VERSION ""

NS_ :

BS_:

BU_: WSGW VCM TBIOM RCIOM FCIOM CCIOM BPMU

BO_ 517 RCIOM_Chassi_01P: 8 RCIOM
 SG_ FrontProhibitControlRequest : 4|2@1+ (1,0) [0|0] ""  CCIOM,VCM
 SG_ RampLevelStorageAck_ISig_4 : 24|2@1+ (1,0) [0|0] ""  VCM
 SG_ BrakePressureSensorDemand_UB_ISi : 1|1@1+ (1,0) [0|0] ""  VCM
 SG_ FrontLimpHomeCmd : 50|3@1+ (1,0) [0|0] ""  VCM,CCIOM
 SG_ LiftingControlModeRearAxle : 18|2@1+ (1,0) [0|0] ""  VCM
 SG_ LoadDistributionChangeACK_ISig_4 : 56|3@1+ (1,0) [0|0] ""  VCM
 SG_ ECSStandbyAllowed_ISig_4 : 32|2@1+ (1,0) [0|0] ""  VCM
 SG_ LiftAxle2LiftFuncSelected_ISig_4 : 59|3@1+ (1,0) [0|0] ""  VCM
 SG_ LiftAxle2UpRequestACK_ISig_4 : 34|3@1+ (1,0) [0|0] ""  VCM
 SG_ ProhibitControlStatus_ISig_4 : 62|2@1+ (1,0) [0|0] ""  VCM
 SG_ RampLevelStatus_ISig_4 : 46|4@1+ (1,0) [0|0] ""  VCM
 SG_ StopLevelChangeAck_ISig_4 : 16|2@1+ (1,0) [0|0] ""  VCM
 SG_ LiftAxle2LowerACK_ISig_4 : 37|3@1+ (1,0) [0|0] ""  VCM
 SG_ RideHeightStorageAck_ISig_4 : 6|2@1+ (1,0) [0|0] ""  VCM
 SG_ FrontParkBrakeOverrideCommand : 22|2@1+ (1,0) [0|0] ""  VCM
 SG_ RideHeightOutsideTargetRange_ISi : 43|3@1+ (1,0) [0|0] ""  VCM
 SG_ DisableMechFaultDctnFr_rqst : 26|2@1+ (1,0) [0|0] ""  VCM,CCIOM
 SG_ RearAxleInBumperRange_UB_ISig_4 : 0|1@1+ (1,0) [0|0] ""  VCM
 SG_ BrakePressureSensorDemand_ISig_4 : 8|8@1+ (1,0) [0|255] "Percent"  VCM
 SG_ FogLamp_Rear_Status : 20|2@1+ (1,0) [0|0] ""  VCM
 SG_ LiftingControlModeFrontAxle : 2|2@1+ (1,0) [0|0] ""  VCM
 SG_ LiftAxle1UpRequestACK_ISig_4 : 40|3@1+ (1,0) [0|0] ""  VCM
 SG_ LiftAxle1LiftFuncSelected_ISig_4 : 53|3@1+ (1,0) [0|0] ""  VCM
 SG_ RearAxleInBumperRange_ISig_4 : 30|2@1+ (1,0) [0|0] ""  VCM

BO_ 2671833715 PhysDiagRespMsg_F2_73_C04: 8 WSGW
 SG_ PhysDiagRespSig_F2_73_ISig_4 : 0|64@1+ (1,0) [0|0] ""  VCM

BO_ 2671833639 PhysDiagRespMsg_F2_27_C04: 8 TBIOM
 SG_ PhysDiagRespSig_F2_27_ISig_4 : 0|64@1+ (1,0) [0|0] ""  VCM

BO_ 2671833634 PhysDiagRespMsg_F2_22_C04: 8 RCIOM
 SG_ PhysDiagRespSig_F2_22_ISig_4 : 0|64@1+ (1,0) [0|0] ""  VCM

BO_ 2671833633 PhysDiagRespMsg_F2_21_C04: 8 FCIOM
 SG_ PhysDiagRespSig_F2_21_ISig_4 : 0|64@1+ (1,0) [0|0] ""  VCM

BO_ 2671833632 PhysDiagRespMsg_F2_20_C04: 8 CCIOM
 SG_ PhysDiagRespSig_F2_20_ISig_4 : 0|64@1+ (1,0) [0|0] ""  VCM

BO_ 2671833626 PhysDiagRespMsg_F2_1A_C04: 8 BPMU
 SG_ PhysDiagRespSig_F2_1A_ISig_4 : 0|64@1+ (1,0) [0|0] ""  VCM

BO_ 2671801330 PhysDiagReqMsg_73_F2_C04: 8 VCM
 SG_ PhysDiagReqSig_73_F2_ISig_4 : 0|64@1+ (1,0) [0|0] ""  WSGW

BO_ 2671781874 PhysDiagReqMsg_27_F2_C04: 8 VCM
 SG_ PhysDiagReqSig_27_F2_ISig_4 : 0|64@1+ (1,0) [0|0] ""  TBIOM

BO_ 2671780594 PhysDiagReqMsg_22_F2_C04: 8 VCM
 SG_ PhysDiagReqSig_22_F2_ISig_4 : 0|64@1+ (1,0) [0|0] ""  RCIOM

BO_ 2671780338 PhysDiagReqMsg_21_F2_C04: 8 VCM
 SG_ PhysDiagReqSig_21_F2_ISig_4 : 0|64@1+ (1,0) [0|0] ""  FCIOM

BO_ 2671780082 PhysDiagReqMsg_20_F2_C04: 8 VCM
 SG_ PhysDiagReqSig_20_F2_ISig_4 : 0|64@1+ (1,0) [0|0] ""  CCIOM

BO_ 2671778546 PhysDiagReqMsg_1A_F2_C04: 8 VCM
 SG_ PhysDiagReqSig_1A_F2_ISig_4 : 0|64@1+ (1,0) [0|0] ""  BPMU

BO_ 2633990259 NmAsr_WSGW_C04: 1 WSGW

BO_ 2633990180 NmAsr_VCM_C04: 1 VCM

BO_ 2633990183 NmAsr_TBIOM_C04: 1 TBIOM

BO_ 2633990178 NmAsr_RCIOM_C04: 1 RCIOM

BO_ 2633990177 NmAsr_FCIOM_C04: 1 FCIOM

BO_ 2633990176 NmAsr_CCIOM_C04: 1 CCIOM

BO_ 2633990170 NmAsr_BPMU_C04: 1 BPMU

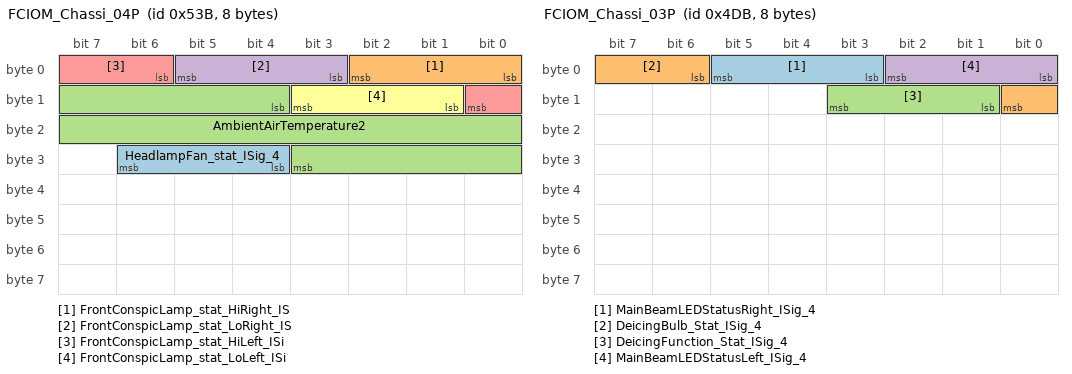
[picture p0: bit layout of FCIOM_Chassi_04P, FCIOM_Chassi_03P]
BO_ 1339 FCIOM_Chassi_04P: 8 FCIOM
 SG_ HeadlampFan_stat_ISig_4 : 28|3@1+ (1,0) [0|0] ""  VCM
 SG_ FrontConspicLamp_stat_HiRight_IS : 0|3@1+ (1,0) [0|0] ""  VCM
 SG_ AmbientAirTemperature2 : 12|16@1+ (0.03125,-273) [-273|1774.96875] "DegreeC"  VCM
 SG_ FrontConspicLamp_stat_LoRight_IS : 3|3@1+ (1,0) [0|0] ""  VCM
 SG_ FrontConspicLamp_stat_HiLeft_ISi : 6|3@1+ (1,0) [0|0] ""  VCM
 SG_ FrontConspicLamp_stat_LoLeft_ISi : 9|3@1+ (1,0) [0|0] ""  VCM

BO_ 1243 FCIOM_Chassi_03P: 8 FCIOM
 SG_ MainBeamLEDStatusRight_ISig_4 : 3|3@1+ (1,0) [0|0] ""  VCM
 SG_ DeicingBulb_Stat_ISig_4 : 6|3@1+ (1,0) [0|0] ""  VCM
 SG_ DeicingFunction_Stat_ISig_4 : 9|3@1+ (1,0) [0|0] ""  VCM
 SG_ MainBeamLEDStatusLeft_ISig_4 : 0|3@1+ (1,0) [0|0] ""  VCM

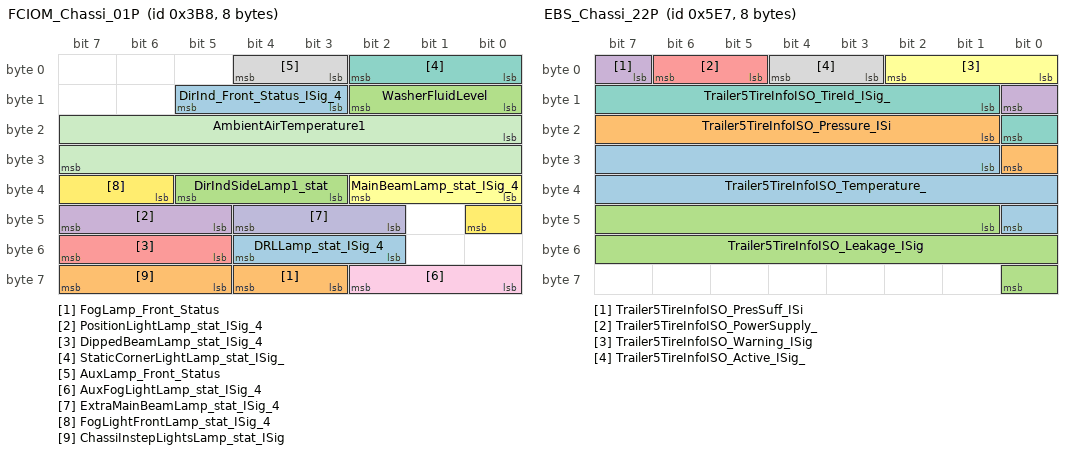
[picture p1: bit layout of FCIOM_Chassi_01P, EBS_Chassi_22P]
BO_ 952 FCIOM_Chassi_01P: 8 FCIOM
 SG_ DRLLamp_stat_ISig_4 : 50|3@1+ (1,0) [0|0] ""  VCM
 SG_ FogLamp_Front_Status : 59|2@1+ (1,0) [0|0] ""  VCM
 SG_ DirIndSideLamp1_stat : 35|3@1+ (1,0) [0|0] ""  VCM
 SG_ PositionLightLamp_stat_ISig_4 : 45|3@1+ (1,0) [0|0] ""  VCM
 SG_ DippedBeamLamp_stat_ISig_4 : 53|3@1+ (1,0) [0|0] ""  VCM
 SG_ MainBeamLamp_stat_ISig_4 : 32|3@1+ (1,0) [0|0] ""  VCM
 SG_ StaticCornerLightLamp_stat_ISig_ : 0|3@1+ (1,0) [0|0] ""  VCM
 SG_ AuxLamp_Front_Status : 3|2@1+ (1,0) [0|0] ""  VCM
 SG_ AuxFogLightLamp_stat_ISig_4 : 56|3@1+ (1,0) [0|0] ""  VCM
 SG_ ExtraMainBeamLamp_stat_ISig_4 : 42|3@1+ (1,0) [0|0] ""  VCM
 SG_ AmbientAirTemperature1 : 16|16@1+ (0.03125,-273) [-273|1774.96875] "DegreeC"  VCM
 SG_ FogLightFrontLamp_stat_ISig_4 : 38|3@1+ (1,0) [0|0] ""  VCM
 SG_ DirInd_Front_Status_ISig_4 : 11|3@1+ (1,0) [0|0] ""  VCM
 SG_ ChassiInstepLightsLamp_stat_ISig : 61|3@1+ (1,0) [0|0] ""  VCM
 SG_ WasherFluidLevel : 8|3@1+ (1,0) [0|0] ""  VCM

BO_ 1511 EBS_Chassi_22P: 8 VCM
 SG_ Trailer5TireInfoISO_Temperature_ : 25|16@1+ (0.03125,-273) [-273|1774.96875] "DegreeC"  WSGW
 SG_ Trailer5TireInfoISO_Pressure_ISi : 17|8@1+ (10,0) [0|2550] "kPa"  WSGW
 SG_ Trailer5TireInfoISO_Leakage_ISig : 41|16@1+ (0.1,0) [0|6553.5] "Pa_per_s"  WSGW
 SG_ Trailer5TireInfoISO_PresSuff_ISi : 7|2@1+ (1,0) [0|0] ""  WSGW
 SG_ Trailer5TireInfoISO_PowerSupply_ : 5|2@1+ (1,0) [0|0] ""  WSGW
 SG_ Trailer5TireInfoISO_Warning_ISig : 0|3@1+ (1,0) [0|0] ""  WSGW
 SG_ Trailer5TireInfoISO_TireId_ISig_ : 9|8@1+ (1,0) [0|255] "NotApplicable"  WSGW
 SG_ Trailer5TireInfoISO_Active_ISig_ : 3|2@1+ (1,0) [0|0] ""  WSGW

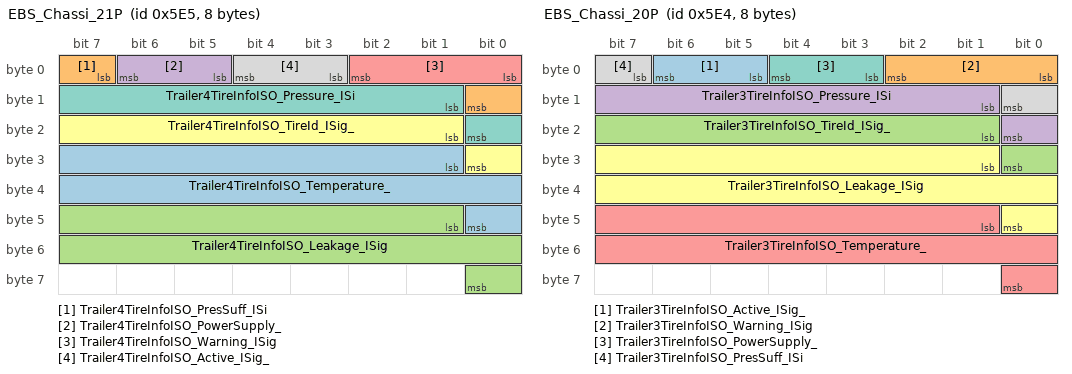
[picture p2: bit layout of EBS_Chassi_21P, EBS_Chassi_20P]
BO_ 1509 EBS_Chassi_21P: 8 VCM
 SG_ Trailer4TireInfoISO_Temperature_ : 25|16@1+ (0.03125,-273) [-273|1774.96875] "DegreeC"  WSGW
 SG_ Trailer4TireInfoISO_PresSuff_ISi : 7|2@1+ (1,0) [0|0] ""  WSGW
 SG_ Trailer4TireInfoISO_Leakage_ISig : 41|16@1+ (0.1,0) [0|6553.5] "Pa_per_s"  WSGW
 SG_ Trailer4TireInfoISO_PowerSupply_ : 5|2@1+ (1,0) [0|0] ""  WSGW
 SG_ Trailer4TireInfoISO_Warning_ISig : 0|3@1+ (1,0) [0|0] ""  WSGW
 SG_ Trailer4TireInfoISO_TireId_ISig_ : 17|8@1+ (1,0) [0|255] "NotApplicable"  WSGW
 SG_ Trailer4TireInfoISO_Pressure_ISi : 9|8@1+ (10,0) [0|2550] "kPa"  WSGW
 SG_ Trailer4TireInfoISO_Active_ISig_ : 3|2@1+ (1,0) [0|0] ""  WSGW

BO_ 1508 EBS_Chassi_20P: 8 VCM
 SG_ Trailer3TireInfoISO_Active_ISig_ : 5|2@1+ (1,0) [0|0] ""  WSGW
 SG_ Trailer3TireInfoISO_Warning_ISig : 0|3@1+ (1,0) [0|0] ""  WSGW
 SG_ Trailer3TireInfoISO_TireId_ISig_ : 17|8@1+ (1,0) [0|255] "NotApplicable"  WSGW
 SG_ Trailer3TireInfoISO_Pressure_ISi : 9|8@1+ (10,0) [0|2550] "kPa"  WSGW
 SG_ Trailer3TireInfoISO_Temperature_ : 41|16@1+ (0.03125,-273) [-273|1774.96875] "DegreeC"  WSGW
 SG_ Trailer3TireInfoISO_Leakage_ISig : 25|16@1+ (0.1,0) [0|6553.5] "Pa_per_s"  WSGW
 SG_ Trailer3TireInfoISO_PowerSupply_ : 3|2@1+ (1,0) [0|0] ""  WSGW
 SG_ Trailer3TireInfoISO_PresSuff_ISi : 7|2@1+ (1,0) [0|0] ""  WSGW

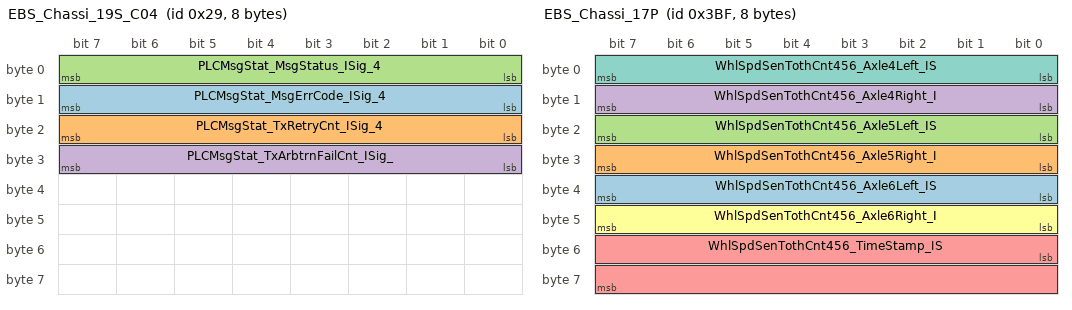
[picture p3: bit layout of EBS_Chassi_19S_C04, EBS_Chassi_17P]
BO_ 41 EBS_Chassi_19S_C04: 8 VCM
 SG_ PLCMsgStat_MsgErrCode_ISig_4 : 8|8@1+ (1,0) [0|255] "NotApplicable"  WSGW
 SG_ PLCMsgStat_TxRetryCnt_ISig_4 : 16|8@1+ (1,0) [0|255] "NotApplicable"  WSGW
 SG_ PLCMsgStat_MsgStatus_ISig_4 : 0|8@1+ (1,0) [0|255] "NotApplicable"  WSGW
 SG_ PLCMsgStat_TxArbtrnFailCnt_ISig_ : 24|8@1+ (1,0) [0|255] "NotApplicable"  WSGW

BO_ 1506 EBS_Chassi_18S_C04_FCM: 8 WSGW
 SG_ EBS_Chassi_18S_FCS : 0|64@1+ (1,0) [0|0] ""  VCM

BO_ 1505 EBS_Chassi_18S_C04: 21 VCM
 SG_ PhyDiagBrk2TPMReqSig_ISig_4 : 0|168@1+ (1,0) [0|0] ""  WSGW

BO_ 959 EBS_Chassi_17P: 8 VCM
 SG_ WhlSpdSenTothCnt456_Axle6Left_IS : 32|8@1+ (1,0) [0|255] "Count"  WSGW
 SG_ WhlSpdSenTothCnt456_Axle5Right_I : 24|8@1+ (1,0) [0|255] "Count"  WSGW
 SG_ WhlSpdSenTothCnt456_Axle5Left_IS : 16|8@1+ (1,0) [0|255] "Count"  WSGW
 SG_ WhlSpdSenTothCnt456_Axle4Right_I : 8|8@1+ (1,0) [0|255] "Count"  WSGW
 SG_ WhlSpdSenTothCnt456_TimeStamp_IS : 48|16@1+ (1,0) [0|65535] ""  WSGW
 SG_ WhlSpdSenTothCnt456_Axle6Right_I : 40|8@1+ (1,0) [0|255] "Count"  WSGW
 SG_ WhlSpdSenTothCnt456_Axle4Left_IS : 0|8@1+ (1,0) [0|255] "Count"  WSGW

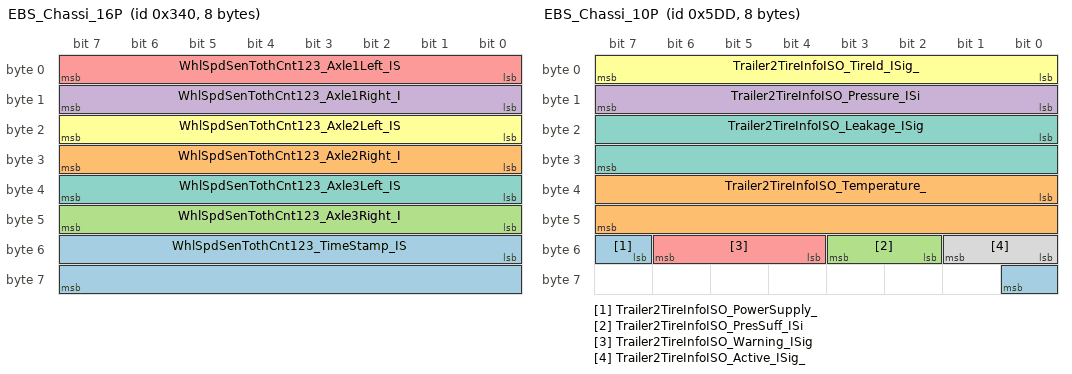
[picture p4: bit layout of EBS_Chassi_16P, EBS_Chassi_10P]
BO_ 832 EBS_Chassi_16P: 8 VCM
 SG_ WhlSpdSenTothCnt123_TimeStamp_IS : 48|16@1+ (1,0) [0|65535] ""  WSGW
 SG_ WhlSpdSenTothCnt123_Axle2Right_I : 24|8@1+ (1,0) [0|255] "Count"  WSGW
 SG_ WhlSpdSenTothCnt123_Axle3Right_I : 40|8@1+ (1,0) [0|255] "Count"  WSGW
 SG_ WhlSpdSenTothCnt123_Axle1Right_I : 8|8@1+ (1,0) [0|255] "Count"  WSGW
 SG_ WhlSpdSenTothCnt123_Axle1Left_IS : 0|8@1+ (1,0) [0|255] "Count"  WSGW
 SG_ WhlSpdSenTothCnt123_Axle2Left_IS : 16|8@1+ (1,0) [0|255] "Count"  WSGW
 SG_ WhlSpdSenTothCnt123_Axle3Left_IS : 32|8@1+ (1,0) [0|255] "Count"  WSGW

BO_ 1232 EBS_Chassi_13P: 8 VCM
 SG_ TrailerCommunicationType_ISig_4 : 26|3@1+ (1,0) [0|0] ""  RCIOM

BO_ 1507 EBS_Chassi_12P: 8 VCM
 SG_ PLCBusStatus_ISig_4 : 16|8@1+ (1,0) [0|255] "NotApplicable"  WSGW

BO_ 1501 EBS_Chassi_10P: 8 VCM
 SG_ Trailer2TireInfoISO_PowerSupply_ : 55|2@1+ (1,0) [0|0] ""  WSGW
 SG_ Trailer2TireInfoISO_Temperature_ : 32|16@1+ (0.03125,-273) [-273|1774.96875] "DegreeC"  WSGW
 SG_ Trailer2TireInfoISO_PresSuff_ISi : 50|2@1+ (1,0) [0|0] ""  WSGW
 SG_ Trailer2TireInfoISO_Pressure_ISi : 8|8@1+ (10,0) [0|2550] "kPa"  WSGW
 SG_ Trailer2TireInfoISO_Warning_ISig : 52|3@1+ (1,0) [0|0] ""  WSGW
 SG_ Trailer2TireInfoISO_TireId_ISig_ : 0|8@1+ (1,0) [0|255] "NotApplicable"  WSGW
 SG_ Trailer2TireInfoISO_Leakage_ISig : 16|16@1+ (0.1,0) [0|6553.5] "Pa_per_s"  WSGW
 SG_ Trailer2TireInfoISO_Active_ISig_ : 48|2@1+ (1,0) [0|0] ""  WSGW

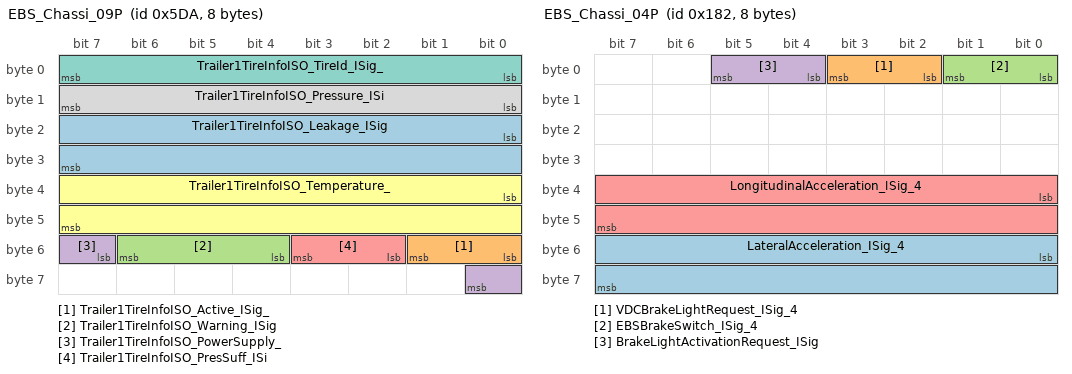
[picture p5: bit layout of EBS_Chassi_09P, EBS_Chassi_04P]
BO_ 1498 EBS_Chassi_09P: 8 VCM
 SG_ Trailer1TireInfoISO_Leakage_ISig : 16|16@1+ (0.1,0) [0|6553.5] "Pa_per_s"  WSGW
 SG_ Trailer1TireInfoISO_Active_ISig_ : 48|2@1+ (1,0) [0|0] ""  WSGW
 SG_ Trailer1TireInfoISO_Warning_ISig : 52|3@1+ (1,0) [0|0] ""  WSGW
 SG_ Trailer1TireInfoISO_PowerSupply_ : 55|2@1+ (1,0) [0|0] ""  WSGW
 SG_ Trailer1TireInfoISO_PresSuff_ISi : 50|2@1+ (1,0) [0|0] ""  WSGW
 SG_ Trailer1TireInfoISO_Temperature_ : 32|16@1+ (0.03125,-273) [-273|1774.96875] "DegreeC"  WSGW
 SG_ Trailer1TireInfoISO_TireId_ISig_ : 0|8@1+ (1,0) [0|255] "NotApplicable"  WSGW
 SG_ Trailer1TireInfoISO_Pressure_ISi : 8|8@1+ (10,0) [0|2550] "kPa"  WSGW

BO_ 396 EBS_Chassi_08P: 8 VCM
 SG_ ThrdRrDriveAxLeftWheelSpeed_ISig : 32|16@1+ (0.00390625,0) [0|255.99609375] "Km_per_h"  RCIOM
 SG_ ThrdRrDriveAxRightWheelSpeed_ISi : 48|16@1+ (0.00390625,0) [0|255.99609375] "Km_per_h"  RCIOM

BO_ 395 EBS_Chassi_07P: 8 VCM
 SG_ SteeringWheelAngle_ISig_4 : 0|16@1+ (0.0009765625,-31.374) [-31.374|32.6250234375] "rad"  RCIOM
 SG_ SteeringWheelAngle_UB_ISig_4 : 48|1@1+ (1,0) [0|0] ""  RCIOM

BO_ 394 EBS_Chassi_06P: 8 VCM
 SG_ ScndRrDriveAxleLeftWheelSpeed_IS : 48|16@1+ (0.00390625,0) [0|255.99609375] "Km_per_h"  CCIOM,RCIOM
 SG_ ScndRrDriveAxleRightWheelSpeed_I : 0|16@1+ (0.00390625,0) [0|255.99609375] "Km_per_h"  RCIOM,CCIOM

BO_ 386 EBS_Chassi_04P: 8 VCM
 SG_ LateralAcceleration_ISig_4 : 48|16@1+ (0.00048828125,-15.687) [-15.687|16.31251171875] "m_per_s_squared"  RCIOM
 SG_ VDCBrakeLightRequest_ISig_4 : 2|2@1+ (1,0) [0|0] ""  RCIOM
 SG_ EBSBrakeSwitch_ISig_4 : 0|2@1+ (1,0) [0|0] ""  RCIOM
 SG_ BrakeLightActivationRequest_ISig : 4|2@1+ (1,0) [0|0] ""  RCIOM
 SG_ LongitudinalAcceleration_ISig_4 : 32|16@1+ (0.00048828125,-15.687) [-15.687|16.31251171875] "m_per_s_squared"  RCIOM

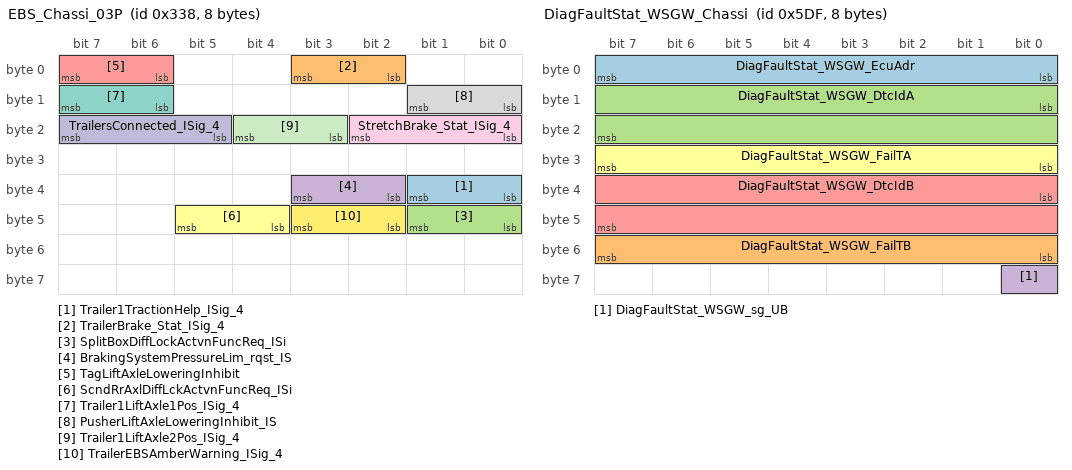
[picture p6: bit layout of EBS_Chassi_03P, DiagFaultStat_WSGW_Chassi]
BO_ 824 EBS_Chassi_03P: 8 VCM
 SG_ Trailer1TractionHelp_ISig_4 : 32|2@1+ (1,0) [0|0] ""  RCIOM
 SG_ TrailerBrake_Stat_ISig_4 : 2|2@1+ (1,0) [0|0] ""  RCIOM
 SG_ SplitBoxDiffLockActvnFuncReq_ISi : 40|2@1+ (1,0) [0|0] ""  CCIOM
 SG_ BrakingSystemPressureLim_rqst_IS : 34|2@1+ (1,0) [0|0] ""  CCIOM
 SG_ TagLiftAxleLoweringInhibit : 6|2@1+ (1,0) [0|0] ""  RCIOM
 SG_ ScndRrAxlDiffLckActvnFuncReq_ISi : 44|2@1+ (1,0) [0|0] ""  RCIOM
 SG_ Trailer1LiftAxle1Pos_ISig_4 : 14|2@1+ (1,0) [0|0] ""  RCIOM
 SG_ PusherLiftAxleLoweringInhibit_IS : 8|2@1+ (1,0) [0|0] ""  RCIOM
 SG_ StretchBrake_Stat_ISig_4 : 16|3@1+ (1,0) [0|0] ""  RCIOM
 SG_ TrailersConnected_ISig_4 : 21|3@1+ (1,0) [0|7] "Count"  RCIOM
 SG_ Trailer1LiftAxle2Pos_ISig_4 : 19|2@1+ (1,0) [0|0] ""  RCIOM
 SG_ TrailerEBSAmberWarning_ISig_4 : 42|2@1+ (1,0) [0|0] ""  RCIOM

BO_ 516 EAS_Chassi_01P: 8 VCM
 SG_ EASPusherLiftAxleLoweringInhib : 32|2@1+ (1,0) [0|0] ""  RCIOM

BO_ 2671964787 DiagUUDTRespMsg1_F2_73_C04: 8 WSGW
 SG_ DiagUUDTRespSig_F2_73_ISig_4 : 0|64@1+ (1,0) [0|0] ""  VCM

BO_ 2671964711 DiagUUDTRespMsg1_F2_27_C04: 8 TBIOM
 SG_ DiagUUDTRespSig_F2_27_ISig_4 : 0|64@1+ (1,0) [0|0] ""  VCM

BO_ 2671964706 DiagUUDTRespMsg1_F2_22_C04: 8 RCIOM
 SG_ DiagUUDTRespSig_F2_22_ISig_4 : 0|64@1+ (1,0) [0|0] ""  VCM

BO_ 2671964705 DiagUUDTRespMsg1_F2_21_C04: 8 FCIOM
 SG_ DiagUUDTRespSig_F2_21_ISig_4 : 0|64@1+ (1,0) [0|0] ""  VCM

BO_ 2671964704 DiagUUDTRespMsg1_F2_20_C04: 8 CCIOM
 SG_ DiagUUDTRespSig_F2_20_ISig_4 : 0|64@1+ (1,0) [0|0] ""  VCM

BO_ 2671964698 DiagUUDTRespMsg1_F2_1A_C04: 8 BPMU
 SG_ DiagUUDTRespSig_F2_1A_ISig_4 : 0|64@1+ (1,0) [0|0] ""  VCM

BO_ 2671834227 DiagRespMsgForIntTest_F4_73_C04: 8 WSGW
 SG_ InternalTesterDiagSig_F4_73 : 0|64@1+ (1,0) [0|0] ""  VCM

BO_ 2671834151 DiagRespMsgForIntTest_F4_27_C04: 8 TBIOM
 SG_ InternalTesterDiagSig_F4_27 : 0|64@1+ (1,0) [0|0] ""  VCM

BO_ 2671834146 DiagRespMsgForIntTest_F4_22_C04: 8 RCIOM
 SG_ InternalTesterDiagSig_F4_22 : 0|64@1+ (1,0) [0|0] ""  VCM

BO_ 2671834145 DiagRespMsgForIntTest_F4_21_C04: 8 FCIOM
 SG_ InternalTesterDiagSig_F4_21 : 0|64@1+ (1,0) [0|0] ""  VCM

BO_ 2671834144 DiagRespMsgForIntTest_F4_20_C04: 8 CCIOM
 SG_ InternalTesterDiagSig_F4_20 : 0|64@1+ (1,0) [0|0] ""  VCM

BO_ 2671834138 DiagRespMsgForIntTest_F4_1A_C04: 8 BPMU
 SG_ InternalTesterDiagSig_F4_1A : 0|64@1+ (1,0) [0|0] ""  VCM

BO_ 2671801332 DiagReqMsgOfIntTest_73_F4_C04: 8 VCM
 SG_ InternalTesterDiagSig_73_F4 : 0|64@1+ (1,0) [0|0] ""  WSGW

BO_ 2671781876 DiagReqMsgOfIntTest_27_F4_C04: 8 VCM
 SG_ InternalTesterDiagSig_27_F4 : 0|64@1+ (1,0) [0|0] ""  TBIOM

BO_ 2671780596 DiagReqMsgOfIntTest_22_F4_C04: 8 VCM
 SG_ InternalTesterDiagSig_22_F4 : 0|64@1+ (1,0) [0|0] ""  RCIOM

BO_ 2671780340 DiagReqMsgOfIntTest_21_F4_C04: 8 VCM
 SG_ InternalTesterDiagSig_21_F4 : 0|64@1+ (1,0) [0|0] ""  FCIOM

BO_ 2671780084 DiagReqMsgOfIntTest_20_F4_C04: 8 VCM
 SG_ InternalTesterDiagSig_20_F4 : 0|64@1+ (1,0) [0|0] ""  CCIOM

BO_ 2671778548 DiagReqMsgOfIntTest_1A_F4_C04: 8 VCM
 SG_ InternalTesterDiagSig_1A_F4 : 0|64@1+ (1,0) [0|0] ""  BPMU

BO_ 1503 DiagFaultStat_WSGW_Chassi: 8 WSGW
 SG_ DiagFaultStat_WSGW_EcuAdr : 0|8@1+ (1,0) [0|255] ""  VCM
 SG_ DiagFaultStat_WSGW_FailTB : 48|8@1+ (1,0) [0|255] ""  VCM
 SG_ DiagFaultStat_WSGW_DtcIdA : 8|16@1+ (1,0) [0|65535] ""  VCM
 SG_ DiagFaultStat_WSGW_sg_UB : 56|1@1+ (1,0) [0|0] ""  VCM
 SG_ DiagFaultStat_WSGW_DtcIdB : 32|16@1+ (1,0) [0|65535] ""  VCM
 SG_ DiagFaultStat_WSGW_FailTA : 24|8@1+ (1,0) [0|255] ""  VCM

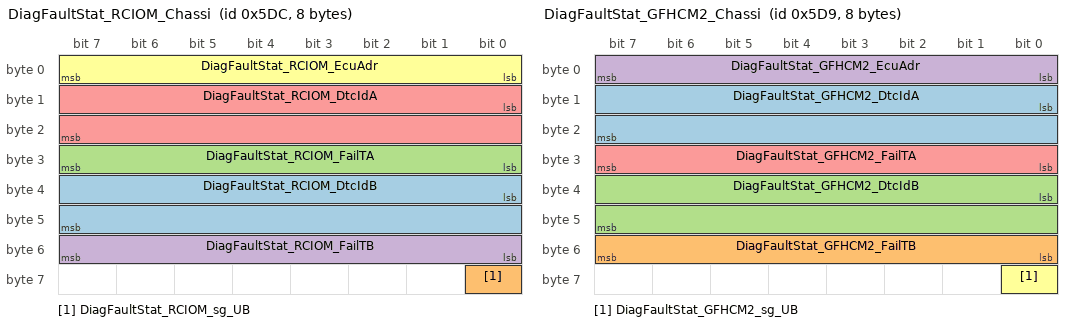
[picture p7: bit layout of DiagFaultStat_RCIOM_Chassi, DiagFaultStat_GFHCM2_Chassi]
BO_ 1500 DiagFaultStat_RCIOM_Chassi: 8 RCIOM
 SG_ DiagFaultStat_RCIOM_DtcIdB : 32|16@1+ (1,0) [0|65535] ""  VCM
 SG_ DiagFaultStat_RCIOM_sg_UB : 56|1@1+ (1,0) [0|0] ""  VCM
 SG_ DiagFaultStat_RCIOM_FailTA : 24|8@1+ (1,0) [0|255] ""  VCM
 SG_ DiagFaultStat_RCIOM_FailTB : 48|8@1+ (1,0) [0|255] ""  VCM
 SG_ DiagFaultStat_RCIOM_DtcIdA : 8|16@1+ (1,0) [0|65535] ""  VCM
 SG_ DiagFaultStat_RCIOM_EcuAdr : 0|8@1+ (1,0) [0|255] ""  VCM

BO_ 1497 DiagFaultStat_GFHCM2_Chassi: 8 FCIOM
 SG_ DiagFaultStat_GFHCM2_DtcIdA : 8|16@1+ (1,0) [0|65535] ""  VCM
 SG_ DiagFaultStat_GFHCM2_FailTB : 48|8@1+ (1,0) [0|255] ""  VCM
 SG_ DiagFaultStat_GFHCM2_DtcIdB : 32|16@1+ (1,0) [0|65535] ""  VCM
 SG_ DiagFaultStat_GFHCM2_EcuAdr : 0|8@1+ (1,0) [0|255] ""  VCM
 SG_ DiagFaultStat_GFHCM2_FailTA : 24|8@1+ (1,0) [0|255] ""  VCM
 SG_ DiagFaultStat_GFHCM2_sg_UB : 56|1@1+ (1,0) [0|0] ""  VCM

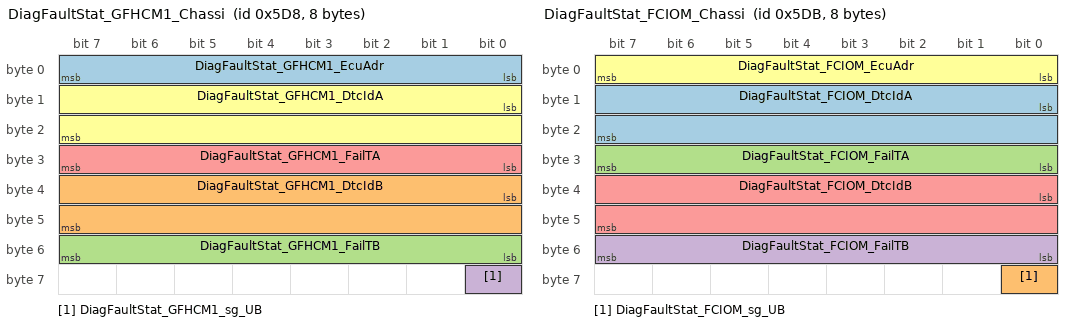
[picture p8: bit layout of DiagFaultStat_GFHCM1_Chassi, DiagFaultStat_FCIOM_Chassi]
BO_ 1496 DiagFaultStat_GFHCM1_Chassi: 8 FCIOM
 SG_ DiagFaultStat_GFHCM1_EcuAdr : 0|8@1+ (1,0) [0|255] ""  VCM
 SG_ DiagFaultStat_GFHCM1_DtcIdB : 32|16@1+ (1,0) [0|65535] ""  VCM
 SG_ DiagFaultStat_GFHCM1_FailTB : 48|8@1+ (1,0) [0|255] ""  VCM
 SG_ DiagFaultStat_GFHCM1_sg_UB : 56|1@1+ (1,0) [0|0] ""  VCM
 SG_ DiagFaultStat_GFHCM1_FailTA : 24|8@1+ (1,0) [0|255] ""  VCM
 SG_ DiagFaultStat_GFHCM1_DtcIdA : 8|16@1+ (1,0) [0|65535] ""  VCM

BO_ 1499 DiagFaultStat_FCIOM_Chassi: 8 FCIOM
 SG_ DiagFaultStat_FCIOM_DtcIdA : 8|16@1+ (1,0) [0|65535] ""  VCM
 SG_ DiagFaultStat_FCIOM_sg_UB : 56|1@1+ (1,0) [0|0] ""  VCM
 SG_ DiagFaultStat_FCIOM_FailTA : 24|8@1+ (1,0) [0|255] ""  VCM
 SG_ DiagFaultStat_FCIOM_FailTB : 48|8@1+ (1,0) [0|255] ""  VCM
 SG_ DiagFaultStat_FCIOM_DtcIdB : 32|16@1+ (1,0) [0|65535] ""  VCM
 SG_ DiagFaultStat_FCIOM_EcuAdr : 0|8@1+ (1,0) [0|255] ""  VCM

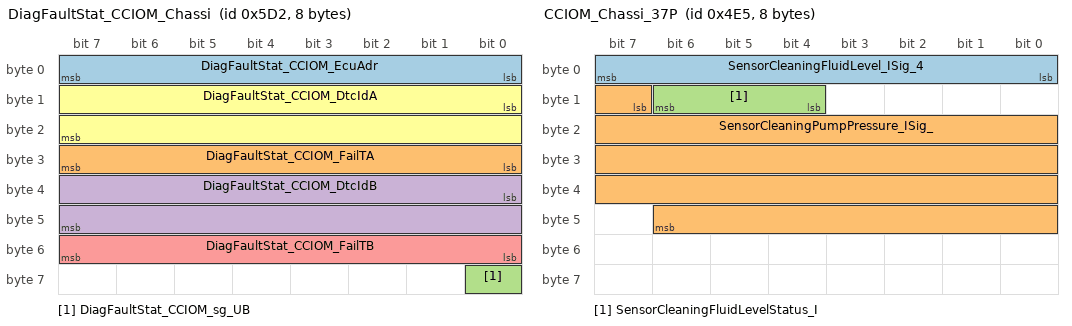
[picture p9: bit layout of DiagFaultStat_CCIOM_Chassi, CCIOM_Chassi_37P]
BO_ 1490 DiagFaultStat_CCIOM_Chassi: 8 CCIOM
 SG_ DiagFaultStat_CCIOM_EcuAdr : 0|8@1+ (1,0) [0|255] ""  VCM
 SG_ DiagFaultStat_CCIOM_FailTA : 24|8@1+ (1,0) [0|255] ""  VCM
 SG_ DiagFaultStat_CCIOM_sg_UB : 56|1@1+ (1,0) [0|0] ""  VCM
 SG_ DiagFaultStat_CCIOM_DtcIdB : 32|16@1+ (1,0) [0|65535] ""  VCM
 SG_ DiagFaultStat_CCIOM_FailTB : 48|8@1+ (1,0) [0|255] ""  VCM
 SG_ DiagFaultStat_CCIOM_DtcIdA : 8|16@1+ (1,0) [0|65535] ""  VCM

BO_ 1952 Debug9_RCIOM_Chassi: 8 RCIOM
 SG_ Debug_9_RCIOM : 0|64@1+ (1,0) [0|0] "" Vector__XXX

BO_ 1951 Debug9_CCIOM_Chassi: 8 CCIOM
 SG_ Debug_9_CCIOM : 0|64@1+ (1,0) [0|0] "" Vector__XXX

BO_ 1947 Debug8_RCIOM_Chassi: 8 RCIOM
 SG_ Debug_8_RCIOM : 0|64@1+ (1,0) [0|0] "" Vector__XXX

BO_ 1946 Debug8_CCIOM_Chassi: 8 CCIOM
 SG_ Debug_8_CCIOM : 0|64@1+ (1,0) [0|0] "" Vector__XXX

BO_ 1942 Debug7_RCIOM_Chassi: 8 RCIOM
 SG_ Debug_7_RCIOM : 0|64@1+ (1,0) [0|0] "" Vector__XXX

BO_ 1941 Debug7_CCIOM_Chassi: 8 CCIOM
 SG_ Debug_7_CCIOM : 0|64@1+ (1,0) [0|0] "" Vector__XXX

BO_ 1935 Debug6_RCIOM_Chassi: 8 RCIOM
 SG_ Debug_6_RCIOM : 0|64@1+ (1,0) [0|0] "" Vector__XXX

BO_ 1933 Debug6_CCIOM_Chassi: 8 CCIOM
 SG_ Debug_6_CCIOM : 0|64@1+ (1,0) [0|0] "" Vector__XXX

BO_ 1927 Debug5_RCIOM_Chassi: 8 RCIOM
 SG_ Debug_5_RCIOM : 0|64@1+ (1,0) [0|0] "" Vector__XXX

BO_ 1925 Debug5_CCIOM_Chassi: 8 CCIOM
 SG_ Debug_5_CCIOM : 0|64@1+ (1,0) [0|0] "" Vector__XXX

BO_ 1919 Debug4_RCIOM_Chassi: 8 RCIOM
 SG_ Debug_4_RCIOM : 0|64@1+ (1,0) [0|0] "" Vector__XXX

BO_ 1917 Debug4_CCIOM_Chassi: 8 CCIOM
 SG_ Debug_4_CCIOM : 0|64@1+ (1,0) [0|0] "" Vector__XXX

BO_ 1911 Debug3_RCIOM_Chassi: 8 RCIOM
 SG_ Debug_3_RCIOM : 0|64@1+ (1,0) [0|0] "" Vector__XXX

BO_ 1909 Debug3_CCIOM_Chassi: 8 CCIOM
 SG_ Debug_3_CCIOM : 0|64@1+ (1,0) [0|0] "" Vector__XXX

BO_ 1903 Debug2_RCIOM_Chassi: 8 RCIOM
 SG_ Debug_2_RCIOM : 0|64@1+ (1,0) [0|0] "" Vector__XXX

BO_ 1901 Debug2_CCIOM_Chassi: 8 CCIOM
 SG_ Debug_2_CCIOM : 0|64@1+ (1,0) [0|0] "" Vector__XXX

BO_ 1981 Debug20_RCIOM_Platform_Chassi: 8 RCIOM
 SG_ Debug_20_RCIOM_Platform : 0|64@1+ (1,0) [0|0] "" Vector__XXX

BO_ 1895 Debug1_RCIOM_Chassi: 8 Vector__XXX
 SG_ Debug_1_RCIOM : 0|64@1+ (1,0) [0|0] ""  RCIOM

BO_ 1893 Debug1_CCIOM_Chassi: 8 Vector__XXX
 SG_ Debug_1_CCIOM : 0|64@1+ (1,0) [0|0] ""  CCIOM

BO_ 1980 Debug19_RCIOMLights_Chassi: 8 RCIOM
 SG_ Debug_19_RCIOMLights : 0|64@1+ (1,0) [0|0] "" Vector__XXX

BO_ 1979 Debug18_RCIOMLights_Chassi: 8 RCIOM
 SG_ Debug_18_RCIOMLights : 0|64@1+ (1,0) [0|0] "" Vector__XXX

BO_ 1978 Debug17_RCIOMLights_Chassi: 8 RCIOM
 SG_ Debug_17_RCIOMLights : 0|64@1+ (1,0) [0|0] "" Vector__XXX

BO_ 1977 Debug16_RCIOMLights_Chassi: 8 RCIOM
 SG_ Debug_16_RCIOMLights : 0|64@1+ (1,0) [0|0] "" Vector__XXX

BO_ 1976 Debug15_RCIOMLights_Chassi: 8 RCIOM
 SG_ Debug_15_RCIOMLights : 0|64@1+ (1,0) [0|0] "" Vector__XXX

BO_ 1969 Debug15_FCIOM_Platform_Chassi: 8 FCIOM
 SG_ Debug_1_FCIOM_Platform : 0|64@1+ (1,0) [0|0] "" Vector__XXX

BO_ 1968 Debug15_CCIOM_Platform_Chassi: 8 CCIOM
 SG_ Debug_15_CCIOM_Platform : 0|64@1+ (1,0) [0|0] "" Vector__XXX

BO_ 1975 Debug14_RCIOMLights_Chassi: 8 RCIOM
 SG_ Debug_14_RCIOMLights : 0|64@1+ (1,0) [0|0] "" Vector__XXX

BO_ 1967 Debug14_CCIOMLights_Chassi: 8 CCIOM
 SG_ Debug14_CCIOMLights : 0|64@1+ (1,0) [0|0] "" Vector__XXX

BO_ 1974 Debug13_RCIOMLights_Chassi: 8 RCIOM
 SG_ Debug_13_RCIOMLights : 0|64@1+ (1,0) [0|0] "" Vector__XXX

BO_ 1965 Debug13_CCIOMLights_Chassi: 8 CCIOM
 SG_ Debug13_CCIOMLights : 0|64@1+ (1,0) [0|0] "" Vector__XXX

BO_ 1973 Debug12_RCIOMLights_Chassi: 8 RCIOM
 SG_ Debug_12_RCIOMLights : 0|64@1+ (1,0) [0|0] "" Vector__XXX

BO_ 1963 Debug12_CCIOM_Chassi: 8 CCIOM
 SG_ Debug_12_CCIOM : 0|64@1+ (1,0) [0|0] "" Vector__XXX

BO_ 1961 Debug11_RCIOM_Chassi: 8 RCIOM
 SG_ Debug_11_RCIOM : 0|64@1+ (1,0) [0|0] "" Vector__XXX

BO_ 1960 Debug11_CCIOM_Chassi: 8 CCIOM
 SG_ Debug_11_CCIOM : 0|64@1+ (1,0) [0|0] "" Vector__XXX

BO_ 1957 Debug10_RCIOM_Chassi: 8 RCIOM
 SG_ Debug_10_RCIOM : 0|64@1+ (1,0) [0|0] "" Vector__XXX

BO_ 1956 Debug10_CCIOM_Chassi: 8 CCIOM
 SG_ Debug_10_CCIOM : 0|64@1+ (1,0) [0|0] "" Vector__XXX

BO_ 1253 CCIOM_Chassi_37P: 8 CCIOM
 SG_ SensorCleaningFluidLevel_ISig_4 : 0|8@1+ (0.4,0) [0|102] "Percent"  VCM
 SG_ SensorCleaningPumpPressure_ISig_ : 15|32@1+ (0.001,0) [0|4294967.295] "Bar"  VCM
 SG_ SensorCleaningFluidLevelStatus_I : 12|3@1+ (1,0) [0|0] ""  VCM

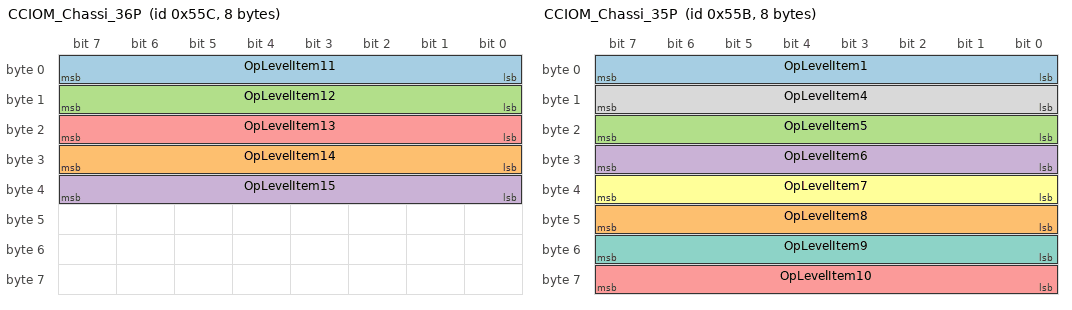
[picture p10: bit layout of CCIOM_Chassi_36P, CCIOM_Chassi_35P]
BO_ 1372 CCIOM_Chassi_36P: 8 CCIOM
 SG_ OpLevelItem11 : 0|8@1+ (0.5,0) [0|127.5] "Percent"  VCM
 SG_ OpLevelItem14 : 24|8@1+ (0.5,0) [0|127.5] "Percent"  VCM
 SG_ OpLevelItem12 : 8|8@1+ (0.5,0) [0|127.5] "Percent"  VCM
 SG_ OpLevelItem15 : 32|8@1+ (0.5,0) [0|127.5] "Percent"  VCM
 SG_ OpLevelItem13 : 16|8@1+ (0.5,0) [0|127.5] "Percent"  VCM

BO_ 1371 CCIOM_Chassi_35P: 8 CCIOM
 SG_ OpLevelItem1 : 0|8@1+ (0.5,0) [0|127.5] "Percent"  VCM
 SG_ OpLevelItem8 : 40|8@1+ (0.5,0) [0|127.5] "Percent"  VCM
 SG_ OpLevelItem5 : 16|8@1+ (0.5,0) [0|127.5] "Percent"  VCM
 SG_ OpLevelItem6 : 24|8@1+ (0.5,0) [0|127.5] "Percent"  VCM
 SG_ OpLevelItem10 : 56|8@1+ (0.5,0) [0|127.5] "Percent"  VCM
 SG_ OpLevelItem7 : 32|8@1+ (0.5,0) [0|127.5] "Percent"  VCM
 SG_ OpLevelItem9 : 48|8@1+ (0.5,0) [0|127.5] "Percent"  VCM
 SG_ OpLevelItem4 : 8|8@1+ (0.5,0) [0|127.5] "Percent"  VCM

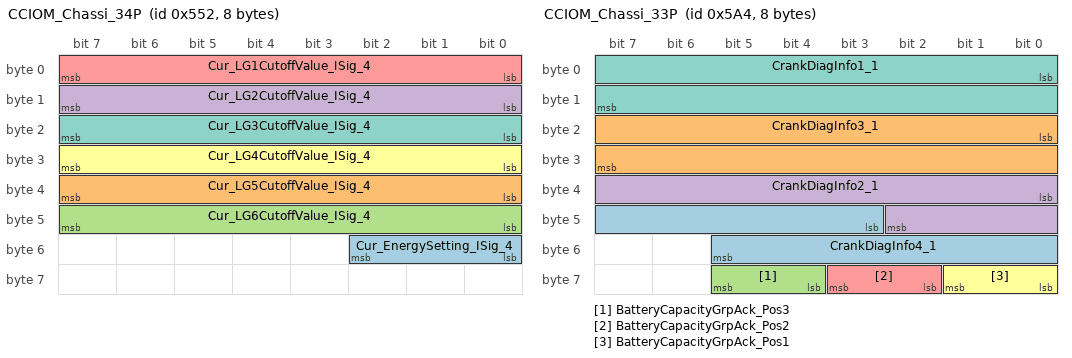
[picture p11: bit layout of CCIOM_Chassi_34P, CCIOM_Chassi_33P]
BO_ 1362 CCIOM_Chassi_34P: 8 CCIOM
 SG_ Cur_EnergySetting_ISig_4 : 48|3@1+ (1,0) [0|0] ""  VCM
 SG_ Cur_LG5CutoffValue_ISig_4 : 32|8@1+ (1,0) [0|255] "Percent"  VCM
 SG_ Cur_LG6CutoffValue_ISig_4 : 40|8@1+ (1,0) [0|255] "Percent"  VCM
 SG_ Cur_LG2CutoffValue_ISig_4 : 8|8@1+ (1,0) [0|255] "Percent"  VCM
 SG_ Cur_LG1CutoffValue_ISig_4 : 0|8@1+ (1,0) [0|255] "Percent"  VCM
 SG_ Cur_LG4CutoffValue_ISig_4 : 24|8@1+ (1,0) [0|255] "Percent"  VCM
 SG_ Cur_LG3CutoffValue_ISig_4 : 16|8@1+ (1,0) [0|255] "Percent"  VCM

BO_ 1444 CCIOM_Chassi_33P: 8 CCIOM
 SG_ CrankDiagInfo4_1 : 43|11@1+ (0.025,0) [0|51.175] "V"  VCM
 SG_ CrankDiagInfo3_1 : 16|16@1+ (0.05,-2000) [-2000|1276.75] "A"  VCM
 SG_ BatteryCapacityGrpAck_Pos3 : 60|2@1+ (1,0) [0|0] ""  VCM
 SG_ CrankDiagInfo2_1 : 32|11@1+ (0.025,0) [0|51.175] "V"  VCM
 SG_ BatteryCapacityGrpAck_Pos2 : 58|2@1+ (1,0) [0|0] ""  VCM
 SG_ BatteryCapacityGrpAck_Pos1 : 56|2@1+ (1,0) [0|0] ""  VCM
 SG_ CrankDiagInfo1_1 : 0|16@1+ (0.05,-2000) [-2000|1276.75] "A"  VCM

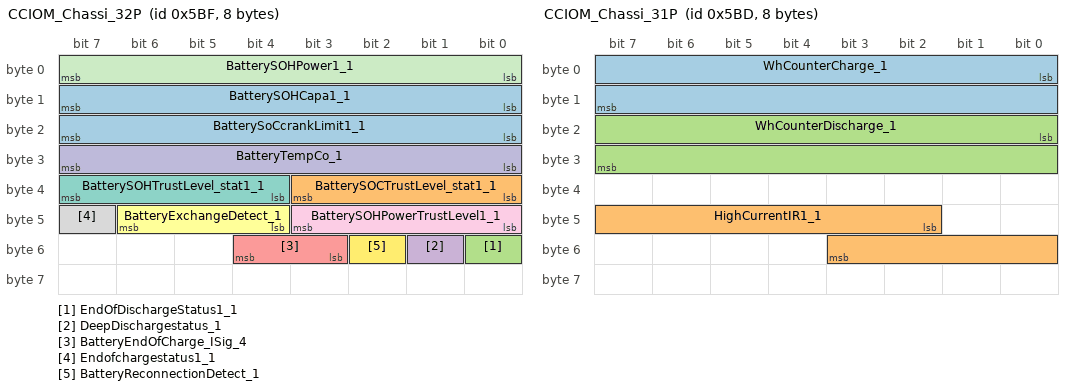
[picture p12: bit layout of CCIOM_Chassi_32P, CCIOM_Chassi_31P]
BO_ 1471 CCIOM_Chassi_32P: 8 CCIOM
 SG_ BatterySOHCapa1_1 : 8|8@1+ (0.5,0) [0|127.5] "Percent"  VCM
 SG_ BatterySOCTrustLevel_stat1_1 : 32|4@1+ (1,0) [0|0] ""  VCM
 SG_ EndOfDischargeStatus1_1 : 48|1@1+ (1,0) [0|0] ""  VCM
 SG_ DeepDischargestatus_1 : 49|1@1+ (1,0) [0|0] ""  VCM
 SG_ BatteryEndOfCharge_ISig_4 : 51|2@1+ (1,0) [0|0] ""  VCM
 SG_ BatteryExchangeDetect_1 : 44|3@1+ (1,0) [0|0] ""  VCM
 SG_ BatterySOHTrustLevel_stat1_1 : 36|4@1+ (1,0) [0|0] ""  VCM
 SG_ Endofchargestatus1_1 : 47|1@1+ (1,0) [0|0] ""  VCM
 SG_ BatterySOHPowerTrustLevel1_1 : 40|4@1+ (1,0) [0|0] ""  VCM
 SG_ BatteryTempCo_1 : 24|8@1+ (1,0) [0|255] "Percent"  VCM
 SG_ BatterySOHPower1_1 : 0|8@1+ (0.1,0) [0|25.5] "V"  VCM
 SG_ BatteryReconnectionDetect_1 : 50|1@1+ (1,0) [0|0] ""  VCM
 SG_ BatterySoCcrankLimit1_1 : 16|8@1+ (1,0) [0|255] "Percent"  VCM

BO_ 1469 CCIOM_Chassi_31P: 8 CCIOM
 SG_ WhCounterCharge_1 : 0|16@1+ (50,0) [0|3276750] "Wh"  VCM
 SG_ HighCurrentIR1_1 : 42|10@1+ (1E-005,0) [0|0.01023] "Ohm"  VCM
 SG_ WhCounterDischarge_1 : 16|16@1+ (50,0) [0|3276750] "Wh"  VCM

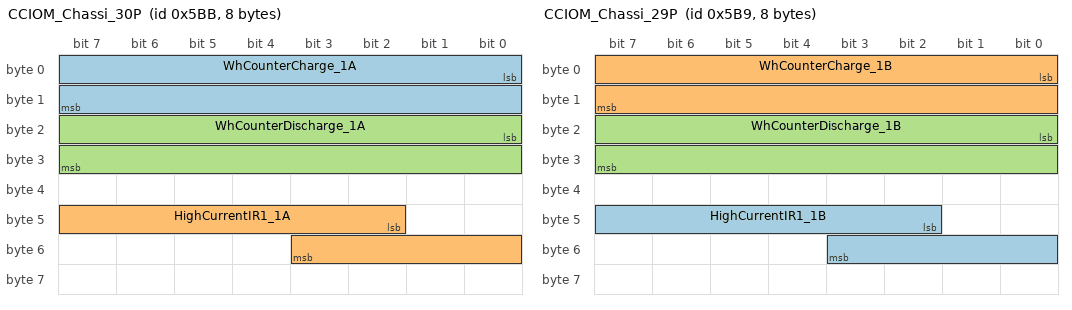
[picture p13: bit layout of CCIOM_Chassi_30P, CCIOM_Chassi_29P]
BO_ 1467 CCIOM_Chassi_30P: 8 CCIOM
 SG_ WhCounterCharge_1A : 0|16@1+ (50,0) [0|3276750] "Wh"  VCM
 SG_ HighCurrentIR1_1A : 42|10@1+ (1E-005,0) [0|0.01023] "Ohm"  VCM
 SG_ WhCounterDischarge_1A : 16|16@1+ (50,0) [0|3276750] "Wh"  VCM

BO_ 1465 CCIOM_Chassi_29P: 8 CCIOM
 SG_ HighCurrentIR1_1B : 42|10@1+ (1E-005,0) [0|0.01023] "Ohm"  VCM
 SG_ WhCounterCharge_1B : 0|16@1+ (50,0) [0|3276750] "Wh"  VCM
 SG_ WhCounterDischarge_1B : 16|16@1+ (50,0) [0|3276750] "Wh"  VCM

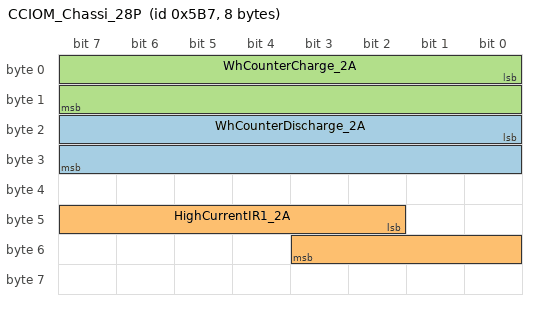
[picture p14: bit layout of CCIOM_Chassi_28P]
BO_ 1463 CCIOM_Chassi_28P: 8 CCIOM
 SG_ WhCounterDischarge_2A : 16|16@1+ (50,0) [0|3276750] "Wh"  VCM
 SG_ HighCurrentIR1_2A : 42|10@1+ (1E-005,0) [0|0.01023] "Ohm"  VCM
 SG_ WhCounterCharge_2A : 0|16@1+ (50,0) [0|3276750] "Wh"  VCM

CM_ SG_ 1511 Trailer5TireInfoISO_Temperature_ "64256-65023 Spare; 65024-65279 Error; 65280-65535 NotAvailable;";
CM_ SG_ 1511 Trailer5TireInfoISO_Pressure_ISi "251-253 Spare; 254 Error; 255 NotAvailable;";
CM_ SG_ 1511 Trailer5TireInfoISO_Leakage_ISig "64256-65023 Spare; 65024-65279 Error; 65280-65535 NotAvailable;";
CM_ SG_ 1509 Trailer4TireInfoISO_Temperature_ "64256-65023 Spare; 65024-65279 Error; 65280-65535 NotAvailable;";
CM_ SG_ 1509 Trailer4TireInfoISO_Leakage_ISig "64256-65023 Spare; 65024-65279 Error; 65280-65535 NotAvailable;";
CM_ SG_ 1509 Trailer4TireInfoISO_Pressure_ISi "251-253 Spare; 254 Error; 255 NotAvailable;";
CM_ SG_ 1508 Trailer3TireInfoISO_Pressure_ISi "251-253 Spare; 254 Error; 255 NotAvailable;";
CM_ SG_ 1508 Trailer3TireInfoISO_Temperature_ "64256-65023 Spare; 65024-65279 Error; 65280-65535 NotAvailable;";
CM_ SG_ 1508 Trailer3TireInfoISO_Leakage_ISig "64256-65023 Spare; 65024-65279 Error; 65280-65535 NotAvailable;";
CM_ SG_ 1501 Trailer2TireInfoISO_Temperature_ "64256-65023 Spare; 65024-65279 Error; 65280-65535 NotAvailable;";
CM_ SG_ 1501 Trailer2TireInfoISO_Pressure_ISi "251-253 Spare; 254 Error; 255 NotAvailable;";
CM_ SG_ 1501 Trailer2TireInfoISO_Leakage_ISig "64256-65023 Spare; 65024-65279 Error; 65280-65535 NotAvailable;";
CM_ SG_ 1498 Trailer1TireInfoISO_Leakage_ISig "64256-65023 Spare; 65024-65279 Error; 65280-65535 NotAvailable;";
CM_ SG_ 1498 Trailer1TireInfoISO_Temperature_ "64256-65023 Spare; 65024-65279 Error; 65280-65535 NotAvailable;";
CM_ SG_ 1498 Trailer1TireInfoISO_Pressure_ISi "251-253 Spare; 254 Error; 255 NotAvailable;";
BA_DEF_ BO_  "GenMsgStartDelayTime" INT 0 0;
BA_DEF_ BO_  "GenMsgDelayTime" INT 0 0;
BA_DEF_ BO_  "GenMsgCycleTime" INT 0 0;
BA_DEF_ BO_  "GenMsgSendType" ENUM  "Cyclic","NotUsed","NotUsed","NotUsed","NotUsed","NotUsed","NotUsed","IfActive","NoMsgSendType","NotUsed";
BA_DEF_ SG_  "GenSigStartValue" INT 0 0;
BA_DEF_ SG_  "GenSigInactiveValue" INT 0 0;
BA_DEF_ SG_  "GenSigCycleTimeActive" INT 0 0;
BA_DEF_ SG_  "GenSigCycleTime" INT 0 0;
BA_DEF_ SG_  "GenSigSendType" ENUM  "Cyclic","OnWrite","OnWriteWithRepetition","OnChange","OnChangeWithRepetition","IfActive","IfActiveWithRepetition","NoSigSendType","NotUsed","NotUsed","NotUsed","NotUsed","NotUsed";
BA_DEF_ BO_  "VFrameFormat" ENUM  "StandardCAN","ExtendedCAN","reserved","J1939PG","reserved","reserved","reserved","reserved","reserved","reserved","reserved","reserved","reserved","reserved","StandardCAN_FD","ExtendedCAN_FD";
BA_DEF_ SG_  "SigType" ENUM  "Default","Range","RangeSigned","ASCII","Discrete","Control","ReferencePGN","DTC","StringDelimiter","StringLength","StringLengthControl";
BA_DEF_ SG_  "Platform_Vivis2_Sig" ENUM  "No","Yes";
BA_DEF_ SG_  "Platform_VMCU1_Sig" ENUM  "No","Yes";
BA_DEF_ BO_  "NmAsrMessage" ENUM  "No","Yes";
BA_DEF_ SG_  "NeedsUpdateBit" ENUM  "No","Yes";
BA_DEF_ SG_  "MmAnSignal" ENUM  "No","Yes";
BA_DEF_ SG_  "GenSigMaxLatency" INT 0 65535;
BA_DEF_ SG_  "GenSigILSupport" ENUM  "Yes","No";
BA_DEF_ BO_  "GenMsgILSupport" ENUM  "No","Yes";
BA_DEF_ SG_  "E2EProfile" STRING ;
BA_DEF_ SG_  "E2EDataLength" INT 0 65535;
BA_DEF_ SG_  "E2EDataId" INT 0 65535;
BA_DEF_ BO_  "DiagUUDTResponse" ENUM  "No","Yes";
BA_DEF_ BO_  "DiagState" ENUM  "No","Yes";
BA_DEF_ BO_  "DiagResponse" ENUM  "No","Yes";
BA_DEF_ BO_  "DiagRequest" ENUM  "No","Yes";
BA_DEF_ BO_  "DiagConnection" HEX 0 65535;
BA_DEF_ BO_  "CanTpFcFrameId" HEX 0 2147483647;
BA_DEF_ BO_  "CanTpBs" INT 0 255;
BA_DEF_ SG_  "SystemSignalLongSymbol" STRING ;
BA_DEF_REL_ BU_SG_REL_  "GenSigTimeoutTime" INT 0 65535;
BA_DEF_REL_ BU_SG_REL_  "GenSigFirstTimeoutTime" INT 0 65535;
BA_DEF_DEF_  "GenMsgStartDelayTime" 0;
BA_DEF_DEF_  "GenMsgDelayTime" 0;
BA_DEF_DEF_  "GenMsgCycleTime" 0;
BA_DEF_DEF_  "GenMsgSendType" "Cyclic";
BA_DEF_DEF_  "GenSigStartValue" 0;
BA_DEF_DEF_  "GenSigInactiveValue" 0;
BA_DEF_DEF_  "GenSigCycleTimeActive" 0;
BA_DEF_DEF_  "GenSigCycleTime" 0;
BA_DEF_DEF_  "GenSigSendType" "Cyclic";
BA_DEF_DEF_  "VFrameFormat" "ExtendedCAN";
BA_DEF_DEF_  "SigType" "Default";
BA_DEF_DEF_  "Platform_Vivis2_Sig" "No";
BA_DEF_DEF_  "Platform_VMCU1_Sig" "No";
BA_DEF_DEF_  "NmAsrMessage" "No";
BA_DEF_DEF_  "NeedsUpdateBit" "No";
BA_DEF_DEF_  "MmAnSignal" "No";
BA_DEF_DEF_  "GenSigMaxLatency" 0;
BA_DEF_DEF_  "GenSigILSupport" "Yes";
BA_DEF_DEF_  "GenMsgILSupport" "Yes";
BA_DEF_DEF_  "E2EProfile" "none";
BA_DEF_DEF_  "E2EDataLength" 0;
BA_DEF_DEF_  "E2EDataId" 0;
BA_DEF_DEF_  "DiagUUDTResponse" "No";
BA_DEF_DEF_  "DiagState" "No";
BA_DEF_DEF_  "DiagResponse" "No";
BA_DEF_DEF_  "DiagRequest" "No";
BA_DEF_DEF_  "DiagConnection" 0;
BA_DEF_DEF_  "CanTpFcFrameId" 2147483647;
BA_DEF_DEF_  "CanTpBs" 255;
BA_DEF_DEF_REL_ "GenSigTimeoutTime" 0;
BA_DEF_DEF_REL_ "GenSigFirstTimeoutTime" 0;
BA_DEF_DEF_  "SystemSignalLongSymbol" "";
BA_ "VFrameFormat" BO_ 517 0;
BA_ "GenMsgCycleTime" BO_ 517 20;
BA_ "DiagConnection" BO_ 2671833715 62067;
BA_ "DiagResponse" BO_ 2671833715 1;
BA_ "GenMsgILSupport" BO_ 2671833715 0;
BA_ "GenMsgSendType" BO_ 2671833715 8;
BA_ "DiagConnection" BO_ 2671833639 61991;
BA_ "DiagResponse" BO_ 2671833639 1;
BA_ "GenMsgILSupport" BO_ 2671833639 0;
BA_ "GenMsgSendType" BO_ 2671833639 8;
BA_ "DiagConnection" BO_ 2671833634 61986;
BA_ "DiagResponse" BO_ 2671833634 1;
BA_ "GenMsgILSupport" BO_ 2671833634 0;
BA_ "GenMsgSendType" BO_ 2671833634 8;
BA_ "DiagConnection" BO_ 2671833633 61985;
BA_ "DiagResponse" BO_ 2671833633 1;
BA_ "GenMsgILSupport" BO_ 2671833633 0;
BA_ "GenMsgSendType" BO_ 2671833633 8;
BA_ "DiagConnection" BO_ 2671833632 61984;
BA_ "DiagResponse" BO_ 2671833632 1;
BA_ "GenMsgILSupport" BO_ 2671833632 0;
BA_ "GenMsgSendType" BO_ 2671833632 8;
BA_ "DiagConnection" BO_ 2671833626 61978;
BA_ "DiagResponse" BO_ 2671833626 1;
BA_ "GenMsgILSupport" BO_ 2671833626 0;
BA_ "GenMsgSendType" BO_ 2671833626 8;
BA_ "DiagConnection" BO_ 2671801330 62067;
BA_ "DiagRequest" BO_ 2671801330 1;
BA_ "GenMsgILSupport" BO_ 2671801330 0;
BA_ "GenMsgSendType" BO_ 2671801330 8;
BA_ "DiagConnection" BO_ 2671781874 61991;
BA_ "DiagRequest" BO_ 2671781874 1;
BA_ "GenMsgILSupport" BO_ 2671781874 0;
BA_ "GenMsgSendType" BO_ 2671781874 8;
BA_ "DiagConnection" BO_ 2671780594 61986;
BA_ "DiagRequest" BO_ 2671780594 1;
BA_ "GenMsgILSupport" BO_ 2671780594 0;
BA_ "GenMsgSendType" BO_ 2671780594 8;
BA_ "DiagConnection" BO_ 2671780338 61985;
BA_ "DiagRequest" BO_ 2671780338 1;
BA_ "GenMsgILSupport" BO_ 2671780338 0;
BA_ "GenMsgSendType" BO_ 2671780338 8;
BA_ "DiagConnection" BO_ 2671780082 61984;
BA_ "DiagRequest" BO_ 2671780082 1;
BA_ "GenMsgILSupport" BO_ 2671780082 0;
BA_ "GenMsgSendType" BO_ 2671780082 8;
BA_ "DiagConnection" BO_ 2671778546 61978;
BA_ "DiagRequest" BO_ 2671778546 1;
BA_ "GenMsgILSupport" BO_ 2671778546 0;
BA_ "GenMsgSendType" BO_ 2671778546 8;
BA_ "GenMsgILSupport" BO_ 2633990259 0;
BA_ "NmAsrMessage" BO_ 2633990259 1;
BA_ "GenMsgSendType" BO_ 2633990259 8;
BA_ "GenMsgILSupport" BO_ 2633990180 0;
BA_ "NmAsrMessage" BO_ 2633990180 1;
BA_ "GenMsgSendType" BO_ 2633990180 8;
BA_ "GenMsgILSupport" BO_ 2633990183 0;
BA_ "NmAsrMessage" BO_ 2633990183 1;
BA_ "GenMsgSendType" BO_ 2633990183 8;
BA_ "GenMsgILSupport" BO_ 2633990178 0;
BA_ "NmAsrMessage" BO_ 2633990178 1;
BA_ "GenMsgSendType" BO_ 2633990178 8;
BA_ "GenMsgILSupport" BO_ 2633990177 0;
BA_ "NmAsrMessage" BO_ 2633990177 1;
BA_ "GenMsgSendType" BO_ 2633990177 8;
BA_ "GenMsgILSupport" BO_ 2633990176 0;
BA_ "NmAsrMessage" BO_ 2633990176 1;
BA_ "GenMsgCycleTime" BO_ 2633990176 100;
BA_ "GenMsgILSupport" BO_ 2633990170 0;
BA_ "NmAsrMessage" BO_ 2633990170 1;
BA_ "GenMsgSendType" BO_ 2633990170 8;
BA_ "VFrameFormat" BO_ 1339 0;
BA_ "GenMsgCycleTime" BO_ 1339 250;
BA_ "GenMsgStartDelayTime" BO_ 1339 50;
BA_ "VFrameFormat" BO_ 1243 0;
BA_ "GenMsgCycleTime" BO_ 1243 100;
BA_ "GenMsgStartDelayTime" BO_ 1243 25;
BA_ "VFrameFormat" BO_ 952 0;
BA_ "GenMsgCycleTime" BO_ 952 50;
BA_ "GenMsgStartDelayTime" BO_ 952 10;
BA_ "VFrameFormat" BO_ 1511 0;
BA_ "GenMsgCycleTime" BO_ 1511 1000;
BA_ "GenMsgStartDelayTime" BO_ 1511 50;
BA_ "VFrameFormat" BO_ 1509 0;
BA_ "GenMsgCycleTime" BO_ 1509 1000;
BA_ "GenMsgStartDelayTime" BO_ 1509 50;
BA_ "VFrameFormat" BO_ 1508 0;
BA_ "GenMsgCycleTime" BO_ 1508 1000;
BA_ "GenMsgStartDelayTime" BO_ 1508 50;
BA_ "VFrameFormat" BO_ 41 0;
BA_ "GenMsgSendType" BO_ 41 8;
BA_ "GenMsgStartDelayTime" BO_ 41 50;
BA_ "GenMsgILSupport" BO_ 1506 0;
BA_ "VFrameFormat" BO_ 1506 0;
BA_ "GenMsgSendType" BO_ 1506 8;
BA_ "CanTpFcFrameId" BO_ 1505 1506;
BA_ "VFrameFormat" BO_ 1505 0;
BA_ "GenMsgSendType" BO_ 1505 8;
BA_ "VFrameFormat" BO_ 959 0;
BA_ "GenMsgCycleTime" BO_ 959 50;
BA_ "GenMsgStartDelayTime" BO_ 959 50;
BA_ "VFrameFormat" BO_ 832 0;
BA_ "GenMsgCycleTime" BO_ 832 50;
BA_ "GenMsgStartDelayTime" BO_ 832 50;
BA_ "VFrameFormat" BO_ 1232 0;
BA_ "GenMsgCycleTime" BO_ 1232 100;
BA_ "GenMsgStartDelayTime" BO_ 1232 65;
BA_ "VFrameFormat" BO_ 1507 0;
BA_ "GenMsgCycleTime" BO_ 1507 1000;
BA_ "GenMsgStartDelayTime" BO_ 1507 100;
BA_ "VFrameFormat" BO_ 1501 0;
BA_ "GenMsgCycleTime" BO_ 1501 1000;
BA_ "GenMsgStartDelayTime" BO_ 1501 65;
BA_ "VFrameFormat" BO_ 1498 0;
BA_ "GenMsgCycleTime" BO_ 1498 1000;
BA_ "GenMsgStartDelayTime" BO_ 1498 45;
BA_ "VFrameFormat" BO_ 396 0;
BA_ "GenMsgCycleTime" BO_ 396 10;
BA_ "GenMsgStartDelayTime" BO_ 396 5;
BA_ "VFrameFormat" BO_ 395 0;
BA_ "GenMsgCycleTime" BO_ 395 10;
BA_ "GenMsgStartDelayTime" BO_ 395 5;
BA_ "VFrameFormat" BO_ 394 0;
BA_ "GenMsgCycleTime" BO_ 394 10;
BA_ "VFrameFormat" BO_ 386 0;
BA_ "GenMsgCycleTime" BO_ 386 10;
BA_ "VFrameFormat" BO_ 824 0;
BA_ "GenMsgCycleTime" BO_ 824 20;
BA_ "GenMsgStartDelayTime" BO_ 824 15;
BA_ "VFrameFormat" BO_ 516 0;
BA_ "GenMsgCycleTime" BO_ 516 20;
BA_ "DiagConnection" BO_ 2671964787 62067;
BA_ "DiagUUDTResponse" BO_ 2671964787 1;
BA_ "GenMsgILSupport" BO_ 2671964787 0;
BA_ "GenMsgSendType" BO_ 2671964787 8;
BA_ "DiagConnection" BO_ 2671964711 61991;
BA_ "DiagUUDTResponse" BO_ 2671964711 1;
BA_ "GenMsgILSupport" BO_ 2671964711 0;
BA_ "GenMsgSendType" BO_ 2671964711 8;
BA_ "DiagConnection" BO_ 2671964706 61986;
BA_ "DiagUUDTResponse" BO_ 2671964706 1;
BA_ "GenMsgILSupport" BO_ 2671964706 0;
BA_ "GenMsgSendType" BO_ 2671964706 8;
BA_ "DiagConnection" BO_ 2671964705 61985;
BA_ "DiagUUDTResponse" BO_ 2671964705 1;
BA_ "GenMsgILSupport" BO_ 2671964705 0;
BA_ "GenMsgSendType" BO_ 2671964705 8;
BA_ "DiagConnection" BO_ 2671964704 61984;
BA_ "DiagUUDTResponse" BO_ 2671964704 1;
BA_ "GenMsgILSupport" BO_ 2671964704 0;
BA_ "GenMsgSendType" BO_ 2671964704 8;
BA_ "DiagConnection" BO_ 2671964698 61978;
BA_ "DiagUUDTResponse" BO_ 2671964698 1;
BA_ "GenMsgILSupport" BO_ 2671964698 0;
BA_ "GenMsgSendType" BO_ 2671964698 8;
BA_ "DiagConnection" BO_ 2671834227 62579;
BA_ "DiagResponse" BO_ 2671834227 1;
BA_ "GenMsgILSupport" BO_ 2671834227 0;
BA_ "GenMsgSendType" BO_ 2671834227 8;
BA_ "DiagConnection" BO_ 2671834151 62503;
BA_ "DiagResponse" BO_ 2671834151 1;
BA_ "GenMsgILSupport" BO_ 2671834151 0;
BA_ "GenMsgSendType" BO_ 2671834151 8;
BA_ "DiagConnection" BO_ 2671834146 62498;
BA_ "DiagResponse" BO_ 2671834146 1;
BA_ "GenMsgILSupport" BO_ 2671834146 0;
BA_ "GenMsgSendType" BO_ 2671834146 8;
BA_ "DiagConnection" BO_ 2671834145 62497;
BA_ "DiagResponse" BO_ 2671834145 1;
BA_ "GenMsgILSupport" BO_ 2671834145 0;
BA_ "GenMsgSendType" BO_ 2671834145 8;
BA_ "DiagConnection" BO_ 2671834144 62496;
BA_ "DiagResponse" BO_ 2671834144 1;
BA_ "GenMsgILSupport" BO_ 2671834144 0;
BA_ "GenMsgSendType" BO_ 2671834144 8;
BA_ "DiagConnection" BO_ 2671834138 62490;
BA_ "DiagResponse" BO_ 2671834138 1;
BA_ "GenMsgILSupport" BO_ 2671834138 0;
BA_ "GenMsgSendType" BO_ 2671834138 8;
BA_ "DiagConnection" BO_ 2671801332 62579;
BA_ "DiagRequest" BO_ 2671801332 1;
BA_ "GenMsgILSupport" BO_ 2671801332 0;
BA_ "GenMsgSendType" BO_ 2671801332 8;
BA_ "DiagConnection" BO_ 2671781876 62503;
BA_ "DiagRequest" BO_ 2671781876 1;
BA_ "GenMsgILSupport" BO_ 2671781876 0;
BA_ "GenMsgSendType" BO_ 2671781876 8;
BA_ "DiagConnection" BO_ 2671780596 62498;
BA_ "DiagRequest" BO_ 2671780596 1;
BA_ "GenMsgILSupport" BO_ 2671780596 0;
BA_ "GenMsgSendType" BO_ 2671780596 8;
BA_ "DiagConnection" BO_ 2671780340 62497;
BA_ "DiagRequest" BO_ 2671780340 1;
BA_ "GenMsgILSupport" BO_ 2671780340 0;
BA_ "GenMsgSendType" BO_ 2671780340 8;
BA_ "DiagConnection" BO_ 2671780084 62496;
BA_ "DiagRequest" BO_ 2671780084 1;
BA_ "GenMsgILSupport" BO_ 2671780084 0;
BA_ "GenMsgSendType" BO_ 2671780084 8;
BA_ "DiagConnection" BO_ 2671778548 62490;
BA_ "DiagRequest" BO_ 2671778548 1;
BA_ "GenMsgILSupport" BO_ 2671778548 0;
BA_ "GenMsgSendType" BO_ 2671778548 8;
BA_ "VFrameFormat" BO_ 1503 0;
BA_ "GenMsgCycleTime" BO_ 1503 1000;
BA_ "GenMsgDelayTime" BO_ 1503 85;
BA_ "GenMsgStartDelayTime" BO_ 1503 5;
BA_ "VFrameFormat" BO_ 1500 0;
BA_ "GenMsgCycleTime" BO_ 1500 1000;
BA_ "GenMsgDelayTime" BO_ 1500 90;
BA_ "GenMsgStartDelayTime" BO_ 1500 5;
BA_ "VFrameFormat" BO_ 1497 0;
BA_ "GenMsgSendType" BO_ 1497 8;
BA_ "GenMsgDelayTime" BO_ 1497 80;
BA_ "VFrameFormat" BO_ 1496 0;
BA_ "GenMsgSendType" BO_ 1496 8;
BA_ "GenMsgDelayTime" BO_ 1496 80;
BA_ "VFrameFormat" BO_ 1499 0;
BA_ "GenMsgCycleTime" BO_ 1499 1000;
BA_ "GenMsgDelayTime" BO_ 1499 90;
BA_ "GenMsgStartDelayTime" BO_ 1499 20;
BA_ "VFrameFormat" BO_ 1490 0;
BA_ "GenMsgCycleTime" BO_ 1490 1000;
BA_ "GenMsgDelayTime" BO_ 1490 95;
BA_ "GenMsgStartDelayTime" BO_ 1490 20;
BA_ "VFrameFormat" BO_ 1952 0;
BA_ "GenMsgSendType" BO_ 1952 8;
BA_ "GenMsgDelayTime" BO_ 1952 50;
BA_ "GenMsgStartDelayTime" BO_ 1952 50;
BA_ "VFrameFormat" BO_ 1951 0;
BA_ "GenMsgSendType" BO_ 1951 8;
BA_ "GenMsgDelayTime" BO_ 1951 50;
BA_ "GenMsgStartDelayTime" BO_ 1951 50;
BA_ "VFrameFormat" BO_ 1947 0;
BA_ "GenMsgSendType" BO_ 1947 8;
BA_ "GenMsgDelayTime" BO_ 1947 50;
BA_ "GenMsgStartDelayTime" BO_ 1947 50;
BA_ "VFrameFormat" BO_ 1946 0;
BA_ "GenMsgSendType" BO_ 1946 8;
BA_ "GenMsgDelayTime" BO_ 1946 50;
BA_ "GenMsgStartDelayTime" BO_ 1946 50;
BA_ "VFrameFormat" BO_ 1942 0;
BA_ "GenMsgSendType" BO_ 1942 8;
BA_ "GenMsgDelayTime" BO_ 1942 50;
BA_ "GenMsgStartDelayTime" BO_ 1942 50;
BA_ "VFrameFormat" BO_ 1941 0;
BA_ "GenMsgSendType" BO_ 1941 8;
BA_ "GenMsgDelayTime" BO_ 1941 50;
BA_ "GenMsgStartDelayTime" BO_ 1941 50;
BA_ "VFrameFormat" BO_ 1935 0;
BA_ "GenMsgSendType" BO_ 1935 8;
BA_ "GenMsgDelayTime" BO_ 1935 50;
BA_ "GenMsgStartDelayTime" BO_ 1935 50;
BA_ "VFrameFormat" BO_ 1933 0;
BA_ "GenMsgSendType" BO_ 1933 8;
BA_ "GenMsgDelayTime" BO_ 1933 50;
BA_ "GenMsgStartDelayTime" BO_ 1933 50;
BA_ "VFrameFormat" BO_ 1927 0;
BA_ "GenMsgSendType" BO_ 1927 8;
BA_ "GenMsgDelayTime" BO_ 1927 50;
BA_ "GenMsgStartDelayTime" BO_ 1927 50;
BA_ "VFrameFormat" BO_ 1925 0;
BA_ "GenMsgSendType" BO_ 1925 8;
BA_ "GenMsgDelayTime" BO_ 1925 50;
BA_ "GenMsgStartDelayTime" BO_ 1925 50;
BA_ "VFrameFormat" BO_ 1919 0;
BA_ "GenMsgSendType" BO_ 1919 8;
BA_ "GenMsgDelayTime" BO_ 1919 50;
BA_ "GenMsgStartDelayTime" BO_ 1919 50;
BA_ "VFrameFormat" BO_ 1917 0;
BA_ "GenMsgSendType" BO_ 1917 8;
BA_ "GenMsgDelayTime" BO_ 1917 50;
BA_ "GenMsgStartDelayTime" BO_ 1917 50;
BA_ "VFrameFormat" BO_ 1911 0;
BA_ "GenMsgSendType" BO_ 1911 8;
BA_ "GenMsgDelayTime" BO_ 1911 10;
BA_ "GenMsgStartDelayTime" BO_ 1911 50;
BA_ "VFrameFormat" BO_ 1909 0;
BA_ "GenMsgSendType" BO_ 1909 8;
BA_ "GenMsgDelayTime" BO_ 1909 10;
BA_ "GenMsgStartDelayTime" BO_ 1909 50;
BA_ "VFrameFormat" BO_ 1903 0;
BA_ "GenMsgSendType" BO_ 1903 8;
BA_ "GenMsgDelayTime" BO_ 1903 10;
BA_ "GenMsgStartDelayTime" BO_ 1903 50;
BA_ "VFrameFormat" BO_ 1901 0;
BA_ "GenMsgSendType" BO_ 1901 8;
BA_ "GenMsgDelayTime" BO_ 1901 10;
BA_ "GenMsgStartDelayTime" BO_ 1901 50;
BA_ "VFrameFormat" BO_ 1981 0;
BA_ "GenMsgSendType" BO_ 1981 8;
BA_ "GenMsgDelayTime" BO_ 1981 10;
BA_ "GenMsgStartDelayTime" BO_ 1981 50;
BA_ "VFrameFormat" BO_ 1895 0;
BA_ "VFrameFormat" BO_ 1893 0;
BA_ "VFrameFormat" BO_ 1980 0;
BA_ "GenMsgSendType" BO_ 1980 8;
BA_ "GenMsgDelayTime" BO_ 1980 15;
BA_ "VFrameFormat" BO_ 1979 0;
BA_ "GenMsgSendType" BO_ 1979 8;
BA_ "GenMsgDelayTime" BO_ 1979 15;
BA_ "VFrameFormat" BO_ 1978 0;
BA_ "GenMsgSendType" BO_ 1978 8;
BA_ "GenMsgDelayTime" BO_ 1978 15;
BA_ "VFrameFormat" BO_ 1977 0;
BA_ "GenMsgSendType" BO_ 1977 8;
BA_ "GenMsgDelayTime" BO_ 1977 15;
BA_ "VFrameFormat" BO_ 1976 0;
BA_ "GenMsgSendType" BO_ 1976 8;
BA_ "GenMsgDelayTime" BO_ 1976 15;
BA_ "VFrameFormat" BO_ 1969 0;
BA_ "GenMsgSendType" BO_ 1969 8;
BA_ "GenMsgDelayTime" BO_ 1969 15;
BA_ "GenMsgStartDelayTime" BO_ 1969 50;
BA_ "VFrameFormat" BO_ 1968 0;
BA_ "GenMsgSendType" BO_ 1968 8;
BA_ "GenMsgDelayTime" BO_ 1968 15;
BA_ "GenMsgStartDelayTime" BO_ 1968 50;
BA_ "VFrameFormat" BO_ 1975 0;
BA_ "GenMsgSendType" BO_ 1975 8;
BA_ "GenMsgDelayTime" BO_ 1975 15;
BA_ "VFrameFormat" BO_ 1967 0;
BA_ "GenMsgSendType" BO_ 1967 8;
BA_ "GenMsgDelayTime" BO_ 1967 15;
BA_ "VFrameFormat" BO_ 1974 0;
BA_ "GenMsgSendType" BO_ 1974 8;
BA_ "GenMsgDelayTime" BO_ 1974 15;
BA_ "VFrameFormat" BO_ 1965 0;
BA_ "GenMsgSendType" BO_ 1965 8;
BA_ "GenMsgDelayTime" BO_ 1965 15;
BA_ "VFrameFormat" BO_ 1973 0;
BA_ "GenMsgSendType" BO_ 1973 8;
BA_ "GenMsgDelayTime" BO_ 1973 15;
BA_ "VFrameFormat" BO_ 1963 0;
BA_ "GenMsgSendType" BO_ 1963 8;
BA_ "GenMsgDelayTime" BO_ 1963 10;
BA_ "GenMsgStartDelayTime" BO_ 1963 50;
BA_ "VFrameFormat" BO_ 1961 0;
BA_ "GenMsgSendType" BO_ 1961 8;
BA_ "GenMsgDelayTime" BO_ 1961 50;
BA_ "GenMsgStartDelayTime" BO_ 1961 50;
BA_ "VFrameFormat" BO_ 1960 0;
BA_ "GenMsgSendType" BO_ 1960 8;
BA_ "GenMsgDelayTime" BO_ 1960 50;
BA_ "GenMsgStartDelayTime" BO_ 1960 50;
BA_ "VFrameFormat" BO_ 1957 0;
BA_ "GenMsgSendType" BO_ 1957 8;
BA_ "GenMsgDelayTime" BO_ 1957 50;
BA_ "GenMsgStartDelayTime" BO_ 1957 50;
BA_ "VFrameFormat" BO_ 1956 0;
BA_ "GenMsgSendType" BO_ 1956 8;
BA_ "GenMsgDelayTime" BO_ 1956 50;
BA_ "GenMsgStartDelayTime" BO_ 1956 50;
BA_ "VFrameFormat" BO_ 1253 0;
BA_ "GenMsgCycleTime" BO_ 1253 100;
BA_ "VFrameFormat" BO_ 1372 0;
BA_ "GenMsgCycleTime" BO_ 1372 500;
BA_ "GenMsgStartDelayTime" BO_ 1372 80;
BA_ "VFrameFormat" BO_ 1371 0;
BA_ "GenMsgCycleTime" BO_ 1371 500;
BA_ "GenMsgStartDelayTime" BO_ 1371 65;
BA_ "VFrameFormat" BO_ 1362 0;
BA_ "GenMsgCycleTime" BO_ 1362 500;
BA_ "GenMsgStartDelayTime" BO_ 1362 40;
BA_ "VFrameFormat" BO_ 1444 0;
BA_ "GenMsgCycleTime" BO_ 1444 1000;
BA_ "GenMsgStartDelayTime" BO_ 1444 50;
BA_ "VFrameFormat" BO_ 1471 0;
BA_ "GenMsgCycleTime" BO_ 1471 1000;
BA_ "GenMsgStartDelayTime" BO_ 1471 270;
BA_ "VFrameFormat" BO_ 1469 0;
BA_ "GenMsgCycleTime" BO_ 1469 1000;
BA_ "GenMsgStartDelayTime" BO_ 1469 255;
BA_ "VFrameFormat" BO_ 1467 0;
BA_ "GenMsgCycleTime" BO_ 1467 1000;
BA_ "GenMsgStartDelayTime" BO_ 1467 240;
BA_ "VFrameFormat" BO_ 1465 0;
BA_ "GenMsgCycleTime" BO_ 1465 1000;
BA_ "GenMsgStartDelayTime" BO_ 1465 225;
BA_ "VFrameFormat" BO_ 1463 0;
BA_ "GenMsgCycleTime" BO_ 1463 1000;
BA_ "GenMsgStartDelayTime" BO_ 1463 210;
BA_ "GenSigCycleTime" SG_ 517 FrontProhibitControlRequest 100;
BA_ "GenSigCycleTimeActive" SG_ 517 FrontProhibitControlRequest 100;
BA_ "GenSigStartValue" SG_ 517 FrontProhibitControlRequest 3;
BA_ "GenSigMaxLatency" SG_ 517 FrontProhibitControlRequest 23;
BA_ "Platform_VMCU1_Sig" SG_ 517 FrontProhibitControlRequest 1;
BA_ "Platform_Vivis2_Sig" SG_ 517 FrontProhibitControlRequest 1;
BA_ "GenSigCycleTime" SG_ 517 RampLevelStorageAck_ISig_4 100;
BA_ "GenSigCycleTimeActive" SG_ 517 RampLevelStorageAck_ISig_4 100;
BA_ "GenSigStartValue" SG_ 517 RampLevelStorageAck_ISig_4 3;
BA_ "GenSigMaxLatency" SG_ 517 RampLevelStorageAck_ISig_4 23;
BA_ "Platform_VMCU1_Sig" SG_ 517 RampLevelStorageAck_ISig_4 1;
BA_ "Platform_Vivis2_Sig" SG_ 517 RampLevelStorageAck_ISig_4 1;
BA_ "GenSigSendType" SG_ 517 BrakePressureSensorDemand_UB_ISi 7;
BA_ "Platform_VMCU1_Sig" SG_ 517 BrakePressureSensorDemand_UB_ISi 1;
BA_ "Platform_Vivis2_Sig" SG_ 517 BrakePressureSensorDemand_UB_ISi 1;
BA_ "SystemSignalLongSymbol" SG_ 517 BrakePressureSensorDemand_UB_ISi "BrakePressureSensorDemand_UB_ISig_4";
BA_ "GenSigCycleTime" SG_ 517 FrontLimpHomeCmd 100;
BA_ "GenSigCycleTimeActive" SG_ 517 FrontLimpHomeCmd 100;
BA_ "GenSigStartValue" SG_ 517 FrontLimpHomeCmd 7;
BA_ "GenSigMaxLatency" SG_ 517 FrontLimpHomeCmd 23;
BA_ "Platform_VMCU1_Sig" SG_ 517 FrontLimpHomeCmd 1;
BA_ "Platform_Vivis2_Sig" SG_ 517 FrontLimpHomeCmd 1;
BA_ "GenSigCycleTime" SG_ 517 LiftingControlModeRearAxle 100;
BA_ "GenSigCycleTimeActive" SG_ 517 LiftingControlModeRearAxle 100;
BA_ "GenSigStartValue" SG_ 517 LiftingControlModeRearAxle 3;
BA_ "GenSigMaxLatency" SG_ 517 LiftingControlModeRearAxle 23;
BA_ "Platform_VMCU1_Sig" SG_ 517 LiftingControlModeRearAxle 1;
BA_ "Platform_Vivis2_Sig" SG_ 517 LiftingControlModeRearAxle 1;
BA_ "GenSigCycleTime" SG_ 517 LoadDistributionChangeACK_ISig_4 100;
BA_ "GenSigCycleTimeActive" SG_ 517 LoadDistributionChangeACK_ISig_4 100;
BA_ "GenSigStartValue" SG_ 517 LoadDistributionChangeACK_ISig_4 7;
BA_ "GenSigMaxLatency" SG_ 517 LoadDistributionChangeACK_ISig_4 23;
BA_ "Platform_VMCU1_Sig" SG_ 517 LoadDistributionChangeACK_ISig_4 1;
BA_ "Platform_Vivis2_Sig" SG_ 517 LoadDistributionChangeACK_ISig_4 1;
BA_ "GenSigCycleTime" SG_ 517 ECSStandbyAllowed_ISig_4 100;
BA_ "GenSigCycleTimeActive" SG_ 517 ECSStandbyAllowed_ISig_4 100;
BA_ "GenSigStartValue" SG_ 517 ECSStandbyAllowed_ISig_4 3;
BA_ "Platform_VMCU1_Sig" SG_ 517 ECSStandbyAllowed_ISig_4 1;
BA_ "Platform_Vivis2_Sig" SG_ 517 ECSStandbyAllowed_ISig_4 1;
BA_ "GenSigCycleTime" SG_ 517 LiftAxle2LiftFuncSelected_ISig_4 100;
BA_ "GenSigCycleTimeActive" SG_ 517 LiftAxle2LiftFuncSelected_ISig_4 100;
BA_ "GenSigStartValue" SG_ 517 LiftAxle2LiftFuncSelected_ISig_4 7;
BA_ "Platform_Vivis2_Sig" SG_ 517 LiftAxle2LiftFuncSelected_ISig_4 1;
BA_ "GenSigCycleTime" SG_ 517 LiftAxle2UpRequestACK_ISig_4 100;
BA_ "GenSigCycleTimeActive" SG_ 517 LiftAxle2UpRequestACK_ISig_4 100;
BA_ "GenSigStartValue" SG_ 517 LiftAxle2UpRequestACK_ISig_4 7;
BA_ "GenSigMaxLatency" SG_ 517 LiftAxle2UpRequestACK_ISig_4 23;
BA_ "Platform_VMCU1_Sig" SG_ 517 LiftAxle2UpRequestACK_ISig_4 1;
BA_ "Platform_Vivis2_Sig" SG_ 517 LiftAxle2UpRequestACK_ISig_4 1;
BA_ "GenSigCycleTime" SG_ 517 ProhibitControlStatus_ISig_4 100;
BA_ "GenSigCycleTimeActive" SG_ 517 ProhibitControlStatus_ISig_4 100;
BA_ "GenSigStartValue" SG_ 517 ProhibitControlStatus_ISig_4 3;
BA_ "GenSigMaxLatency" SG_ 517 ProhibitControlStatus_ISig_4 23;
BA_ "Platform_VMCU1_Sig" SG_ 517 ProhibitControlStatus_ISig_4 1;
BA_ "Platform_Vivis2_Sig" SG_ 517 ProhibitControlStatus_ISig_4 1;
BA_ "GenSigCycleTime" SG_ 517 RampLevelStatus_ISig_4 100;
BA_ "GenSigCycleTimeActive" SG_ 517 RampLevelStatus_ISig_4 100;
BA_ "GenSigStartValue" SG_ 517 RampLevelStatus_ISig_4 15;
BA_ "GenSigMaxLatency" SG_ 517 RampLevelStatus_ISig_4 23;
BA_ "Platform_VMCU1_Sig" SG_ 517 RampLevelStatus_ISig_4 1;
BA_ "Platform_Vivis2_Sig" SG_ 517 RampLevelStatus_ISig_4 1;
BA_ "GenSigCycleTime" SG_ 517 StopLevelChangeAck_ISig_4 100;
BA_ "GenSigCycleTimeActive" SG_ 517 StopLevelChangeAck_ISig_4 100;
BA_ "GenSigStartValue" SG_ 517 StopLevelChangeAck_ISig_4 3;
BA_ "GenSigMaxLatency" SG_ 517 StopLevelChangeAck_ISig_4 23;
BA_ "Platform_VMCU1_Sig" SG_ 517 StopLevelChangeAck_ISig_4 1;
BA_ "Platform_Vivis2_Sig" SG_ 517 StopLevelChangeAck_ISig_4 1;
BA_ "GenSigCycleTime" SG_ 517 LiftAxle2LowerACK_ISig_4 100;
BA_ "GenSigCycleTimeActive" SG_ 517 LiftAxle2LowerACK_ISig_4 100;
BA_ "GenSigStartValue" SG_ 517 LiftAxle2LowerACK_ISig_4 7;
BA_ "Platform_Vivis2_Sig" SG_ 517 LiftAxle2LowerACK_ISig_4 1;
BA_ "GenSigCycleTime" SG_ 517 RideHeightStorageAck_ISig_4 100;
BA_ "GenSigCycleTimeActive" SG_ 517 RideHeightStorageAck_ISig_4 100;
BA_ "GenSigStartValue" SG_ 517 RideHeightStorageAck_ISig_4 3;
BA_ "GenSigMaxLatency" SG_ 517 RideHeightStorageAck_ISig_4 23;
BA_ "Platform_VMCU1_Sig" SG_ 517 RideHeightStorageAck_ISig_4 1;
BA_ "Platform_Vivis2_Sig" SG_ 517 RideHeightStorageAck_ISig_4 1;
BA_ "GenSigCycleTime" SG_ 517 FrontParkBrakeOverrideCommand 100;
BA_ "GenSigCycleTimeActive" SG_ 517 FrontParkBrakeOverrideCommand 100;
BA_ "GenSigStartValue" SG_ 517 FrontParkBrakeOverrideCommand 3;
BA_ "Platform_VMCU1_Sig" SG_ 517 FrontParkBrakeOverrideCommand 1;
BA_ "Platform_Vivis2_Sig" SG_ 517 FrontParkBrakeOverrideCommand 1;
BA_ "GenSigCycleTime" SG_ 517 RideHeightOutsideTargetRange_ISi 100;
BA_ "GenSigCycleTimeActive" SG_ 517 RideHeightOutsideTargetRange_ISi 100;
BA_ "GenSigStartValue" SG_ 517 RideHeightOutsideTargetRange_ISi 7;
BA_ "GenSigMaxLatency" SG_ 517 RideHeightOutsideTargetRange_ISi 23;
BA_ "Platform_VMCU1_Sig" SG_ 517 RideHeightOutsideTargetRange_ISi 1;
BA_ "Platform_Vivis2_Sig" SG_ 517 RideHeightOutsideTargetRange_ISi 1;
BA_ "SystemSignalLongSymbol" SG_ 517 RideHeightOutsideTargetRange_ISi "RideHeightOutsideTargetRange_ISig_4";
BA_ "GenSigCycleTime" SG_ 517 DisableMechFaultDctnFr_rqst 100;
BA_ "GenSigCycleTimeActive" SG_ 517 DisableMechFaultDctnFr_rqst 100;
BA_ "GenSigStartValue" SG_ 517 DisableMechFaultDctnFr_rqst 3;
BA_ "GenSigMaxLatency" SG_ 517 DisableMechFaultDctnFr_rqst 23;
BA_ "Platform_VMCU1_Sig" SG_ 517 DisableMechFaultDctnFr_rqst 1;
BA_ "Platform_Vivis2_Sig" SG_ 517 DisableMechFaultDctnFr_rqst 1;
BA_ "GenSigSendType" SG_ 517 RearAxleInBumperRange_UB_ISig_4 7;
BA_ "Platform_VMCU1_Sig" SG_ 517 RearAxleInBumperRange_UB_ISig_4 1;
BA_ "Platform_Vivis2_Sig" SG_ 517 RearAxleInBumperRange_UB_ISig_4 1;
BA_ "GenSigCycleTime" SG_ 517 BrakePressureSensorDemand_ISig_4 100;
BA_ "GenSigCycleTimeActive" SG_ 517 BrakePressureSensorDemand_ISig_4 100;
BA_ "GenSigStartValue" SG_ 517 BrakePressureSensorDemand_ISig_4 255;
BA_ "GenSigMaxLatency" SG_ 517 BrakePressureSensorDemand_ISig_4 23;
BA_ "NeedsUpdateBit" SG_ 517 BrakePressureSensorDemand_ISig_4 1;
BA_ "Platform_VMCU1_Sig" SG_ 517 BrakePressureSensorDemand_ISig_4 1;
BA_ "Platform_Vivis2_Sig" SG_ 517 BrakePressureSensorDemand_ISig_4 1;
BA_ "GenSigCycleTime" SG_ 517 FogLamp_Rear_Status 100;
BA_ "GenSigCycleTimeActive" SG_ 517 FogLamp_Rear_Status 100;
BA_ "GenSigStartValue" SG_ 517 FogLamp_Rear_Status 3;
BA_ "GenSigMaxLatency" SG_ 517 FogLamp_Rear_Status 23;
BA_ "Platform_VMCU1_Sig" SG_ 517 FogLamp_Rear_Status 1;
BA_ "Platform_Vivis2_Sig" SG_ 517 FogLamp_Rear_Status 1;
BA_ "GenSigCycleTime" SG_ 517 LiftingControlModeFrontAxle 100;
BA_ "GenSigCycleTimeActive" SG_ 517 LiftingControlModeFrontAxle 100;
BA_ "GenSigStartValue" SG_ 517 LiftingControlModeFrontAxle 3;
BA_ "GenSigMaxLatency" SG_ 517 LiftingControlModeFrontAxle 27;
BA_ "Platform_VMCU1_Sig" SG_ 517 LiftingControlModeFrontAxle 1;
BA_ "Platform_Vivis2_Sig" SG_ 517 LiftingControlModeFrontAxle 1;
BA_ "GenSigCycleTime" SG_ 517 LiftAxle1UpRequestACK_ISig_4 100;
BA_ "GenSigCycleTimeActive" SG_ 517 LiftAxle1UpRequestACK_ISig_4 100;
BA_ "GenSigStartValue" SG_ 517 LiftAxle1UpRequestACK_ISig_4 7;
BA_ "GenSigMaxLatency" SG_ 517 LiftAxle1UpRequestACK_ISig_4 23;
BA_ "Platform_VMCU1_Sig" SG_ 517 LiftAxle1UpRequestACK_ISig_4 1;
BA_ "Platform_Vivis2_Sig" SG_ 517 LiftAxle1UpRequestACK_ISig_4 1;
BA_ "GenSigCycleTime" SG_ 517 LiftAxle1LiftFuncSelected_ISig_4 100;
BA_ "GenSigCycleTimeActive" SG_ 517 LiftAxle1LiftFuncSelected_ISig_4 100;
BA_ "GenSigStartValue" SG_ 517 LiftAxle1LiftFuncSelected_ISig_4 7;
BA_ "Platform_Vivis2_Sig" SG_ 517 LiftAxle1LiftFuncSelected_ISig_4 1;
BA_ "GenSigCycleTime" SG_ 517 RearAxleInBumperRange_ISig_4 100;
BA_ "GenSigCycleTimeActive" SG_ 517 RearAxleInBumperRange_ISig_4 100;
BA_ "GenSigStartValue" SG_ 517 RearAxleInBumperRange_ISig_4 3;
BA_ "GenSigMaxLatency" SG_ 517 RearAxleInBumperRange_ISig_4 23;
BA_ "NeedsUpdateBit" SG_ 517 RearAxleInBumperRange_ISig_4 1;
BA_ "Platform_VMCU1_Sig" SG_ 517 RearAxleInBumperRange_ISig_4 1;
BA_ "Platform_Vivis2_Sig" SG_ 517 RearAxleInBumperRange_ISig_4 1;
BA_ "GenSigSendType" SG_ 2671833715 PhysDiagRespSig_F2_73_ISig_4 7;
BA_ "GenSigSendType" SG_ 2671833639 PhysDiagRespSig_F2_27_ISig_4 7;
BA_ "GenSigSendType" SG_ 2671833634 PhysDiagRespSig_F2_22_ISig_4 7;
BA_ "GenSigSendType" SG_ 2671833633 PhysDiagRespSig_F2_21_ISig_4 7;
BA_ "GenSigSendType" SG_ 2671833632 PhysDiagRespSig_F2_20_ISig_4 7;
BA_ "GenSigSendType" SG_ 2671833626 PhysDiagRespSig_F2_1A_ISig_4 7;
BA_ "GenSigSendType" SG_ 2671801330 PhysDiagReqSig_73_F2_ISig_4 7;
BA_ "GenSigSendType" SG_ 2671781874 PhysDiagReqSig_27_F2_ISig_4 7;
BA_ "GenSigSendType" SG_ 2671780594 PhysDiagReqSig_22_F2_ISig_4 7;
BA_ "GenSigSendType" SG_ 2671780338 PhysDiagReqSig_21_F2_ISig_4 7;
BA_ "GenSigSendType" SG_ 2671780082 PhysDiagReqSig_20_F2_ISig_4 7;
BA_ "GenSigSendType" SG_ 2671778546 PhysDiagReqSig_1A_F2_ISig_4 7;
BA_ "GenSigCycleTime" SG_ 1339 HeadlampFan_stat_ISig_4 100;
BA_ "GenSigCycleTimeActive" SG_ 1339 HeadlampFan_stat_ISig_4 100;
BA_ "GenSigStartValue" SG_ 1339 HeadlampFan_stat_ISig_4 7;
BA_ "Platform_Vivis2_Sig" SG_ 1339 HeadlampFan_stat_ISig_4 1;
BA_ "GenSigCycleTime" SG_ 1339 FrontConspicLamp_stat_HiRight_IS 100;
BA_ "GenSigCycleTimeActive" SG_ 1339 FrontConspicLamp_stat_HiRight_IS 100;
BA_ "GenSigStartValue" SG_ 1339 FrontConspicLamp_stat_HiRight_IS 7;
BA_ "GenSigMaxLatency" SG_ 1339 FrontConspicLamp_stat_HiRight_IS 250;
BA_ "Platform_Vivis2_Sig" SG_ 1339 FrontConspicLamp_stat_HiRight_IS 1;
BA_ "SystemSignalLongSymbol" SG_ 1339 FrontConspicLamp_stat_HiRight_IS "FrontConspicLamp_stat_HiRight_ISig_4";
BA_ "GenSigCycleTime" SG_ 1339 AmbientAirTemperature2 100;
BA_ "GenSigCycleTimeActive" SG_ 1339 AmbientAirTemperature2 100;
BA_ "GenSigStartValue" SG_ 1339 AmbientAirTemperature2 65535;
BA_ "Platform_Vivis2_Sig" SG_ 1339 AmbientAirTemperature2 1;
BA_ "GenSigCycleTime" SG_ 1339 FrontConspicLamp_stat_LoRight_IS 100;
BA_ "GenSigCycleTimeActive" SG_ 1339 FrontConspicLamp_stat_LoRight_IS 100;
BA_ "GenSigStartValue" SG_ 1339 FrontConspicLamp_stat_LoRight_IS 7;
BA_ "GenSigMaxLatency" SG_ 1339 FrontConspicLamp_stat_LoRight_IS 250;
BA_ "Platform_Vivis2_Sig" SG_ 1339 FrontConspicLamp_stat_LoRight_IS 1;
BA_ "SystemSignalLongSymbol" SG_ 1339 FrontConspicLamp_stat_LoRight_IS "FrontConspicLamp_stat_LoRight_ISig_4";
BA_ "GenSigCycleTime" SG_ 1339 FrontConspicLamp_stat_HiLeft_ISi 100;
BA_ "GenSigCycleTimeActive" SG_ 1339 FrontConspicLamp_stat_HiLeft_ISi 100;
BA_ "GenSigStartValue" SG_ 1339 FrontConspicLamp_stat_HiLeft_ISi 7;
BA_ "GenSigMaxLatency" SG_ 1339 FrontConspicLamp_stat_HiLeft_ISi 250;
BA_ "Platform_Vivis2_Sig" SG_ 1339 FrontConspicLamp_stat_HiLeft_ISi 1;
BA_ "SystemSignalLongSymbol" SG_ 1339 FrontConspicLamp_stat_HiLeft_ISi "FrontConspicLamp_stat_HiLeft_ISig_4";
BA_ "GenSigCycleTime" SG_ 1339 FrontConspicLamp_stat_LoLeft_ISi 100;
BA_ "GenSigCycleTimeActive" SG_ 1339 FrontConspicLamp_stat_LoLeft_ISi 100;
BA_ "GenSigStartValue" SG_ 1339 FrontConspicLamp_stat_LoLeft_ISi 7;
BA_ "GenSigMaxLatency" SG_ 1339 FrontConspicLamp_stat_LoLeft_ISi 250;
BA_ "Platform_Vivis2_Sig" SG_ 1339 FrontConspicLamp_stat_LoLeft_ISi 1;
BA_ "SystemSignalLongSymbol" SG_ 1339 FrontConspicLamp_stat_LoLeft_ISi "FrontConspicLamp_stat_LoLeft_ISig_4";
BA_ "GenSigCycleTime" SG_ 1243 MainBeamLEDStatusRight_ISig_4 100;
BA_ "GenSigCycleTimeActive" SG_ 1243 MainBeamLEDStatusRight_ISig_4 100;
BA_ "GenSigStartValue" SG_ 1243 MainBeamLEDStatusRight_ISig_4 7;
BA_ "Platform_VMCU1_Sig" SG_ 1243 MainBeamLEDStatusRight_ISig_4 1;
BA_ "Platform_Vivis2_Sig" SG_ 1243 MainBeamLEDStatusRight_ISig_4 1;
BA_ "GenSigCycleTime" SG_ 1243 DeicingBulb_Stat_ISig_4 100;
BA_ "GenSigCycleTimeActive" SG_ 1243 DeicingBulb_Stat_ISig_4 100;
BA_ "GenSigStartValue" SG_ 1243 DeicingBulb_Stat_ISig_4 7;
BA_ "Platform_Vivis2_Sig" SG_ 1243 DeicingBulb_Stat_ISig_4 1;
BA_ "GenSigCycleTime" SG_ 1243 DeicingFunction_Stat_ISig_4 100;
BA_ "GenSigCycleTimeActive" SG_ 1243 DeicingFunction_Stat_ISig_4 100;
BA_ "GenSigStartValue" SG_ 1243 DeicingFunction_Stat_ISig_4 7;
BA_ "Platform_Vivis2_Sig" SG_ 1243 DeicingFunction_Stat_ISig_4 1;
BA_ "GenSigCycleTime" SG_ 1243 MainBeamLEDStatusLeft_ISig_4 100;
BA_ "GenSigCycleTimeActive" SG_ 1243 MainBeamLEDStatusLeft_ISig_4 100;
BA_ "GenSigStartValue" SG_ 1243 MainBeamLEDStatusLeft_ISig_4 7;
BA_ "Platform_VMCU1_Sig" SG_ 1243 MainBeamLEDStatusLeft_ISig_4 1;
BA_ "Platform_Vivis2_Sig" SG_ 1243 MainBeamLEDStatusLeft_ISig_4 1;
BA_ "GenSigCycleTime" SG_ 952 DRLLamp_stat_ISig_4 100;
BA_ "GenSigCycleTimeActive" SG_ 952 DRLLamp_stat_ISig_4 100;
BA_ "GenSigInactiveValue" SG_ 952 DRLLamp_stat_ISig_4 7;
BA_ "GenSigStartValue" SG_ 952 DRLLamp_stat_ISig_4 7;
BA_ "GenSigMaxLatency" SG_ 952 DRLLamp_stat_ISig_4 59;
BA_ "Platform_VMCU1_Sig" SG_ 952 DRLLamp_stat_ISig_4 1;
BA_ "Platform_Vivis2_Sig" SG_ 952 DRLLamp_stat_ISig_4 1;
BA_ "GenSigCycleTime" SG_ 952 FogLamp_Front_Status 100;
BA_ "GenSigCycleTimeActive" SG_ 952 FogLamp_Front_Status 100;
BA_ "GenSigStartValue" SG_ 952 FogLamp_Front_Status 3;
BA_ "GenSigMaxLatency" SG_ 952 FogLamp_Front_Status 59;
BA_ "Platform_VMCU1_Sig" SG_ 952 FogLamp_Front_Status 1;
BA_ "Platform_Vivis2_Sig" SG_ 952 FogLamp_Front_Status 1;
BA_ "GenSigCycleTime" SG_ 952 DirIndSideLamp1_stat 100;
BA_ "GenSigCycleTimeActive" SG_ 952 DirIndSideLamp1_stat 100;
BA_ "GenSigStartValue" SG_ 952 DirIndSideLamp1_stat 7;
BA_ "Platform_VMCU1_Sig" SG_ 952 DirIndSideLamp1_stat 1;
BA_ "Platform_Vivis2_Sig" SG_ 952 DirIndSideLamp1_stat 1;
BA_ "GenSigCycleTime" SG_ 952 PositionLightLamp_stat_ISig_4 100;
BA_ "GenSigCycleTimeActive" SG_ 952 PositionLightLamp_stat_ISig_4 100;
BA_ "GenSigInactiveValue" SG_ 952 PositionLightLamp_stat_ISig_4 7;
BA_ "GenSigStartValue" SG_ 952 PositionLightLamp_stat_ISig_4 7;
BA_ "GenSigMaxLatency" SG_ 952 PositionLightLamp_stat_ISig_4 59;
BA_ "Platform_VMCU1_Sig" SG_ 952 PositionLightLamp_stat_ISig_4 1;
BA_ "Platform_Vivis2_Sig" SG_ 952 PositionLightLamp_stat_ISig_4 1;
BA_ "GenSigCycleTime" SG_ 952 DippedBeamLamp_stat_ISig_4 100;
BA_ "GenSigCycleTimeActive" SG_ 952 DippedBeamLamp_stat_ISig_4 100;
BA_ "GenSigInactiveValue" SG_ 952 DippedBeamLamp_stat_ISig_4 7;
BA_ "GenSigStartValue" SG_ 952 DippedBeamLamp_stat_ISig_4 7;
BA_ "GenSigMaxLatency" SG_ 952 DippedBeamLamp_stat_ISig_4 59;
BA_ "Platform_VMCU1_Sig" SG_ 952 DippedBeamLamp_stat_ISig_4 1;
BA_ "Platform_Vivis2_Sig" SG_ 952 DippedBeamLamp_stat_ISig_4 1;
BA_ "GenSigCycleTime" SG_ 952 MainBeamLamp_stat_ISig_4 100;
BA_ "GenSigCycleTimeActive" SG_ 952 MainBeamLamp_stat_ISig_4 100;
BA_ "GenSigStartValue" SG_ 952 MainBeamLamp_stat_ISig_4 7;
BA_ "Platform_Vivis2_Sig" SG_ 952 MainBeamLamp_stat_ISig_4 1;
BA_ "GenSigCycleTime" SG_ 952 StaticCornerLightLamp_stat_ISig_ 100;
BA_ "GenSigCycleTimeActive" SG_ 952 StaticCornerLightLamp_stat_ISig_ 100;
BA_ "GenSigInactiveValue" SG_ 952 StaticCornerLightLamp_stat_ISig_ 7;
BA_ "GenSigStartValue" SG_ 952 StaticCornerLightLamp_stat_ISig_ 7;
BA_ "GenSigMaxLatency" SG_ 952 StaticCornerLightLamp_stat_ISig_ 59;
BA_ "Platform_VMCU1_Sig" SG_ 952 StaticCornerLightLamp_stat_ISig_ 1;
BA_ "Platform_Vivis2_Sig" SG_ 952 StaticCornerLightLamp_stat_ISig_ 1;
BA_ "SystemSignalLongSymbol" SG_ 952 StaticCornerLightLamp_stat_ISig_ "StaticCornerLightLamp_stat_ISig_4";
BA_ "GenSigCycleTime" SG_ 952 AuxLamp_Front_Status 100;
BA_ "GenSigCycleTimeActive" SG_ 952 AuxLamp_Front_Status 100;
BA_ "GenSigStartValue" SG_ 952 AuxLamp_Front_Status 3;
BA_ "GenSigMaxLatency" SG_ 952 AuxLamp_Front_Status 59;
BA_ "Platform_VMCU1_Sig" SG_ 952 AuxLamp_Front_Status 1;
BA_ "Platform_Vivis2_Sig" SG_ 952 AuxLamp_Front_Status 1;
BA_ "GenSigCycleTime" SG_ 952 AuxFogLightLamp_stat_ISig_4 100;
BA_ "GenSigCycleTimeActive" SG_ 952 AuxFogLightLamp_stat_ISig_4 100;
BA_ "GenSigInactiveValue" SG_ 952 AuxFogLightLamp_stat_ISig_4 7;
BA_ "GenSigStartValue" SG_ 952 AuxFogLightLamp_stat_ISig_4 7;
BA_ "GenSigMaxLatency" SG_ 952 AuxFogLightLamp_stat_ISig_4 59;
BA_ "Platform_VMCU1_Sig" SG_ 952 AuxFogLightLamp_stat_ISig_4 1;
BA_ "Platform_Vivis2_Sig" SG_ 952 AuxFogLightLamp_stat_ISig_4 1;
BA_ "GenSigCycleTime" SG_ 952 ExtraMainBeamLamp_stat_ISig_4 100;
BA_ "GenSigCycleTimeActive" SG_ 952 ExtraMainBeamLamp_stat_ISig_4 100;
BA_ "GenSigInactiveValue" SG_ 952 ExtraMainBeamLamp_stat_ISig_4 7;
BA_ "GenSigStartValue" SG_ 952 ExtraMainBeamLamp_stat_ISig_4 7;
BA_ "GenSigMaxLatency" SG_ 952 ExtraMainBeamLamp_stat_ISig_4 59;
BA_ "Platform_VMCU1_Sig" SG_ 952 ExtraMainBeamLamp_stat_ISig_4 1;
BA_ "Platform_Vivis2_Sig" SG_ 952 ExtraMainBeamLamp_stat_ISig_4 1;
BA_ "GenSigCycleTime" SG_ 952 AmbientAirTemperature1 100;
BA_ "GenSigCycleTimeActive" SG_ 952 AmbientAirTemperature1 100;
BA_ "GenSigStartValue" SG_ 952 AmbientAirTemperature1 65535;
BA_ "Platform_Vivis2_Sig" SG_ 952 AmbientAirTemperature1 1;
BA_ "GenSigCycleTime" SG_ 952 FogLightFrontLamp_stat_ISig_4 100;
BA_ "GenSigCycleTimeActive" SG_ 952 FogLightFrontLamp_stat_ISig_4 100;
BA_ "GenSigInactiveValue" SG_ 952 FogLightFrontLamp_stat_ISig_4 7;
BA_ "GenSigStartValue" SG_ 952 FogLightFrontLamp_stat_ISig_4 7;
BA_ "GenSigMaxLatency" SG_ 952 FogLightFrontLamp_stat_ISig_4 59;
BA_ "Platform_VMCU1_Sig" SG_ 952 FogLightFrontLamp_stat_ISig_4 1;
BA_ "Platform_Vivis2_Sig" SG_ 952 FogLightFrontLamp_stat_ISig_4 1;
BA_ "GenSigCycleTime" SG_ 952 DirInd_Front_Status_ISig_4 100;
BA_ "GenSigCycleTimeActive" SG_ 952 DirInd_Front_Status_ISig_4 100;
BA_ "GenSigStartValue" SG_ 952 DirInd_Front_Status_ISig_4 7;
BA_ "GenSigMaxLatency" SG_ 952 DirInd_Front_Status_ISig_4 59;
BA_ "Platform_VMCU1_Sig" SG_ 952 DirInd_Front_Status_ISig_4 1;
BA_ "Platform_Vivis2_Sig" SG_ 952 DirInd_Front_Status_ISig_4 1;
BA_ "GenSigCycleTime" SG_ 952 ChassiInstepLightsLamp_stat_ISig 100;
BA_ "GenSigCycleTimeActive" SG_ 952 ChassiInstepLightsLamp_stat_ISig 100;
BA_ "GenSigInactiveValue" SG_ 952 ChassiInstepLightsLamp_stat_ISig 7;
BA_ "GenSigStartValue" SG_ 952 ChassiInstepLightsLamp_stat_ISig 7;
BA_ "GenSigMaxLatency" SG_ 952 ChassiInstepLightsLamp_stat_ISig 59;
BA_ "Platform_VMCU1_Sig" SG_ 952 ChassiInstepLightsLamp_stat_ISig 1;
BA_ "Platform_Vivis2_Sig" SG_ 952 ChassiInstepLightsLamp_stat_ISig 1;
BA_ "SystemSignalLongSymbol" SG_ 952 ChassiInstepLightsLamp_stat_ISig "ChassiInstepLightsLamp_stat_ISig_4";
BA_ "GenSigCycleTime" SG_ 952 WasherFluidLevel 100;
BA_ "GenSigCycleTimeActive" SG_ 952 WasherFluidLevel 100;
BA_ "GenSigStartValue" SG_ 952 WasherFluidLevel 7;
BA_ "GenSigMaxLatency" SG_ 952 WasherFluidLevel 59;
BA_ "Platform_VMCU1_Sig" SG_ 952 WasherFluidLevel 1;
BA_ "Platform_Vivis2_Sig" SG_ 952 WasherFluidLevel 1;
BA_ "GenSigCycleTime" SG_ 1511 Trailer5TireInfoISO_Temperature_ 100;
BA_ "GenSigCycleTimeActive" SG_ 1511 Trailer5TireInfoISO_Temperature_ 100;
BA_ "GenSigStartValue" SG_ 1511 Trailer5TireInfoISO_Temperature_ 65535;
BA_ "SystemSignalLongSymbol" SG_ 1511 Trailer5TireInfoISO_Temperature_ "Trailer5TireInfoISO_Temperature_ISig_4";
BA_ "GenSigCycleTime" SG_ 1511 Trailer5TireInfoISO_Pressure_ISi 100;
BA_ "GenSigCycleTimeActive" SG_ 1511 Trailer5TireInfoISO_Pressure_ISi 100;
BA_ "GenSigStartValue" SG_ 1511 Trailer5TireInfoISO_Pressure_ISi 255;
BA_ "SystemSignalLongSymbol" SG_ 1511 Trailer5TireInfoISO_Pressure_ISi "Trailer5TireInfoISO_Pressure_ISig_4";
BA_ "GenSigCycleTime" SG_ 1511 Trailer5TireInfoISO_Leakage_ISig 100;
BA_ "GenSigCycleTimeActive" SG_ 1511 Trailer5TireInfoISO_Leakage_ISig 100;
BA_ "GenSigStartValue" SG_ 1511 Trailer5TireInfoISO_Leakage_ISig 65535;
BA_ "SystemSignalLongSymbol" SG_ 1511 Trailer5TireInfoISO_Leakage_ISig "Trailer5TireInfoISO_Leakage_ISig_4";
BA_ "GenSigCycleTime" SG_ 1511 Trailer5TireInfoISO_PresSuff_ISi 100;
BA_ "GenSigCycleTimeActive" SG_ 1511 Trailer5TireInfoISO_PresSuff_ISi 100;
BA_ "GenSigStartValue" SG_ 1511 Trailer5TireInfoISO_PresSuff_ISi 3;
BA_ "SystemSignalLongSymbol" SG_ 1511 Trailer5TireInfoISO_PresSuff_ISi "Trailer5TireInfoISO_PresSuff_ISig_4";
BA_ "GenSigCycleTime" SG_ 1511 Trailer5TireInfoISO_PowerSupply_ 100;
BA_ "GenSigCycleTimeActive" SG_ 1511 Trailer5TireInfoISO_PowerSupply_ 100;
BA_ "GenSigStartValue" SG_ 1511 Trailer5TireInfoISO_PowerSupply_ 3;
BA_ "SystemSignalLongSymbol" SG_ 1511 Trailer5TireInfoISO_PowerSupply_ "Trailer5TireInfoISO_PowerSupply_ISig_4";
BA_ "GenSigCycleTime" SG_ 1511 Trailer5TireInfoISO_Warning_ISig 100;
BA_ "GenSigCycleTimeActive" SG_ 1511 Trailer5TireInfoISO_Warning_ISig 100;
BA_ "GenSigStartValue" SG_ 1511 Trailer5TireInfoISO_Warning_ISig 7;
BA_ "SystemSignalLongSymbol" SG_ 1511 Trailer5TireInfoISO_Warning_ISig "Trailer5TireInfoISO_Warning_ISig_4";
BA_ "GenSigCycleTime" SG_ 1511 Trailer5TireInfoISO_TireId_ISig_ 100;
BA_ "GenSigCycleTimeActive" SG_ 1511 Trailer5TireInfoISO_TireId_ISig_ 100;
BA_ "SystemSignalLongSymbol" SG_ 1511 Trailer5TireInfoISO_TireId_ISig_ "Trailer5TireInfoISO_TireId_ISig_4";
BA_ "GenSigCycleTime" SG_ 1511 Trailer5TireInfoISO_Active_ISig_ 100;
BA_ "GenSigCycleTimeActive" SG_ 1511 Trailer5TireInfoISO_Active_ISig_ 100;
BA_ "GenSigStartValue" SG_ 1511 Trailer5TireInfoISO_Active_ISig_ 3;
BA_ "SystemSignalLongSymbol" SG_ 1511 Trailer5TireInfoISO_Active_ISig_ "Trailer5TireInfoISO_Active_ISig_4";
BA_ "GenSigCycleTime" SG_ 1509 Trailer4TireInfoISO_Temperature_ 100;
BA_ "GenSigCycleTimeActive" SG_ 1509 Trailer4TireInfoISO_Temperature_ 100;
BA_ "GenSigStartValue" SG_ 1509 Trailer4TireInfoISO_Temperature_ 65535;
BA_ "SystemSignalLongSymbol" SG_ 1509 Trailer4TireInfoISO_Temperature_ "Trailer4TireInfoISO_Temperature_ISig_4";
BA_ "GenSigCycleTime" SG_ 1509 Trailer4TireInfoISO_PresSuff_ISi 100;
BA_ "GenSigCycleTimeActive" SG_ 1509 Trailer4TireInfoISO_PresSuff_ISi 100;
BA_ "GenSigStartValue" SG_ 1509 Trailer4TireInfoISO_PresSuff_ISi 3;
BA_ "SystemSignalLongSymbol" SG_ 1509 Trailer4TireInfoISO_PresSuff_ISi "Trailer4TireInfoISO_PresSuff_ISig_4";
BA_ "GenSigCycleTime" SG_ 1509 Trailer4TireInfoISO_Leakage_ISig 100;
BA_ "GenSigCycleTimeActive" SG_ 1509 Trailer4TireInfoISO_Leakage_ISig 100;
BA_ "GenSigStartValue" SG_ 1509 Trailer4TireInfoISO_Leakage_ISig 65535;
BA_ "SystemSignalLongSymbol" SG_ 1509 Trailer4TireInfoISO_Leakage_ISig "Trailer4TireInfoISO_Leakage_ISig_4";
BA_ "GenSigCycleTime" SG_ 1509 Trailer4TireInfoISO_PowerSupply_ 100;
BA_ "GenSigCycleTimeActive" SG_ 1509 Trailer4TireInfoISO_PowerSupply_ 100;
BA_ "GenSigStartValue" SG_ 1509 Trailer4TireInfoISO_PowerSupply_ 3;
BA_ "SystemSignalLongSymbol" SG_ 1509 Trailer4TireInfoISO_PowerSupply_ "Trailer4TireInfoISO_PowerSupply_ISig_4";
BA_ "GenSigCycleTime" SG_ 1509 Trailer4TireInfoISO_Warning_ISig 100;
BA_ "GenSigCycleTimeActive" SG_ 1509 Trailer4TireInfoISO_Warning_ISig 100;
BA_ "GenSigStartValue" SG_ 1509 Trailer4TireInfoISO_Warning_ISig 7;
BA_ "SystemSignalLongSymbol" SG_ 1509 Trailer4TireInfoISO_Warning_ISig "Trailer4TireInfoISO_Warning_ISig_4";
BA_ "GenSigCycleTime" SG_ 1509 Trailer4TireInfoISO_TireId_ISig_ 100;
BA_ "GenSigCycleTimeActive" SG_ 1509 Trailer4TireInfoISO_TireId_ISig_ 100;
BA_ "SystemSignalLongSymbol" SG_ 1509 Trailer4TireInfoISO_TireId_ISig_ "Trailer4TireInfoISO_TireId_ISig_4";
BA_ "GenSigCycleTime" SG_ 1509 Trailer4TireInfoISO_Pressure_ISi 100;
BA_ "GenSigCycleTimeActive" SG_ 1509 Trailer4TireInfoISO_Pressure_ISi 100;
BA_ "GenSigStartValue" SG_ 1509 Trailer4TireInfoISO_Pressure_ISi 255;
BA_ "SystemSignalLongSymbol" SG_ 1509 Trailer4TireInfoISO_Pressure_ISi "Trailer4TireInfoISO_Pressure_ISig_4";
BA_ "GenSigCycleTime" SG_ 1509 Trailer4TireInfoISO_Active_ISig_ 100;
BA_ "GenSigCycleTimeActive" SG_ 1509 Trailer4TireInfoISO_Active_ISig_ 100;
BA_ "GenSigStartValue" SG_ 1509 Trailer4TireInfoISO_Active_ISig_ 3;
BA_ "SystemSignalLongSymbol" SG_ 1509 Trailer4TireInfoISO_Active_ISig_ "Trailer4TireInfoISO_Active_ISig_4";
BA_ "GenSigCycleTime" SG_ 1508 Trailer3TireInfoISO_Active_ISig_ 100;
BA_ "GenSigCycleTimeActive" SG_ 1508 Trailer3TireInfoISO_Active_ISig_ 100;
BA_ "GenSigStartValue" SG_ 1508 Trailer3TireInfoISO_Active_ISig_ 3;
BA_ "SystemSignalLongSymbol" SG_ 1508 Trailer3TireInfoISO_Active_ISig_ "Trailer3TireInfoISO_Active_ISig_4";
BA_ "GenSigCycleTime" SG_ 1508 Trailer3TireInfoISO_Warning_ISig 100;
BA_ "GenSigCycleTimeActive" SG_ 1508 Trailer3TireInfoISO_Warning_ISig 100;
BA_ "GenSigStartValue" SG_ 1508 Trailer3TireInfoISO_Warning_ISig 7;
BA_ "SystemSignalLongSymbol" SG_ 1508 Trailer3TireInfoISO_Warning_ISig "Trailer3TireInfoISO_Warning_ISig_4";
BA_ "GenSigCycleTime" SG_ 1508 Trailer3TireInfoISO_TireId_ISig_ 100;
BA_ "GenSigCycleTimeActive" SG_ 1508 Trailer3TireInfoISO_TireId_ISig_ 100;
BA_ "SystemSignalLongSymbol" SG_ 1508 Trailer3TireInfoISO_TireId_ISig_ "Trailer3TireInfoISO_TireId_ISig_4";
BA_ "GenSigCycleTime" SG_ 1508 Trailer3TireInfoISO_Pressure_ISi 100;
BA_ "GenSigCycleTimeActive" SG_ 1508 Trailer3TireInfoISO_Pressure_ISi 100;
BA_ "GenSigStartValue" SG_ 1508 Trailer3TireInfoISO_Pressure_ISi 255;
BA_ "SystemSignalLongSymbol" SG_ 1508 Trailer3TireInfoISO_Pressure_ISi "Trailer3TireInfoISO_Pressure_ISig_4";
BA_ "GenSigCycleTime" SG_ 1508 Trailer3TireInfoISO_Temperature_ 100;
BA_ "GenSigCycleTimeActive" SG_ 1508 Trailer3TireInfoISO_Temperature_ 100;
BA_ "GenSigStartValue" SG_ 1508 Trailer3TireInfoISO_Temperature_ 65535;
BA_ "SystemSignalLongSymbol" SG_ 1508 Trailer3TireInfoISO_Temperature_ "Trailer3TireInfoISO_Temperature_ISig_4";
BA_ "GenSigCycleTime" SG_ 1508 Trailer3TireInfoISO_Leakage_ISig 100;
BA_ "GenSigCycleTimeActive" SG_ 1508 Trailer3TireInfoISO_Leakage_ISig 100;
BA_ "GenSigStartValue" SG_ 1508 Trailer3TireInfoISO_Leakage_ISig 65535;
BA_ "SystemSignalLongSymbol" SG_ 1508 Trailer3TireInfoISO_Leakage_ISig "Trailer3TireInfoISO_Leakage_ISig_4";
BA_ "GenSigCycleTime" SG_ 1508 Trailer3TireInfoISO_PowerSupply_ 100;
BA_ "GenSigCycleTimeActive" SG_ 1508 Trailer3TireInfoISO_PowerSupply_ 100;
BA_ "GenSigStartValue" SG_ 1508 Trailer3TireInfoISO_PowerSupply_ 3;
BA_ "SystemSignalLongSymbol" SG_ 1508 Trailer3TireInfoISO_PowerSupply_ "Trailer3TireInfoISO_PowerSupply_ISig_4";
BA_ "GenSigCycleTime" SG_ 1508 Trailer3TireInfoISO_PresSuff_ISi 100;
BA_ "GenSigCycleTimeActive" SG_ 1508 Trailer3TireInfoISO_PresSuff_ISi 100;
BA_ "GenSigStartValue" SG_ 1508 Trailer3TireInfoISO_PresSuff_ISi 3;
BA_ "SystemSignalLongSymbol" SG_ 1508 Trailer3TireInfoISO_PresSuff_ISi "Trailer3TireInfoISO_PresSuff_ISig_4";
BA_ "GenSigSendType" SG_ 41 PLCMsgStat_MsgErrCode_ISig_4 1;
BA_ "GenSigCycleTime" SG_ 41 PLCMsgStat_MsgErrCode_ISig_4 100;
BA_ "GenSigCycleTimeActive" SG_ 41 PLCMsgStat_MsgErrCode_ISig_4 100;
BA_ "GenSigStartValue" SG_ 41 PLCMsgStat_MsgErrCode_ISig_4 255;
BA_ "GenSigSendType" SG_ 41 PLCMsgStat_TxRetryCnt_ISig_4 1;
BA_ "GenSigCycleTime" SG_ 41 PLCMsgStat_TxRetryCnt_ISig_4 100;
BA_ "GenSigCycleTimeActive" SG_ 41 PLCMsgStat_TxRetryCnt_ISig_4 100;
BA_ "GenSigStartValue" SG_ 41 PLCMsgStat_TxRetryCnt_ISig_4 255;
BA_ "GenSigSendType" SG_ 41 PLCMsgStat_MsgStatus_ISig_4 1;
BA_ "GenSigCycleTime" SG_ 41 PLCMsgStat_MsgStatus_ISig_4 100;
BA_ "GenSigCycleTimeActive" SG_ 41 PLCMsgStat_MsgStatus_ISig_4 100;
BA_ "GenSigStartValue" SG_ 41 PLCMsgStat_MsgStatus_ISig_4 255;
BA_ "GenSigSendType" SG_ 41 PLCMsgStat_TxArbtrnFailCnt_ISig_ 1;
BA_ "GenSigCycleTime" SG_ 41 PLCMsgStat_TxArbtrnFailCnt_ISig_ 100;
BA_ "GenSigCycleTimeActive" SG_ 41 PLCMsgStat_TxArbtrnFailCnt_ISig_ 100;
BA_ "GenSigStartValue" SG_ 41 PLCMsgStat_TxArbtrnFailCnt_ISig_ 255;
BA_ "SystemSignalLongSymbol" SG_ 41 PLCMsgStat_TxArbtrnFailCnt_ISig_ "PLCMsgStat_TxArbtrnFailCnt_ISig_4";
BA_ "GenSigSendType" SG_ 1506 EBS_Chassi_18S_FCS 7;
BA_ "GenSigSendType" SG_ 1505 PhyDiagBrk2TPMReqSig_ISig_4 1;
BA_ "GenSigCycleTime" SG_ 1505 PhyDiagBrk2TPMReqSig_ISig_4 100;
BA_ "GenSigCycleTimeActive" SG_ 1505 PhyDiagBrk2TPMReqSig_ISig_4 100;
BA_ "GenSigCycleTime" SG_ 959 WhlSpdSenTothCnt456_Axle6Left_IS 100;
BA_ "GenSigCycleTimeActive" SG_ 959 WhlSpdSenTothCnt456_Axle6Left_IS 100;
BA_ "GenSigStartValue" SG_ 959 WhlSpdSenTothCnt456_Axle6Left_IS 255;
BA_ "SystemSignalLongSymbol" SG_ 959 WhlSpdSenTothCnt456_Axle6Left_IS "WhlSpdSenTothCnt456_Axle6Left_ISig_4";
BA_ "GenSigCycleTime" SG_ 959 WhlSpdSenTothCnt456_Axle5Right_I 100;
BA_ "GenSigCycleTimeActive" SG_ 959 WhlSpdSenTothCnt456_Axle5Right_I 100;
BA_ "GenSigStartValue" SG_ 959 WhlSpdSenTothCnt456_Axle5Right_I 255;
BA_ "SystemSignalLongSymbol" SG_ 959 WhlSpdSenTothCnt456_Axle5Right_I "WhlSpdSenTothCnt456_Axle5Right_ISig_4";
BA_ "GenSigCycleTime" SG_ 959 WhlSpdSenTothCnt456_Axle5Left_IS 100;
BA_ "GenSigCycleTimeActive" SG_ 959 WhlSpdSenTothCnt456_Axle5Left_IS 100;
BA_ "GenSigStartValue" SG_ 959 WhlSpdSenTothCnt456_Axle5Left_IS 255;
BA_ "SystemSignalLongSymbol" SG_ 959 WhlSpdSenTothCnt456_Axle5Left_IS "WhlSpdSenTothCnt456_Axle5Left_ISig_4";
BA_ "GenSigCycleTime" SG_ 959 WhlSpdSenTothCnt456_Axle4Right_I 100;
BA_ "GenSigCycleTimeActive" SG_ 959 WhlSpdSenTothCnt456_Axle4Right_I 100;
BA_ "GenSigStartValue" SG_ 959 WhlSpdSenTothCnt456_Axle4Right_I 255;
BA_ "SystemSignalLongSymbol" SG_ 959 WhlSpdSenTothCnt456_Axle4Right_I "WhlSpdSenTothCnt456_Axle4Right_ISig_4";
BA_ "GenSigCycleTime" SG_ 959 WhlSpdSenTothCnt456_TimeStamp_IS 100;
BA_ "GenSigCycleTimeActive" SG_ 959 WhlSpdSenTothCnt456_TimeStamp_IS 100;
BA_ "GenSigStartValue" SG_ 959 WhlSpdSenTothCnt456_TimeStamp_IS 65535;
BA_ "SystemSignalLongSymbol" SG_ 959 WhlSpdSenTothCnt456_TimeStamp_IS "WhlSpdSenTothCnt456_TimeStamp_ISig_4";
BA_ "GenSigCycleTime" SG_ 959 WhlSpdSenTothCnt456_Axle6Right_I 100;
BA_ "GenSigCycleTimeActive" SG_ 959 WhlSpdSenTothCnt456_Axle6Right_I 100;
BA_ "GenSigStartValue" SG_ 959 WhlSpdSenTothCnt456_Axle6Right_I 255;
BA_ "SystemSignalLongSymbol" SG_ 959 WhlSpdSenTothCnt456_Axle6Right_I "WhlSpdSenTothCnt456_Axle6Right_ISig_4";
BA_ "GenSigCycleTime" SG_ 959 WhlSpdSenTothCnt456_Axle4Left_IS 100;
BA_ "GenSigCycleTimeActive" SG_ 959 WhlSpdSenTothCnt456_Axle4Left_IS 100;
BA_ "GenSigStartValue" SG_ 959 WhlSpdSenTothCnt456_Axle4Left_IS 255;
BA_ "SystemSignalLongSymbol" SG_ 959 WhlSpdSenTothCnt456_Axle4Left_IS "WhlSpdSenTothCnt456_Axle4Left_ISig_4";
BA_ "GenSigCycleTime" SG_ 832 WhlSpdSenTothCnt123_TimeStamp_IS 100;
BA_ "GenSigCycleTimeActive" SG_ 832 WhlSpdSenTothCnt123_TimeStamp_IS 100;
BA_ "GenSigStartValue" SG_ 832 WhlSpdSenTothCnt123_TimeStamp_IS 65535;
BA_ "SystemSignalLongSymbol" SG_ 832 WhlSpdSenTothCnt123_TimeStamp_IS "WhlSpdSenTothCnt123_TimeStamp_ISig_4";
BA_ "GenSigCycleTime" SG_ 832 WhlSpdSenTothCnt123_Axle2Right_I 100;
BA_ "GenSigCycleTimeActive" SG_ 832 WhlSpdSenTothCnt123_Axle2Right_I 100;
BA_ "GenSigStartValue" SG_ 832 WhlSpdSenTothCnt123_Axle2Right_I 255;
BA_ "SystemSignalLongSymbol" SG_ 832 WhlSpdSenTothCnt123_Axle2Right_I "WhlSpdSenTothCnt123_Axle2Right_ISig_4";
BA_ "GenSigCycleTime" SG_ 832 WhlSpdSenTothCnt123_Axle3Right_I 100;
BA_ "GenSigCycleTimeActive" SG_ 832 WhlSpdSenTothCnt123_Axle3Right_I 100;
BA_ "GenSigStartValue" SG_ 832 WhlSpdSenTothCnt123_Axle3Right_I 255;
BA_ "SystemSignalLongSymbol" SG_ 832 WhlSpdSenTothCnt123_Axle3Right_I "WhlSpdSenTothCnt123_Axle3Right_ISig_4";
BA_ "GenSigCycleTime" SG_ 832 WhlSpdSenTothCnt123_Axle1Right_I 100;
BA_ "GenSigCycleTimeActive" SG_ 832 WhlSpdSenTothCnt123_Axle1Right_I 100;
BA_ "GenSigStartValue" SG_ 832 WhlSpdSenTothCnt123_Axle1Right_I 255;
BA_ "SystemSignalLongSymbol" SG_ 832 WhlSpdSenTothCnt123_Axle1Right_I "WhlSpdSenTothCnt123_Axle1Right_ISig_4";
BA_ "GenSigCycleTime" SG_ 832 WhlSpdSenTothCnt123_Axle1Left_IS 100;
BA_ "GenSigCycleTimeActive" SG_ 832 WhlSpdSenTothCnt123_Axle1Left_IS 100;
BA_ "GenSigStartValue" SG_ 832 WhlSpdSenTothCnt123_Axle1Left_IS 255;
BA_ "SystemSignalLongSymbol" SG_ 832 WhlSpdSenTothCnt123_Axle1Left_IS "WhlSpdSenTothCnt123_Axle1Left_ISig_4";
BA_ "GenSigCycleTime" SG_ 832 WhlSpdSenTothCnt123_Axle2Left_IS 100;
BA_ "GenSigCycleTimeActive" SG_ 832 WhlSpdSenTothCnt123_Axle2Left_IS 100;
BA_ "GenSigStartValue" SG_ 832 WhlSpdSenTothCnt123_Axle2Left_IS 255;
BA_ "SystemSignalLongSymbol" SG_ 832 WhlSpdSenTothCnt123_Axle2Left_IS "WhlSpdSenTothCnt123_Axle2Left_ISig_4";
BA_ "GenSigCycleTime" SG_ 832 WhlSpdSenTothCnt123_Axle3Left_IS 100;
BA_ "GenSigCycleTimeActive" SG_ 832 WhlSpdSenTothCnt123_Axle3Left_IS 100;
BA_ "GenSigStartValue" SG_ 832 WhlSpdSenTothCnt123_Axle3Left_IS 255;
BA_ "SystemSignalLongSymbol" SG_ 832 WhlSpdSenTothCnt123_Axle3Left_IS "WhlSpdSenTothCnt123_Axle3Left_ISig_4";
BA_ "GenSigCycleTime" SG_ 1232 TrailerCommunicationType_ISig_4 100;
BA_ "GenSigCycleTimeActive" SG_ 1232 TrailerCommunicationType_ISig_4 100;
BA_ "GenSigStartValue" SG_ 1232 TrailerCommunicationType_ISig_4 7;
BA_ "Platform_Vivis2_Sig" SG_ 1232 TrailerCommunicationType_ISig_4 1;
BA_ "GenSigCycleTime" SG_ 1507 PLCBusStatus_ISig_4 100;
BA_ "GenSigCycleTimeActive" SG_ 1507 PLCBusStatus_ISig_4 100;
BA_ "GenSigStartValue" SG_ 1507 PLCBusStatus_ISig_4 255;
BA_ "GenSigCycleTime" SG_ 1501 Trailer2TireInfoISO_PowerSupply_ 100;
BA_ "GenSigCycleTimeActive" SG_ 1501 Trailer2TireInfoISO_PowerSupply_ 100;
BA_ "GenSigStartValue" SG_ 1501 Trailer2TireInfoISO_PowerSupply_ 3;
BA_ "SystemSignalLongSymbol" SG_ 1501 Trailer2TireInfoISO_PowerSupply_ "Trailer2TireInfoISO_PowerSupply_ISig_4";
BA_ "GenSigCycleTime" SG_ 1501 Trailer2TireInfoISO_Temperature_ 100;
BA_ "GenSigCycleTimeActive" SG_ 1501 Trailer2TireInfoISO_Temperature_ 100;
BA_ "GenSigStartValue" SG_ 1501 Trailer2TireInfoISO_Temperature_ 65535;
BA_ "SystemSignalLongSymbol" SG_ 1501 Trailer2TireInfoISO_Temperature_ "Trailer2TireInfoISO_Temperature_ISig_4";
BA_ "GenSigCycleTime" SG_ 1501 Trailer2TireInfoISO_PresSuff_ISi 100;
BA_ "GenSigCycleTimeActive" SG_ 1501 Trailer2TireInfoISO_PresSuff_ISi 100;
BA_ "GenSigStartValue" SG_ 1501 Trailer2TireInfoISO_PresSuff_ISi 3;
BA_ "SystemSignalLongSymbol" SG_ 1501 Trailer2TireInfoISO_PresSuff_ISi "Trailer2TireInfoISO_PresSuff_ISig_4";
BA_ "GenSigCycleTime" SG_ 1501 Trailer2TireInfoISO_Pressure_ISi 100;
BA_ "GenSigCycleTimeActive" SG_ 1501 Trailer2TireInfoISO_Pressure_ISi 100;
BA_ "GenSigStartValue" SG_ 1501 Trailer2TireInfoISO_Pressure_ISi 255;
BA_ "SystemSignalLongSymbol" SG_ 1501 Trailer2TireInfoISO_Pressure_ISi "Trailer2TireInfoISO_Pressure_ISig_4";
BA_ "GenSigCycleTime" SG_ 1501 Trailer2TireInfoISO_Warning_ISig 100;
BA_ "GenSigCycleTimeActive" SG_ 1501 Trailer2TireInfoISO_Warning_ISig 100;
BA_ "GenSigStartValue" SG_ 1501 Trailer2TireInfoISO_Warning_ISig 7;
BA_ "SystemSignalLongSymbol" SG_ 1501 Trailer2TireInfoISO_Warning_ISig "Trailer2TireInfoISO_Warning_ISig_4";
BA_ "GenSigCycleTime" SG_ 1501 Trailer2TireInfoISO_TireId_ISig_ 100;
BA_ "GenSigCycleTimeActive" SG_ 1501 Trailer2TireInfoISO_TireId_ISig_ 100;
BA_ "SystemSignalLongSymbol" SG_ 1501 Trailer2TireInfoISO_TireId_ISig_ "Trailer2TireInfoISO_TireId_ISig_4";
BA_ "GenSigCycleTime" SG_ 1501 Trailer2TireInfoISO_Leakage_ISig 100;
BA_ "GenSigCycleTimeActive" SG_ 1501 Trailer2TireInfoISO_Leakage_ISig 100;
BA_ "GenSigStartValue" SG_ 1501 Trailer2TireInfoISO_Leakage_ISig 65535;
BA_ "SystemSignalLongSymbol" SG_ 1501 Trailer2TireInfoISO_Leakage_ISig "Trailer2TireInfoISO_Leakage_ISig_4";
BA_ "GenSigCycleTime" SG_ 1501 Trailer2TireInfoISO_Active_ISig_ 100;
BA_ "GenSigCycleTimeActive" SG_ 1501 Trailer2TireInfoISO_Active_ISig_ 100;
BA_ "GenSigStartValue" SG_ 1501 Trailer2TireInfoISO_Active_ISig_ 3;
BA_ "SystemSignalLongSymbol" SG_ 1501 Trailer2TireInfoISO_Active_ISig_ "Trailer2TireInfoISO_Active_ISig_4";
BA_ "GenSigCycleTime" SG_ 1498 Trailer1TireInfoISO_Leakage_ISig 100;
BA_ "GenSigCycleTimeActive" SG_ 1498 Trailer1TireInfoISO_Leakage_ISig 100;
BA_ "GenSigStartValue" SG_ 1498 Trailer1TireInfoISO_Leakage_ISig 65535;
BA_ "SystemSignalLongSymbol" SG_ 1498 Trailer1TireInfoISO_Leakage_ISig "Trailer1TireInfoISO_Leakage_ISig_4";
BA_ "GenSigCycleTime" SG_ 1498 Trailer1TireInfoISO_Active_ISig_ 100;
BA_ "GenSigCycleTimeActive" SG_ 1498 Trailer1TireInfoISO_Active_ISig_ 100;
BA_ "GenSigStartValue" SG_ 1498 Trailer1TireInfoISO_Active_ISig_ 3;
BA_ "SystemSignalLongSymbol" SG_ 1498 Trailer1TireInfoISO_Active_ISig_ "Trailer1TireInfoISO_Active_ISig_4";
BA_ "GenSigCycleTime" SG_ 1498 Trailer1TireInfoISO_Warning_ISig 100;
BA_ "GenSigCycleTimeActive" SG_ 1498 Trailer1TireInfoISO_Warning_ISig 100;
BA_ "GenSigStartValue" SG_ 1498 Trailer1TireInfoISO_Warning_ISig 7;
BA_ "SystemSignalLongSymbol" SG_ 1498 Trailer1TireInfoISO_Warning_ISig "Trailer1TireInfoISO_Warning_ISig_4";
BA_ "GenSigCycleTime" SG_ 1498 Trailer1TireInfoISO_PowerSupply_ 100;
BA_ "GenSigCycleTimeActive" SG_ 1498 Trailer1TireInfoISO_PowerSupply_ 100;
BA_ "GenSigStartValue" SG_ 1498 Trailer1TireInfoISO_PowerSupply_ 3;
BA_ "SystemSignalLongSymbol" SG_ 1498 Trailer1TireInfoISO_PowerSupply_ "Trailer1TireInfoISO_PowerSupply_ISig_4";
BA_ "GenSigCycleTime" SG_ 1498 Trailer1TireInfoISO_PresSuff_ISi 100;
BA_ "GenSigCycleTimeActive" SG_ 1498 Trailer1TireInfoISO_PresSuff_ISi 100;
BA_ "GenSigStartValue" SG_ 1498 Trailer1TireInfoISO_PresSuff_ISi 3;
BA_ "SystemSignalLongSymbol" SG_ 1498 Trailer1TireInfoISO_PresSuff_ISi "Trailer1TireInfoISO_PresSuff_ISig_4";
BA_ "GenSigCycleTime" SG_ 1498 Trailer1TireInfoISO_Temperature_ 100;
BA_ "GenSigCycleTimeActive" SG_ 1498 Trailer1TireInfoISO_Temperature_ 100;
BA_ "GenSigStartValue" SG_ 1498 Trailer1TireInfoISO_Temperature_ 65535;
BA_ "SystemSignalLongSymbol" SG_ 1498 Trailer1TireInfoISO_Temperature_ "Trailer1TireInfoISO_Temperature_ISig_4";
BA_ "GenSigCycleTime" SG_ 1498 Trailer1TireInfoISO_TireId_ISig_ 100;
BA_ "GenSigCycleTimeActive" SG_ 1498 Trailer1TireInfoISO_TireId_ISig_ 100;
BA_ "SystemSignalLongSymbol" SG_ 1498 Trailer1TireInfoISO_TireId_ISig_ "Trailer1TireInfoISO_TireId_ISig_4";
BA_ "GenSigCycleTime" SG_ 1498 Trailer1TireInfoISO_Pressure_ISi 100;
BA_ "GenSigCycleTimeActive" SG_ 1498 Trailer1TireInfoISO_Pressure_ISi 100;
BA_ "GenSigStartValue" SG_ 1498 Trailer1TireInfoISO_Pressure_ISi 255;
BA_ "SystemSignalLongSymbol" SG_ 1498 Trailer1TireInfoISO_Pressure_ISi "Trailer1TireInfoISO_Pressure_ISig_4";
BA_ "GenSigCycleTime" SG_ 396 ThrdRrDriveAxLeftWheelSpeed_ISig 100;
BA_ "GenSigCycleTimeActive" SG_ 396 ThrdRrDriveAxLeftWheelSpeed_ISig 100;
BA_ "GenSigStartValue" SG_ 396 ThrdRrDriveAxLeftWheelSpeed_ISig 65535;
BA_ "Platform_Vivis2_Sig" SG_ 396 ThrdRrDriveAxLeftWheelSpeed_ISig 1;
BA_ "SystemSignalLongSymbol" SG_ 396 ThrdRrDriveAxLeftWheelSpeed_ISig "ThrdRrDriveAxLeftWheelSpeed_ISig_4";
BA_ "GenSigCycleTime" SG_ 396 ThrdRrDriveAxRightWheelSpeed_ISi 100;
BA_ "GenSigCycleTimeActive" SG_ 396 ThrdRrDriveAxRightWheelSpeed_ISi 100;
BA_ "GenSigStartValue" SG_ 396 ThrdRrDriveAxRightWheelSpeed_ISi 65535;
BA_ "Platform_Vivis2_Sig" SG_ 396 ThrdRrDriveAxRightWheelSpeed_ISi 1;
BA_ "SystemSignalLongSymbol" SG_ 396 ThrdRrDriveAxRightWheelSpeed_ISi "ThrdRrDriveAxRightWheelSpeed_ISig_4";
BA_ "GenSigCycleTime" SG_ 395 SteeringWheelAngle_ISig_4 100;
BA_ "GenSigCycleTimeActive" SG_ 395 SteeringWheelAngle_ISig_4 100;
BA_ "GenSigStartValue" SG_ 395 SteeringWheelAngle_ISig_4 65535;
BA_ "GenSigMaxLatency" SG_ 395 SteeringWheelAngle_ISig_4 23;
BA_ "NeedsUpdateBit" SG_ 395 SteeringWheelAngle_ISig_4 1;
BA_ "Platform_VMCU1_Sig" SG_ 395 SteeringWheelAngle_ISig_4 1;
BA_ "Platform_Vivis2_Sig" SG_ 395 SteeringWheelAngle_ISig_4 1;
BA_ "GenSigSendType" SG_ 395 SteeringWheelAngle_UB_ISig_4 7;
BA_ "Platform_VMCU1_Sig" SG_ 395 SteeringWheelAngle_UB_ISig_4 1;
BA_ "Platform_Vivis2_Sig" SG_ 395 SteeringWheelAngle_UB_ISig_4 1;
BA_ "GenSigCycleTime" SG_ 394 ScndRrDriveAxleLeftWheelSpeed_IS 100;
BA_ "GenSigCycleTimeActive" SG_ 394 ScndRrDriveAxleLeftWheelSpeed_IS 100;
BA_ "GenSigStartValue" SG_ 394 ScndRrDriveAxleLeftWheelSpeed_IS 65535;
BA_ "GenSigMaxLatency" SG_ 394 ScndRrDriveAxleLeftWheelSpeed_IS 22;
BA_ "Platform_VMCU1_Sig" SG_ 394 ScndRrDriveAxleLeftWheelSpeed_IS 1;
BA_ "Platform_Vivis2_Sig" SG_ 394 ScndRrDriveAxleLeftWheelSpeed_IS 1;
BA_ "SystemSignalLongSymbol" SG_ 394 ScndRrDriveAxleLeftWheelSpeed_IS "ScndRrDriveAxleLeftWheelSpeed_ISig_4";
BA_ "GenSigCycleTime" SG_ 394 ScndRrDriveAxleRightWheelSpeed_I 100;
BA_ "GenSigCycleTimeActive" SG_ 394 ScndRrDriveAxleRightWheelSpeed_I 100;
BA_ "GenSigStartValue" SG_ 394 ScndRrDriveAxleRightWheelSpeed_I 65535;
BA_ "GenSigMaxLatency" SG_ 394 ScndRrDriveAxleRightWheelSpeed_I 22;
BA_ "Platform_VMCU1_Sig" SG_ 394 ScndRrDriveAxleRightWheelSpeed_I 1;
BA_ "Platform_Vivis2_Sig" SG_ 394 ScndRrDriveAxleRightWheelSpeed_I 1;
BA_ "SystemSignalLongSymbol" SG_ 394 ScndRrDriveAxleRightWheelSpeed_I "ScndRrDriveAxleRightWheelSpeed_ISig_4";
BA_ "GenSigCycleTime" SG_ 386 LateralAcceleration_ISig_4 100;
BA_ "GenSigCycleTimeActive" SG_ 386 LateralAcceleration_ISig_4 100;
BA_ "GenSigStartValue" SG_ 386 LateralAcceleration_ISig_4 65535;
BA_ "GenSigMaxLatency" SG_ 386 LateralAcceleration_ISig_4 20;
BA_ "Platform_VMCU1_Sig" SG_ 386 LateralAcceleration_ISig_4 1;
BA_ "Platform_Vivis2_Sig" SG_ 386 LateralAcceleration_ISig_4 1;
BA_ "GenSigCycleTime" SG_ 386 VDCBrakeLightRequest_ISig_4 100;
BA_ "GenSigCycleTimeActive" SG_ 386 VDCBrakeLightRequest_ISig_4 100;
BA_ "GenSigStartValue" SG_ 386 VDCBrakeLightRequest_ISig_4 3;
BA_ "GenSigMaxLatency" SG_ 386 VDCBrakeLightRequest_ISig_4 20;
BA_ "Platform_VMCU1_Sig" SG_ 386 VDCBrakeLightRequest_ISig_4 1;
BA_ "Platform_Vivis2_Sig" SG_ 386 VDCBrakeLightRequest_ISig_4 1;
BA_ "GenSigCycleTime" SG_ 386 EBSBrakeSwitch_ISig_4 100;
BA_ "GenSigCycleTimeActive" SG_ 386 EBSBrakeSwitch_ISig_4 100;
BA_ "GenSigStartValue" SG_ 386 EBSBrakeSwitch_ISig_4 3;
BA_ "GenSigMaxLatency" SG_ 386 EBSBrakeSwitch_ISig_4 20;
BA_ "Platform_VMCU1_Sig" SG_ 386 EBSBrakeSwitch_ISig_4 1;
BA_ "Platform_Vivis2_Sig" SG_ 386 EBSBrakeSwitch_ISig_4 1;
BA_ "GenSigCycleTime" SG_ 386 BrakeLightActivationRequest_ISig 100;
BA_ "GenSigCycleTimeActive" SG_ 386 BrakeLightActivationRequest_ISig 100;
BA_ "GenSigStartValue" SG_ 386 BrakeLightActivationRequest_ISig 3;
BA_ "Platform_VMCU1_Sig" SG_ 386 BrakeLightActivationRequest_ISig 1;
BA_ "Platform_Vivis2_Sig" SG_ 386 BrakeLightActivationRequest_ISig 1;
BA_ "SystemSignalLongSymbol" SG_ 386 BrakeLightActivationRequest_ISig "BrakeLightActivationRequest_ISig_4";
BA_ "GenSigCycleTime" SG_ 386 LongitudinalAcceleration_ISig_4 100;
BA_ "GenSigCycleTimeActive" SG_ 386 LongitudinalAcceleration_ISig_4 100;
BA_ "GenSigStartValue" SG_ 386 LongitudinalAcceleration_ISig_4 65535;
BA_ "GenSigMaxLatency" SG_ 386 LongitudinalAcceleration_ISig_4 20;
BA_ "Platform_VMCU1_Sig" SG_ 386 LongitudinalAcceleration_ISig_4 1;
BA_ "Platform_Vivis2_Sig" SG_ 386 LongitudinalAcceleration_ISig_4 1;
BA_ "GenSigCycleTime" SG_ 824 Trailer1TractionHelp_ISig_4 100;
BA_ "GenSigCycleTimeActive" SG_ 824 Trailer1TractionHelp_ISig_4 100;
BA_ "GenSigStartValue" SG_ 824 Trailer1TractionHelp_ISig_4 3;
BA_ "GenSigMaxLatency" SG_ 824 Trailer1TractionHelp_ISig_4 35;
BA_ "Platform_VMCU1_Sig" SG_ 824 Trailer1TractionHelp_ISig_4 1;
BA_ "Platform_Vivis2_Sig" SG_ 824 Trailer1TractionHelp_ISig_4 1;
BA_ "GenSigCycleTime" SG_ 824 TrailerBrake_Stat_ISig_4 100;
BA_ "GenSigCycleTimeActive" SG_ 824 TrailerBrake_Stat_ISig_4 100;
BA_ "GenSigStartValue" SG_ 824 TrailerBrake_Stat_ISig_4 3;
BA_ "GenSigMaxLatency" SG_ 824 TrailerBrake_Stat_ISig_4 35;
BA_ "Platform_VMCU1_Sig" SG_ 824 TrailerBrake_Stat_ISig_4 1;
BA_ "Platform_Vivis2_Sig" SG_ 824 TrailerBrake_Stat_ISig_4 1;
BA_ "GenSigCycleTime" SG_ 824 SplitBoxDiffLockActvnFuncReq_ISi 100;
BA_ "GenSigCycleTimeActive" SG_ 824 SplitBoxDiffLockActvnFuncReq_ISi 100;
BA_ "GenSigStartValue" SG_ 824 SplitBoxDiffLockActvnFuncReq_ISi 3;
BA_ "Platform_VMCU1_Sig" SG_ 824 SplitBoxDiffLockActvnFuncReq_ISi 1;
BA_ "Platform_Vivis2_Sig" SG_ 824 SplitBoxDiffLockActvnFuncReq_ISi 1;
BA_ "SystemSignalLongSymbol" SG_ 824 SplitBoxDiffLockActvnFuncReq_ISi "SplitBoxDiffLockActvnFuncReq_ISig_4";
BA_ "GenSigCycleTime" SG_ 824 BrakingSystemPressureLim_rqst_IS 100;
BA_ "GenSigCycleTimeActive" SG_ 824 BrakingSystemPressureLim_rqst_IS 100;
BA_ "GenSigStartValue" SG_ 824 BrakingSystemPressureLim_rqst_IS 3;
BA_ "GenSigMaxLatency" SG_ 824 BrakingSystemPressureLim_rqst_IS 107;
BA_ "Platform_VMCU1_Sig" SG_ 824 BrakingSystemPressureLim_rqst_IS 1;
BA_ "Platform_Vivis2_Sig" SG_ 824 BrakingSystemPressureLim_rqst_IS 1;
BA_ "SystemSignalLongSymbol" SG_ 824 BrakingSystemPressureLim_rqst_IS "BrakingSystemPressureLim_rqst_ISig_4";
BA_ "GenSigCycleTime" SG_ 824 TagLiftAxleLoweringInhibit 100;
BA_ "GenSigCycleTimeActive" SG_ 824 TagLiftAxleLoweringInhibit 100;
BA_ "GenSigStartValue" SG_ 824 TagLiftAxleLoweringInhibit 3;
BA_ "GenSigMaxLatency" SG_ 824 TagLiftAxleLoweringInhibit 35;
BA_ "Platform_VMCU1_Sig" SG_ 824 TagLiftAxleLoweringInhibit 1;
BA_ "Platform_Vivis2_Sig" SG_ 824 TagLiftAxleLoweringInhibit 1;
BA_ "GenSigCycleTime" SG_ 824 ScndRrAxlDiffLckActvnFuncReq_ISi 100;
BA_ "GenSigCycleTimeActive" SG_ 824 ScndRrAxlDiffLckActvnFuncReq_ISi 100;
BA_ "GenSigStartValue" SG_ 824 ScndRrAxlDiffLckActvnFuncReq_ISi 3;
BA_ "Platform_Vivis2_Sig" SG_ 824 ScndRrAxlDiffLckActvnFuncReq_ISi 1;
BA_ "SystemSignalLongSymbol" SG_ 824 ScndRrAxlDiffLckActvnFuncReq_ISi "ScndRrAxlDiffLckActvnFuncReq_ISig_4";
BA_ "GenSigCycleTime" SG_ 824 Trailer1LiftAxle1Pos_ISig_4 100;
BA_ "GenSigCycleTimeActive" SG_ 824 Trailer1LiftAxle1Pos_ISig_4 100;
BA_ "GenSigStartValue" SG_ 824 Trailer1LiftAxle1Pos_ISig_4 3;
BA_ "Platform_Vivis2_Sig" SG_ 824 Trailer1LiftAxle1Pos_ISig_4 1;
BA_ "GenSigCycleTime" SG_ 824 PusherLiftAxleLoweringInhibit_IS 100;
BA_ "GenSigCycleTimeActive" SG_ 824 PusherLiftAxleLoweringInhibit_IS 100;
BA_ "GenSigStartValue" SG_ 824 PusherLiftAxleLoweringInhibit_IS 3;
BA_ "GenSigMaxLatency" SG_ 824 PusherLiftAxleLoweringInhibit_IS 35;
BA_ "Platform_VMCU1_Sig" SG_ 824 PusherLiftAxleLoweringInhibit_IS 1;
BA_ "Platform_Vivis2_Sig" SG_ 824 PusherLiftAxleLoweringInhibit_IS 1;
BA_ "SystemSignalLongSymbol" SG_ 824 PusherLiftAxleLoweringInhibit_IS "PusherLiftAxleLoweringInhibit_ISig_4";
BA_ "GenSigCycleTime" SG_ 824 StretchBrake_Stat_ISig_4 100;
BA_ "GenSigCycleTimeActive" SG_ 824 StretchBrake_Stat_ISig_4 100;
BA_ "GenSigStartValue" SG_ 824 StretchBrake_Stat_ISig_4 7;
BA_ "GenSigMaxLatency" SG_ 824 StretchBrake_Stat_ISig_4 35;
BA_ "Platform_VMCU1_Sig" SG_ 824 StretchBrake_Stat_ISig_4 1;
BA_ "Platform_Vivis2_Sig" SG_ 824 StretchBrake_Stat_ISig_4 1;
BA_ "GenSigCycleTime" SG_ 824 TrailersConnected_ISig_4 100;
BA_ "GenSigCycleTimeActive" SG_ 824 TrailersConnected_ISig_4 100;
BA_ "GenSigInactiveValue" SG_ 824 TrailersConnected_ISig_4 7;
BA_ "GenSigStartValue" SG_ 824 TrailersConnected_ISig_4 7;
BA_ "GenSigMaxLatency" SG_ 824 TrailersConnected_ISig_4 35;
BA_ "Platform_VMCU1_Sig" SG_ 824 TrailersConnected_ISig_4 1;
BA_ "Platform_Vivis2_Sig" SG_ 824 TrailersConnected_ISig_4 1;
BA_ "GenSigCycleTime" SG_ 824 Trailer1LiftAxle2Pos_ISig_4 100;
BA_ "GenSigCycleTimeActive" SG_ 824 Trailer1LiftAxle2Pos_ISig_4 100;
BA_ "GenSigStartValue" SG_ 824 Trailer1LiftAxle2Pos_ISig_4 3;
BA_ "GenSigMaxLatency" SG_ 824 Trailer1LiftAxle2Pos_ISig_4 35;
BA_ "Platform_VMCU1_Sig" SG_ 824 Trailer1LiftAxle2Pos_ISig_4 1;
BA_ "Platform_Vivis2_Sig" SG_ 824 Trailer1LiftAxle2Pos_ISig_4 1;
BA_ "GenSigCycleTime" SG_ 824 TrailerEBSAmberWarning_ISig_4 100;
BA_ "GenSigCycleTimeActive" SG_ 824 TrailerEBSAmberWarning_ISig_4 100;
BA_ "GenSigStartValue" SG_ 824 TrailerEBSAmberWarning_ISig_4 3;
BA_ "Platform_VMCU1_Sig" SG_ 824 TrailerEBSAmberWarning_ISig_4 1;
BA_ "Platform_Vivis2_Sig" SG_ 824 TrailerEBSAmberWarning_ISig_4 1;
BA_ "GenSigCycleTime" SG_ 516 EASPusherLiftAxleLoweringInhib 100;
BA_ "GenSigCycleTimeActive" SG_ 516 EASPusherLiftAxleLoweringInhib 100;
BA_ "GenSigStartValue" SG_ 516 EASPusherLiftAxleLoweringInhib 3;
BA_ "Platform_VMCU1_Sig" SG_ 516 EASPusherLiftAxleLoweringInhib 1;
BA_ "Platform_Vivis2_Sig" SG_ 516 EASPusherLiftAxleLoweringInhib 1;
BA_ "GenSigSendType" SG_ 2671964787 DiagUUDTRespSig_F2_73_ISig_4 7;
BA_ "GenSigSendType" SG_ 2671964711 DiagUUDTRespSig_F2_27_ISig_4 7;
BA_ "GenSigSendType" SG_ 2671964706 DiagUUDTRespSig_F2_22_ISig_4 7;
BA_ "GenSigSendType" SG_ 2671964705 DiagUUDTRespSig_F2_21_ISig_4 7;
BA_ "GenSigSendType" SG_ 2671964704 DiagUUDTRespSig_F2_20_ISig_4 7;
BA_ "GenSigSendType" SG_ 2671964698 DiagUUDTRespSig_F2_1A_ISig_4 7;
BA_ "GenSigSendType" SG_ 2671834227 InternalTesterDiagSig_F4_73 7;
BA_ "GenSigSendType" SG_ 2671834151 InternalTesterDiagSig_F4_27 7;
BA_ "GenSigSendType" SG_ 2671834146 InternalTesterDiagSig_F4_22 7;
BA_ "GenSigSendType" SG_ 2671834145 InternalTesterDiagSig_F4_21 7;
BA_ "GenSigSendType" SG_ 2671834144 InternalTesterDiagSig_F4_20 7;
BA_ "GenSigSendType" SG_ 2671834138 InternalTesterDiagSig_F4_1A 7;
BA_ "GenSigSendType" SG_ 2671801332 InternalTesterDiagSig_73_F4 7;
BA_ "GenSigSendType" SG_ 2671781876 InternalTesterDiagSig_27_F4 7;
BA_ "GenSigSendType" SG_ 2671780596 InternalTesterDiagSig_22_F4 7;
BA_ "GenSigSendType" SG_ 2671780340 InternalTesterDiagSig_21_F4 7;
BA_ "GenSigSendType" SG_ 2671780084 InternalTesterDiagSig_20_F4 7;
BA_ "GenSigSendType" SG_ 2671778548 InternalTesterDiagSig_1A_F4 7;
BA_ "GenSigSendType" SG_ 1503 DiagFaultStat_WSGW_EcuAdr 3;
BA_ "GenSigStartValue" SG_ 1503 DiagFaultStat_WSGW_EcuAdr 115;
BA_ "NeedsUpdateBit" SG_ 1503 DiagFaultStat_WSGW_EcuAdr 1;
BA_ "GenSigSendType" SG_ 1503 DiagFaultStat_WSGW_FailTB 3;
BA_ "NeedsUpdateBit" SG_ 1503 DiagFaultStat_WSGW_FailTB 1;
BA_ "GenSigSendType" SG_ 1503 DiagFaultStat_WSGW_DtcIdA 3;
BA_ "NeedsUpdateBit" SG_ 1503 DiagFaultStat_WSGW_DtcIdA 1;
BA_ "GenSigSendType" SG_ 1503 DiagFaultStat_WSGW_sg_UB 7;
BA_ "GenSigSendType" SG_ 1503 DiagFaultStat_WSGW_DtcIdB 3;
BA_ "NeedsUpdateBit" SG_ 1503 DiagFaultStat_WSGW_DtcIdB 1;
BA_ "GenSigSendType" SG_ 1503 DiagFaultStat_WSGW_FailTA 3;
BA_ "NeedsUpdateBit" SG_ 1503 DiagFaultStat_WSGW_FailTA 1;
BA_ "GenSigSendType" SG_ 1500 DiagFaultStat_RCIOM_DtcIdB 3;
BA_ "GenSigStartValue" SG_ 1500 DiagFaultStat_RCIOM_DtcIdB 65535;
BA_ "NeedsUpdateBit" SG_ 1500 DiagFaultStat_RCIOM_DtcIdB 1;
BA_ "Platform_VMCU1_Sig" SG_ 1500 DiagFaultStat_RCIOM_DtcIdB 1;
BA_ "Platform_Vivis2_Sig" SG_ 1500 DiagFaultStat_RCIOM_DtcIdB 1;
BA_ "GenSigSendType" SG_ 1500 DiagFaultStat_RCIOM_sg_UB 7;
BA_ "Platform_VMCU1_Sig" SG_ 1500 DiagFaultStat_RCIOM_sg_UB 1;
BA_ "Platform_Vivis2_Sig" SG_ 1500 DiagFaultStat_RCIOM_sg_UB 1;
BA_ "GenSigSendType" SG_ 1500 DiagFaultStat_RCIOM_FailTA 3;
BA_ "GenSigStartValue" SG_ 1500 DiagFaultStat_RCIOM_FailTA 255;
BA_ "NeedsUpdateBit" SG_ 1500 DiagFaultStat_RCIOM_FailTA 1;
BA_ "Platform_VMCU1_Sig" SG_ 1500 DiagFaultStat_RCIOM_FailTA 1;
BA_ "Platform_Vivis2_Sig" SG_ 1500 DiagFaultStat_RCIOM_FailTA 1;
BA_ "GenSigSendType" SG_ 1500 DiagFaultStat_RCIOM_FailTB 3;
BA_ "GenSigStartValue" SG_ 1500 DiagFaultStat_RCIOM_FailTB 255;
BA_ "NeedsUpdateBit" SG_ 1500 DiagFaultStat_RCIOM_FailTB 1;
BA_ "Platform_VMCU1_Sig" SG_ 1500 DiagFaultStat_RCIOM_FailTB 1;
BA_ "Platform_Vivis2_Sig" SG_ 1500 DiagFaultStat_RCIOM_FailTB 1;
BA_ "GenSigSendType" SG_ 1500 DiagFaultStat_RCIOM_DtcIdA 3;
BA_ "GenSigStartValue" SG_ 1500 DiagFaultStat_RCIOM_DtcIdA 65535;
BA_ "NeedsUpdateBit" SG_ 1500 DiagFaultStat_RCIOM_DtcIdA 1;
BA_ "Platform_VMCU1_Sig" SG_ 1500 DiagFaultStat_RCIOM_DtcIdA 1;
BA_ "Platform_Vivis2_Sig" SG_ 1500 DiagFaultStat_RCIOM_DtcIdA 1;
BA_ "GenSigSendType" SG_ 1500 DiagFaultStat_RCIOM_EcuAdr 3;
BA_ "GenSigStartValue" SG_ 1500 DiagFaultStat_RCIOM_EcuAdr 255;
BA_ "NeedsUpdateBit" SG_ 1500 DiagFaultStat_RCIOM_EcuAdr 1;
BA_ "Platform_VMCU1_Sig" SG_ 1500 DiagFaultStat_RCIOM_EcuAdr 1;
BA_ "Platform_Vivis2_Sig" SG_ 1500 DiagFaultStat_RCIOM_EcuAdr 1;
BA_ "GenSigSendType" SG_ 1497 DiagFaultStat_GFHCM2_DtcIdA 1;
BA_ "NeedsUpdateBit" SG_ 1497 DiagFaultStat_GFHCM2_DtcIdA 1;
BA_ "Platform_Vivis2_Sig" SG_ 1497 DiagFaultStat_GFHCM2_DtcIdA 1;
BA_ "GenSigSendType" SG_ 1497 DiagFaultStat_GFHCM2_FailTB 1;
BA_ "NeedsUpdateBit" SG_ 1497 DiagFaultStat_GFHCM2_FailTB 1;
BA_ "Platform_Vivis2_Sig" SG_ 1497 DiagFaultStat_GFHCM2_FailTB 1;
BA_ "GenSigSendType" SG_ 1497 DiagFaultStat_GFHCM2_DtcIdB 1;
BA_ "NeedsUpdateBit" SG_ 1497 DiagFaultStat_GFHCM2_DtcIdB 1;
BA_ "Platform_Vivis2_Sig" SG_ 1497 DiagFaultStat_GFHCM2_DtcIdB 1;
BA_ "GenSigSendType" SG_ 1497 DiagFaultStat_GFHCM2_EcuAdr 1;
BA_ "GenSigStartValue" SG_ 1497 DiagFaultStat_GFHCM2_EcuAdr 255;
BA_ "NeedsUpdateBit" SG_ 1497 DiagFaultStat_GFHCM2_EcuAdr 1;
BA_ "Platform_Vivis2_Sig" SG_ 1497 DiagFaultStat_GFHCM2_EcuAdr 1;
BA_ "GenSigSendType" SG_ 1497 DiagFaultStat_GFHCM2_FailTA 1;
BA_ "NeedsUpdateBit" SG_ 1497 DiagFaultStat_GFHCM2_FailTA 1;
BA_ "Platform_Vivis2_Sig" SG_ 1497 DiagFaultStat_GFHCM2_FailTA 1;
BA_ "GenSigSendType" SG_ 1497 DiagFaultStat_GFHCM2_sg_UB 7;
BA_ "Platform_Vivis2_Sig" SG_ 1497 DiagFaultStat_GFHCM2_sg_UB 1;
BA_ "GenSigSendType" SG_ 1496 DiagFaultStat_GFHCM1_EcuAdr 1;
BA_ "GenSigStartValue" SG_ 1496 DiagFaultStat_GFHCM1_EcuAdr 255;
BA_ "NeedsUpdateBit" SG_ 1496 DiagFaultStat_GFHCM1_EcuAdr 1;
BA_ "Platform_Vivis2_Sig" SG_ 1496 DiagFaultStat_GFHCM1_EcuAdr 1;
BA_ "GenSigSendType" SG_ 1496 DiagFaultStat_GFHCM1_DtcIdB 1;
BA_ "NeedsUpdateBit" SG_ 1496 DiagFaultStat_GFHCM1_DtcIdB 1;
BA_ "Platform_Vivis2_Sig" SG_ 1496 DiagFaultStat_GFHCM1_DtcIdB 1;
BA_ "GenSigSendType" SG_ 1496 DiagFaultStat_GFHCM1_FailTB 1;
BA_ "NeedsUpdateBit" SG_ 1496 DiagFaultStat_GFHCM1_FailTB 1;
BA_ "Platform_Vivis2_Sig" SG_ 1496 DiagFaultStat_GFHCM1_FailTB 1;
BA_ "GenSigSendType" SG_ 1496 DiagFaultStat_GFHCM1_sg_UB 7;
BA_ "Platform_Vivis2_Sig" SG_ 1496 DiagFaultStat_GFHCM1_sg_UB 1;
BA_ "GenSigSendType" SG_ 1496 DiagFaultStat_GFHCM1_FailTA 1;
BA_ "NeedsUpdateBit" SG_ 1496 DiagFaultStat_GFHCM1_FailTA 1;
BA_ "Platform_Vivis2_Sig" SG_ 1496 DiagFaultStat_GFHCM1_FailTA 1;
BA_ "GenSigSendType" SG_ 1496 DiagFaultStat_GFHCM1_DtcIdA 1;
BA_ "NeedsUpdateBit" SG_ 1496 DiagFaultStat_GFHCM1_DtcIdA 1;
BA_ "Platform_Vivis2_Sig" SG_ 1496 DiagFaultStat_GFHCM1_DtcIdA 1;
BA_ "GenSigSendType" SG_ 1499 DiagFaultStat_FCIOM_DtcIdA 3;
BA_ "NeedsUpdateBit" SG_ 1499 DiagFaultStat_FCIOM_DtcIdA 1;
BA_ "Platform_VMCU1_Sig" SG_ 1499 DiagFaultStat_FCIOM_DtcIdA 1;
BA_ "Platform_Vivis2_Sig" SG_ 1499 DiagFaultStat_FCIOM_DtcIdA 1;
BA_ "GenSigSendType" SG_ 1499 DiagFaultStat_FCIOM_sg_UB 7;
BA_ "Platform_VMCU1_Sig" SG_ 1499 DiagFaultStat_FCIOM_sg_UB 1;
BA_ "Platform_Vivis2_Sig" SG_ 1499 DiagFaultStat_FCIOM_sg_UB 1;
BA_ "GenSigSendType" SG_ 1499 DiagFaultStat_FCIOM_FailTA 3;
BA_ "NeedsUpdateBit" SG_ 1499 DiagFaultStat_FCIOM_FailTA 1;
BA_ "Platform_VMCU1_Sig" SG_ 1499 DiagFaultStat_FCIOM_FailTA 1;
BA_ "Platform_Vivis2_Sig" SG_ 1499 DiagFaultStat_FCIOM_FailTA 1;
BA_ "GenSigSendType" SG_ 1499 DiagFaultStat_FCIOM_FailTB 3;
BA_ "NeedsUpdateBit" SG_ 1499 DiagFaultStat_FCIOM_FailTB 1;
BA_ "Platform_VMCU1_Sig" SG_ 1499 DiagFaultStat_FCIOM_FailTB 1;
BA_ "Platform_Vivis2_Sig" SG_ 1499 DiagFaultStat_FCIOM_FailTB 1;
BA_ "GenSigSendType" SG_ 1499 DiagFaultStat_FCIOM_DtcIdB 3;
BA_ "NeedsUpdateBit" SG_ 1499 DiagFaultStat_FCIOM_DtcIdB 1;
BA_ "Platform_VMCU1_Sig" SG_ 1499 DiagFaultStat_FCIOM_DtcIdB 1;
BA_ "Platform_Vivis2_Sig" SG_ 1499 DiagFaultStat_FCIOM_DtcIdB 1;
BA_ "GenSigSendType" SG_ 1499 DiagFaultStat_FCIOM_EcuAdr 3;
BA_ "GenSigStartValue" SG_ 1499 DiagFaultStat_FCIOM_EcuAdr 255;
BA_ "NeedsUpdateBit" SG_ 1499 DiagFaultStat_FCIOM_EcuAdr 1;
BA_ "Platform_VMCU1_Sig" SG_ 1499 DiagFaultStat_FCIOM_EcuAdr 1;
BA_ "Platform_Vivis2_Sig" SG_ 1499 DiagFaultStat_FCIOM_EcuAdr 1;
BA_ "GenSigSendType" SG_ 1490 DiagFaultStat_CCIOM_EcuAdr 3;
BA_ "GenSigStartValue" SG_ 1490 DiagFaultStat_CCIOM_EcuAdr 255;
BA_ "NeedsUpdateBit" SG_ 1490 DiagFaultStat_CCIOM_EcuAdr 1;
BA_ "Platform_VMCU1_Sig" SG_ 1490 DiagFaultStat_CCIOM_EcuAdr 1;
BA_ "Platform_Vivis2_Sig" SG_ 1490 DiagFaultStat_CCIOM_EcuAdr 1;
BA_ "GenSigSendType" SG_ 1490 DiagFaultStat_CCIOM_FailTA 3;
BA_ "NeedsUpdateBit" SG_ 1490 DiagFaultStat_CCIOM_FailTA 1;
BA_ "Platform_VMCU1_Sig" SG_ 1490 DiagFaultStat_CCIOM_FailTA 1;
BA_ "Platform_Vivis2_Sig" SG_ 1490 DiagFaultStat_CCIOM_FailTA 1;
BA_ "GenSigSendType" SG_ 1490 DiagFaultStat_CCIOM_sg_UB 7;
BA_ "Platform_VMCU1_Sig" SG_ 1490 DiagFaultStat_CCIOM_sg_UB 1;
BA_ "Platform_Vivis2_Sig" SG_ 1490 DiagFaultStat_CCIOM_sg_UB 1;
BA_ "GenSigSendType" SG_ 1490 DiagFaultStat_CCIOM_DtcIdB 3;
BA_ "NeedsUpdateBit" SG_ 1490 DiagFaultStat_CCIOM_DtcIdB 1;
BA_ "Platform_VMCU1_Sig" SG_ 1490 DiagFaultStat_CCIOM_DtcIdB 1;
BA_ "Platform_Vivis2_Sig" SG_ 1490 DiagFaultStat_CCIOM_DtcIdB 1;
BA_ "GenSigSendType" SG_ 1490 DiagFaultStat_CCIOM_FailTB 3;
BA_ "NeedsUpdateBit" SG_ 1490 DiagFaultStat_CCIOM_FailTB 1;
BA_ "Platform_VMCU1_Sig" SG_ 1490 DiagFaultStat_CCIOM_FailTB 1;
BA_ "Platform_Vivis2_Sig" SG_ 1490 DiagFaultStat_CCIOM_FailTB 1;
BA_ "GenSigSendType" SG_ 1490 DiagFaultStat_CCIOM_DtcIdA 3;
BA_ "NeedsUpdateBit" SG_ 1490 DiagFaultStat_CCIOM_DtcIdA 1;
BA_ "Platform_VMCU1_Sig" SG_ 1490 DiagFaultStat_CCIOM_DtcIdA 1;
BA_ "Platform_Vivis2_Sig" SG_ 1490 DiagFaultStat_CCIOM_DtcIdA 1;
BA_ "GenSigSendType" SG_ 1952 Debug_9_RCIOM 1;
BA_ "GenSigMaxLatency" SG_ 1952 Debug_9_RCIOM 59;
BA_ "GenSigSendType" SG_ 1951 Debug_9_CCIOM 1;
BA_ "GenSigMaxLatency" SG_ 1951 Debug_9_CCIOM 59;
BA_ "GenSigSendType" SG_ 1947 Debug_8_RCIOM 1;
BA_ "GenSigMaxLatency" SG_ 1947 Debug_8_RCIOM 59;
BA_ "GenSigSendType" SG_ 1946 Debug_8_CCIOM 1;
BA_ "GenSigMaxLatency" SG_ 1946 Debug_8_CCIOM 59;
BA_ "GenSigSendType" SG_ 1942 Debug_7_RCIOM 1;
BA_ "GenSigMaxLatency" SG_ 1942 Debug_7_RCIOM 59;
BA_ "GenSigSendType" SG_ 1941 Debug_7_CCIOM 1;
BA_ "GenSigMaxLatency" SG_ 1941 Debug_7_CCIOM 59;
BA_ "GenSigSendType" SG_ 1935 Debug_6_RCIOM 1;
BA_ "GenSigMaxLatency" SG_ 1935 Debug_6_RCIOM 58;
BA_ "GenSigSendType" SG_ 1933 Debug_6_CCIOM 1;
BA_ "GenSigMaxLatency" SG_ 1933 Debug_6_CCIOM 58;
BA_ "GenSigSendType" SG_ 1927 Debug_5_RCIOM 1;
BA_ "GenSigMaxLatency" SG_ 1927 Debug_5_RCIOM 58;
BA_ "GenSigSendType" SG_ 1925 Debug_5_CCIOM 1;
BA_ "GenSigMaxLatency" SG_ 1925 Debug_5_CCIOM 58;
BA_ "GenSigSendType" SG_ 1919 Debug_4_RCIOM 1;
BA_ "GenSigMaxLatency" SG_ 1919 Debug_4_RCIOM 58;
BA_ "GenSigSendType" SG_ 1917 Debug_4_CCIOM 1;
BA_ "GenSigMaxLatency" SG_ 1917 Debug_4_CCIOM 58;
BA_ "GenSigSendType" SG_ 1911 Debug_3_RCIOM 1;
BA_ "GenSigMaxLatency" SG_ 1911 Debug_3_RCIOM 58;
BA_ "GenSigSendType" SG_ 1909 Debug_3_CCIOM 1;
BA_ "GenSigMaxLatency" SG_ 1909 Debug_3_CCIOM 58;
BA_ "GenSigSendType" SG_ 1903 Debug_2_RCIOM 1;
BA_ "GenSigMaxLatency" SG_ 1903 Debug_2_RCIOM 58;
BA_ "GenSigSendType" SG_ 1901 Debug_2_CCIOM 1;
BA_ "GenSigMaxLatency" SG_ 1901 Debug_2_CCIOM 58;
BA_ "GenSigSendType" SG_ 1981 Debug_20_RCIOM_Platform 1;
BA_ "GenSigSendType" SG_ 1895 Debug_1_RCIOM 1;
BA_ "GenSigSendType" SG_ 1893 Debug_1_CCIOM 1;
BA_ "GenSigSendType" SG_ 1980 Debug_19_RCIOMLights 1;
BA_ "GenSigSendType" SG_ 1979 Debug_18_RCIOMLights 1;
BA_ "GenSigSendType" SG_ 1978 Debug_17_RCIOMLights 1;
BA_ "GenSigSendType" SG_ 1977 Debug_16_RCIOMLights 1;
BA_ "GenSigSendType" SG_ 1976 Debug_15_RCIOMLights 1;
BA_ "GenSigSendType" SG_ 1969 Debug_1_FCIOM_Platform 1;
BA_ "GenSigSendType" SG_ 1968 Debug_15_CCIOM_Platform 1;
BA_ "GenSigSendType" SG_ 1975 Debug_14_RCIOMLights 1;
BA_ "GenSigSendType" SG_ 1967 Debug14_CCIOMLights 1;
BA_ "GenSigSendType" SG_ 1974 Debug_13_RCIOMLights 1;
BA_ "GenSigSendType" SG_ 1965 Debug13_CCIOMLights 1;
BA_ "GenSigSendType" SG_ 1973 Debug_12_RCIOMLights 1;
BA_ "GenSigSendType" SG_ 1963 Debug_12_CCIOM 1;
BA_ "GenSigMaxLatency" SG_ 1963 Debug_12_CCIOM 59;
BA_ "GenSigSendType" SG_ 1961 Debug_11_RCIOM 1;
BA_ "GenSigMaxLatency" SG_ 1961 Debug_11_RCIOM 59;
BA_ "GenSigSendType" SG_ 1960 Debug_11_CCIOM 1;
BA_ "GenSigMaxLatency" SG_ 1960 Debug_11_CCIOM 59;
BA_ "GenSigSendType" SG_ 1957 Debug_10_RCIOM 1;
BA_ "GenSigMaxLatency" SG_ 1957 Debug_10_RCIOM 59;
BA_ "GenSigSendType" SG_ 1956 Debug_10_CCIOM 1;
BA_ "GenSigMaxLatency" SG_ 1956 Debug_10_CCIOM 59;
BA_ "GenSigCycleTime" SG_ 1253 SensorCleaningFluidLevel_ISig_4 100;
BA_ "GenSigCycleTimeActive" SG_ 1253 SensorCleaningFluidLevel_ISig_4 100;
BA_ "GenSigStartValue" SG_ 1253 SensorCleaningFluidLevel_ISig_4 255;
BA_ "GenSigCycleTime" SG_ 1253 SensorCleaningPumpPressure_ISig_ 100;
BA_ "GenSigCycleTimeActive" SG_ 1253 SensorCleaningPumpPressure_ISig_ 100;
BA_ "GenSigStartValue" SG_ 1253 SensorCleaningPumpPressure_ISig_ 4294967295;
BA_ "SystemSignalLongSymbol" SG_ 1253 SensorCleaningPumpPressure_ISig_ "SensorCleaningPumpPressure_ISig_4";
BA_ "GenSigCycleTime" SG_ 1253 SensorCleaningFluidLevelStatus_I 100;
BA_ "GenSigCycleTimeActive" SG_ 1253 SensorCleaningFluidLevelStatus_I 100;
BA_ "GenSigStartValue" SG_ 1253 SensorCleaningFluidLevelStatus_I 7;
BA_ "SystemSignalLongSymbol" SG_ 1253 SensorCleaningFluidLevelStatus_I "SensorCleaningFluidLevelStatus_ISig_4";
BA_ "GenSigCycleTime" SG_ 1372 OpLevelItem11 100;
BA_ "GenSigCycleTimeActive" SG_ 1372 OpLevelItem11 100;
BA_ "GenSigStartValue" SG_ 1372 OpLevelItem11 255;
BA_ "GenSigMaxLatency" SG_ 1372 OpLevelItem11 500;
BA_ "Platform_Vivis2_Sig" SG_ 1372 OpLevelItem11 1;
BA_ "GenSigCycleTime" SG_ 1372 OpLevelItem14 100;
BA_ "GenSigCycleTimeActive" SG_ 1372 OpLevelItem14 100;
BA_ "GenSigStartValue" SG_ 1372 OpLevelItem14 255;
BA_ "GenSigMaxLatency" SG_ 1372 OpLevelItem14 500;
BA_ "Platform_Vivis2_Sig" SG_ 1372 OpLevelItem14 1;
BA_ "GenSigCycleTime" SG_ 1372 OpLevelItem12 100;
BA_ "GenSigCycleTimeActive" SG_ 1372 OpLevelItem12 100;
BA_ "GenSigStartValue" SG_ 1372 OpLevelItem12 255;
BA_ "GenSigMaxLatency" SG_ 1372 OpLevelItem12 500;
BA_ "Platform_Vivis2_Sig" SG_ 1372 OpLevelItem12 1;
BA_ "GenSigCycleTime" SG_ 1372 OpLevelItem15 100;
BA_ "GenSigCycleTimeActive" SG_ 1372 OpLevelItem15 100;
BA_ "GenSigStartValue" SG_ 1372 OpLevelItem15 255;
BA_ "GenSigMaxLatency" SG_ 1372 OpLevelItem15 500;
BA_ "Platform_Vivis2_Sig" SG_ 1372 OpLevelItem15 1;
BA_ "GenSigCycleTime" SG_ 1372 OpLevelItem13 100;
BA_ "GenSigCycleTimeActive" SG_ 1372 OpLevelItem13 100;
BA_ "GenSigStartValue" SG_ 1372 OpLevelItem13 255;
BA_ "GenSigMaxLatency" SG_ 1372 OpLevelItem13 500;
BA_ "Platform_Vivis2_Sig" SG_ 1372 OpLevelItem13 1;
BA_ "GenSigCycleTime" SG_ 1371 OpLevelItem1 100;
BA_ "GenSigCycleTimeActive" SG_ 1371 OpLevelItem1 100;
BA_ "GenSigStartValue" SG_ 1371 OpLevelItem1 255;
BA_ "GenSigMaxLatency" SG_ 1371 OpLevelItem1 500;
BA_ "Platform_Vivis2_Sig" SG_ 1371 OpLevelItem1 1;
BA_ "GenSigCycleTime" SG_ 1371 OpLevelItem8 100;
BA_ "GenSigCycleTimeActive" SG_ 1371 OpLevelItem8 100;
BA_ "GenSigStartValue" SG_ 1371 OpLevelItem8 255;
BA_ "GenSigMaxLatency" SG_ 1371 OpLevelItem8 500;
BA_ "Platform_Vivis2_Sig" SG_ 1371 OpLevelItem8 1;
BA_ "GenSigCycleTime" SG_ 1371 OpLevelItem5 100;
BA_ "GenSigCycleTimeActive" SG_ 1371 OpLevelItem5 100;
BA_ "GenSigStartValue" SG_ 1371 OpLevelItem5 255;
BA_ "GenSigMaxLatency" SG_ 1371 OpLevelItem5 500;
BA_ "Platform_Vivis2_Sig" SG_ 1371 OpLevelItem5 1;
BA_ "GenSigCycleTime" SG_ 1371 OpLevelItem6 100;
BA_ "GenSigCycleTimeActive" SG_ 1371 OpLevelItem6 100;
BA_ "GenSigStartValue" SG_ 1371 OpLevelItem6 255;
BA_ "GenSigMaxLatency" SG_ 1371 OpLevelItem6 500;
BA_ "Platform_Vivis2_Sig" SG_ 1371 OpLevelItem6 1;
BA_ "GenSigCycleTime" SG_ 1371 OpLevelItem10 100;
BA_ "GenSigCycleTimeActive" SG_ 1371 OpLevelItem10 100;
BA_ "GenSigStartValue" SG_ 1371 OpLevelItem10 255;
BA_ "GenSigMaxLatency" SG_ 1371 OpLevelItem10 500;
BA_ "Platform_Vivis2_Sig" SG_ 1371 OpLevelItem10 1;
BA_ "GenSigCycleTime" SG_ 1371 OpLevelItem7 100;
BA_ "GenSigCycleTimeActive" SG_ 1371 OpLevelItem7 100;
BA_ "GenSigStartValue" SG_ 1371 OpLevelItem7 255;
BA_ "GenSigMaxLatency" SG_ 1371 OpLevelItem7 500;
BA_ "Platform_Vivis2_Sig" SG_ 1371 OpLevelItem7 1;
BA_ "GenSigCycleTime" SG_ 1371 OpLevelItem9 100;
BA_ "GenSigCycleTimeActive" SG_ 1371 OpLevelItem9 100;
BA_ "GenSigStartValue" SG_ 1371 OpLevelItem9 255;
BA_ "GenSigMaxLatency" SG_ 1371 OpLevelItem9 500;
BA_ "Platform_Vivis2_Sig" SG_ 1371 OpLevelItem9 1;
BA_ "GenSigCycleTime" SG_ 1371 OpLevelItem4 100;
BA_ "GenSigCycleTimeActive" SG_ 1371 OpLevelItem4 100;
BA_ "GenSigStartValue" SG_ 1371 OpLevelItem4 255;
BA_ "GenSigMaxLatency" SG_ 1371 OpLevelItem4 500;
BA_ "Platform_Vivis2_Sig" SG_ 1371 OpLevelItem4 1;
BA_ "GenSigCycleTime" SG_ 1362 Cur_EnergySetting_ISig_4 100;
BA_ "GenSigCycleTimeActive" SG_ 1362 Cur_EnergySetting_ISig_4 100;
BA_ "GenSigStartValue" SG_ 1362 Cur_EnergySetting_ISig_4 7;
BA_ "Platform_Vivis2_Sig" SG_ 1362 Cur_EnergySetting_ISig_4 1;
BA_ "GenSigCycleTime" SG_ 1362 Cur_LG5CutoffValue_ISig_4 100;
BA_ "GenSigCycleTimeActive" SG_ 1362 Cur_LG5CutoffValue_ISig_4 100;
BA_ "GenSigStartValue" SG_ 1362 Cur_LG5CutoffValue_ISig_4 255;
BA_ "Platform_Vivis2_Sig" SG_ 1362 Cur_LG5CutoffValue_ISig_4 1;
BA_ "GenSigCycleTime" SG_ 1362 Cur_LG6CutoffValue_ISig_4 100;
BA_ "GenSigCycleTimeActive" SG_ 1362 Cur_LG6CutoffValue_ISig_4 100;
BA_ "GenSigStartValue" SG_ 1362 Cur_LG6CutoffValue_ISig_4 255;
BA_ "Platform_Vivis2_Sig" SG_ 1362 Cur_LG6CutoffValue_ISig_4 1;
BA_ "GenSigCycleTime" SG_ 1362 Cur_LG2CutoffValue_ISig_4 100;
BA_ "GenSigCycleTimeActive" SG_ 1362 Cur_LG2CutoffValue_ISig_4 100;
BA_ "GenSigStartValue" SG_ 1362 Cur_LG2CutoffValue_ISig_4 255;
BA_ "Platform_Vivis2_Sig" SG_ 1362 Cur_LG2CutoffValue_ISig_4 1;
BA_ "GenSigCycleTime" SG_ 1362 Cur_LG1CutoffValue_ISig_4 100;
BA_ "GenSigCycleTimeActive" SG_ 1362 Cur_LG1CutoffValue_ISig_4 100;
BA_ "GenSigStartValue" SG_ 1362 Cur_LG1CutoffValue_ISig_4 255;
BA_ "Platform_Vivis2_Sig" SG_ 1362 Cur_LG1CutoffValue_ISig_4 1;
BA_ "GenSigCycleTime" SG_ 1362 Cur_LG4CutoffValue_ISig_4 100;
BA_ "GenSigCycleTimeActive" SG_ 1362 Cur_LG4CutoffValue_ISig_4 100;
BA_ "GenSigStartValue" SG_ 1362 Cur_LG4CutoffValue_ISig_4 255;
BA_ "Platform_Vivis2_Sig" SG_ 1362 Cur_LG4CutoffValue_ISig_4 1;
BA_ "GenSigCycleTime" SG_ 1362 Cur_LG3CutoffValue_ISig_4 100;
BA_ "GenSigCycleTimeActive" SG_ 1362 Cur_LG3CutoffValue_ISig_4 100;
BA_ "GenSigStartValue" SG_ 1362 Cur_LG3CutoffValue_ISig_4 255;
BA_ "Platform_Vivis2_Sig" SG_ 1362 Cur_LG3CutoffValue_ISig_4 1;
BA_ "GenSigCycleTime" SG_ 1444 CrankDiagInfo4_1 100;
BA_ "GenSigCycleTimeActive" SG_ 1444 CrankDiagInfo4_1 100;
BA_ "GenSigStartValue" SG_ 1444 CrankDiagInfo4_1 2047;
BA_ "GenSigMaxLatency" SG_ 1444 CrankDiagInfo4_1 1010;
BA_ "Platform_Vivis2_Sig" SG_ 1444 CrankDiagInfo4_1 1;
BA_ "GenSigCycleTime" SG_ 1444 CrankDiagInfo3_1 100;
BA_ "GenSigCycleTimeActive" SG_ 1444 CrankDiagInfo3_1 100;
BA_ "GenSigStartValue" SG_ 1444 CrankDiagInfo3_1 65535;
BA_ "GenSigMaxLatency" SG_ 1444 CrankDiagInfo3_1 1010;
BA_ "Platform_Vivis2_Sig" SG_ 1444 CrankDiagInfo3_1 1;
BA_ "GenSigCycleTime" SG_ 1444 BatteryCapacityGrpAck_Pos3 100;
BA_ "GenSigCycleTimeActive" SG_ 1444 BatteryCapacityGrpAck_Pos3 100;
BA_ "GenSigStartValue" SG_ 1444 BatteryCapacityGrpAck_Pos3 3;
BA_ "Platform_Vivis2_Sig" SG_ 1444 BatteryCapacityGrpAck_Pos3 1;
BA_ "GenSigCycleTime" SG_ 1444 CrankDiagInfo2_1 100;
BA_ "GenSigCycleTimeActive" SG_ 1444 CrankDiagInfo2_1 100;
BA_ "GenSigStartValue" SG_ 1444 CrankDiagInfo2_1 2047;
BA_ "GenSigMaxLatency" SG_ 1444 CrankDiagInfo2_1 1010;
BA_ "Platform_Vivis2_Sig" SG_ 1444 CrankDiagInfo2_1 1;
BA_ "GenSigCycleTime" SG_ 1444 BatteryCapacityGrpAck_Pos2 100;
BA_ "GenSigCycleTimeActive" SG_ 1444 BatteryCapacityGrpAck_Pos2 100;
BA_ "GenSigStartValue" SG_ 1444 BatteryCapacityGrpAck_Pos2 3;
BA_ "Platform_Vivis2_Sig" SG_ 1444 BatteryCapacityGrpAck_Pos2 1;
BA_ "GenSigCycleTime" SG_ 1444 BatteryCapacityGrpAck_Pos1 100;
BA_ "GenSigCycleTimeActive" SG_ 1444 BatteryCapacityGrpAck_Pos1 100;
BA_ "GenSigStartValue" SG_ 1444 BatteryCapacityGrpAck_Pos1 3;
BA_ "Platform_Vivis2_Sig" SG_ 1444 BatteryCapacityGrpAck_Pos1 1;
BA_ "GenSigCycleTime" SG_ 1444 CrankDiagInfo1_1 100;
BA_ "GenSigCycleTimeActive" SG_ 1444 CrankDiagInfo1_1 100;
BA_ "GenSigStartValue" SG_ 1444 CrankDiagInfo1_1 65535;
BA_ "GenSigMaxLatency" SG_ 1444 CrankDiagInfo1_1 1010;
BA_ "Platform_Vivis2_Sig" SG_ 1444 CrankDiagInfo1_1 1;
BA_ "GenSigCycleTime" SG_ 1471 BatterySOHCapa1_1 100;
BA_ "GenSigCycleTimeActive" SG_ 1471 BatterySOHCapa1_1 100;
BA_ "GenSigStartValue" SG_ 1471 BatterySOHCapa1_1 255;
BA_ "GenSigMaxLatency" SG_ 1471 BatterySOHCapa1_1 1010;
BA_ "Platform_Vivis2_Sig" SG_ 1471 BatterySOHCapa1_1 1;
BA_ "GenSigCycleTime" SG_ 1471 BatterySOCTrustLevel_stat1_1 100;
BA_ "GenSigCycleTimeActive" SG_ 1471 BatterySOCTrustLevel_stat1_1 100;
BA_ "GenSigStartValue" SG_ 1471 BatterySOCTrustLevel_stat1_1 15;
BA_ "GenSigMaxLatency" SG_ 1471 BatterySOCTrustLevel_stat1_1 1010;
BA_ "Platform_Vivis2_Sig" SG_ 1471 BatterySOCTrustLevel_stat1_1 1;
BA_ "GenSigCycleTime" SG_ 1471 EndOfDischargeStatus1_1 100;
BA_ "GenSigCycleTimeActive" SG_ 1471 EndOfDischargeStatus1_1 100;
BA_ "GenSigMaxLatency" SG_ 1471 EndOfDischargeStatus1_1 1010;
BA_ "Platform_Vivis2_Sig" SG_ 1471 EndOfDischargeStatus1_1 1;
BA_ "GenSigCycleTime" SG_ 1471 DeepDischargestatus_1 100;
BA_ "GenSigCycleTimeActive" SG_ 1471 DeepDischargestatus_1 100;
BA_ "GenSigMaxLatency" SG_ 1471 DeepDischargestatus_1 1010;
BA_ "Platform_Vivis2_Sig" SG_ 1471 DeepDischargestatus_1 1;
BA_ "GenSigCycleTime" SG_ 1471 BatteryEndOfCharge_ISig_4 100;
BA_ "GenSigCycleTimeActive" SG_ 1471 BatteryEndOfCharge_ISig_4 100;
BA_ "GenSigStartValue" SG_ 1471 BatteryEndOfCharge_ISig_4 3;
BA_ "Platform_Vivis2_Sig" SG_ 1471 BatteryEndOfCharge_ISig_4 1;
BA_ "GenSigCycleTime" SG_ 1471 BatteryExchangeDetect_1 100;
BA_ "GenSigCycleTimeActive" SG_ 1471 BatteryExchangeDetect_1 100;
BA_ "GenSigStartValue" SG_ 1471 BatteryExchangeDetect_1 7;
BA_ "GenSigMaxLatency" SG_ 1471 BatteryExchangeDetect_1 1010;
BA_ "Platform_Vivis2_Sig" SG_ 1471 BatteryExchangeDetect_1 1;
BA_ "GenSigCycleTime" SG_ 1471 BatterySOHTrustLevel_stat1_1 100;
BA_ "GenSigCycleTimeActive" SG_ 1471 BatterySOHTrustLevel_stat1_1 100;
BA_ "GenSigStartValue" SG_ 1471 BatterySOHTrustLevel_stat1_1 15;
BA_ "GenSigMaxLatency" SG_ 1471 BatterySOHTrustLevel_stat1_1 1010;
BA_ "Platform_Vivis2_Sig" SG_ 1471 BatterySOHTrustLevel_stat1_1 1;
BA_ "GenSigCycleTime" SG_ 1471 Endofchargestatus1_1 100;
BA_ "GenSigCycleTimeActive" SG_ 1471 Endofchargestatus1_1 100;
BA_ "GenSigMaxLatency" SG_ 1471 Endofchargestatus1_1 1010;
BA_ "Platform_Vivis2_Sig" SG_ 1471 Endofchargestatus1_1 1;
BA_ "GenSigCycleTime" SG_ 1471 BatterySOHPowerTrustLevel1_1 100;
BA_ "GenSigCycleTimeActive" SG_ 1471 BatterySOHPowerTrustLevel1_1 100;
BA_ "GenSigStartValue" SG_ 1471 BatterySOHPowerTrustLevel1_1 15;
BA_ "GenSigMaxLatency" SG_ 1471 BatterySOHPowerTrustLevel1_1 1010;
BA_ "Platform_Vivis2_Sig" SG_ 1471 BatterySOHPowerTrustLevel1_1 1;
BA_ "GenSigCycleTime" SG_ 1471 BatteryTempCo_1 100;
BA_ "GenSigCycleTimeActive" SG_ 1471 BatteryTempCo_1 100;
BA_ "GenSigStartValue" SG_ 1471 BatteryTempCo_1 255;
BA_ "GenSigMaxLatency" SG_ 1471 BatteryTempCo_1 1010;
BA_ "Platform_Vivis2_Sig" SG_ 1471 BatteryTempCo_1 1;
BA_ "GenSigCycleTime" SG_ 1471 BatterySOHPower1_1 100;
BA_ "GenSigCycleTimeActive" SG_ 1471 BatterySOHPower1_1 100;
BA_ "GenSigStartValue" SG_ 1471 BatterySOHPower1_1 255;
BA_ "GenSigMaxLatency" SG_ 1471 BatterySOHPower1_1 1010;
BA_ "Platform_Vivis2_Sig" SG_ 1471 BatterySOHPower1_1 1;
BA_ "GenSigCycleTime" SG_ 1471 BatteryReconnectionDetect_1 100;
BA_ "GenSigCycleTimeActive" SG_ 1471 BatteryReconnectionDetect_1 100;
BA_ "GenSigMaxLatency" SG_ 1471 BatteryReconnectionDetect_1 1010;
BA_ "Platform_Vivis2_Sig" SG_ 1471 BatteryReconnectionDetect_1 1;
BA_ "GenSigCycleTime" SG_ 1471 BatterySoCcrankLimit1_1 100;
BA_ "GenSigCycleTimeActive" SG_ 1471 BatterySoCcrankLimit1_1 100;
BA_ "GenSigStartValue" SG_ 1471 BatterySoCcrankLimit1_1 255;
BA_ "GenSigMaxLatency" SG_ 1471 BatterySoCcrankLimit1_1 1010;
BA_ "Platform_Vivis2_Sig" SG_ 1471 BatterySoCcrankLimit1_1 1;
BA_ "GenSigCycleTime" SG_ 1469 WhCounterCharge_1 100;
BA_ "GenSigCycleTimeActive" SG_ 1469 WhCounterCharge_1 100;
BA_ "GenSigStartValue" SG_ 1469 WhCounterCharge_1 65535;
BA_ "GenSigMaxLatency" SG_ 1469 WhCounterCharge_1 1011;
BA_ "Platform_Vivis2_Sig" SG_ 1469 WhCounterCharge_1 1;
BA_ "GenSigCycleTime" SG_ 1469 HighCurrentIR1_1 100;
BA_ "GenSigCycleTimeActive" SG_ 1469 HighCurrentIR1_1 100;
BA_ "GenSigStartValue" SG_ 1469 HighCurrentIR1_1 1023;
BA_ "GenSigMaxLatency" SG_ 1469 HighCurrentIR1_1 1011;
BA_ "Platform_Vivis2_Sig" SG_ 1469 HighCurrentIR1_1 1;
BA_ "GenSigCycleTime" SG_ 1469 WhCounterDischarge_1 100;
BA_ "GenSigCycleTimeActive" SG_ 1469 WhCounterDischarge_1 100;
BA_ "GenSigStartValue" SG_ 1469 WhCounterDischarge_1 65535;
BA_ "GenSigMaxLatency" SG_ 1469 WhCounterDischarge_1 1011;
BA_ "Platform_Vivis2_Sig" SG_ 1469 WhCounterDischarge_1 1;
BA_ "GenSigCycleTime" SG_ 1467 WhCounterCharge_1A 100;
BA_ "GenSigCycleTimeActive" SG_ 1467 WhCounterCharge_1A 100;
BA_ "GenSigStartValue" SG_ 1467 WhCounterCharge_1A 65535;
BA_ "GenSigMaxLatency" SG_ 1467 WhCounterCharge_1A 1012;
BA_ "Platform_Vivis2_Sig" SG_ 1467 WhCounterCharge_1A 1;
BA_ "GenSigCycleTime" SG_ 1467 HighCurrentIR1_1A 100;
BA_ "GenSigCycleTimeActive" SG_ 1467 HighCurrentIR1_1A 100;
BA_ "GenSigStartValue" SG_ 1467 HighCurrentIR1_1A 1023;
BA_ "GenSigMaxLatency" SG_ 1467 HighCurrentIR1_1A 1012;
BA_ "Platform_Vivis2_Sig" SG_ 1467 HighCurrentIR1_1A 1;
BA_ "GenSigCycleTime" SG_ 1467 WhCounterDischarge_1A 100;
BA_ "GenSigCycleTimeActive" SG_ 1467 WhCounterDischarge_1A 100;
BA_ "GenSigStartValue" SG_ 1467 WhCounterDischarge_1A 65535;
BA_ "GenSigMaxLatency" SG_ 1467 WhCounterDischarge_1A 1012;
BA_ "Platform_Vivis2_Sig" SG_ 1467 WhCounterDischarge_1A 1;
BA_ "GenSigCycleTime" SG_ 1465 HighCurrentIR1_1B 100;
BA_ "GenSigCycleTimeActive" SG_ 1465 HighCurrentIR1_1B 100;
BA_ "GenSigStartValue" SG_ 1465 HighCurrentIR1_1B 1023;
BA_ "GenSigMaxLatency" SG_ 1465 HighCurrentIR1_1B 1013;
BA_ "Platform_Vivis2_Sig" SG_ 1465 HighCurrentIR1_1B 1;
BA_ "GenSigCycleTime" SG_ 1465 WhCounterCharge_1B 100;
BA_ "GenSigCycleTimeActive" SG_ 1465 WhCounterCharge_1B 100;
BA_ "GenSigStartValue" SG_ 1465 WhCounterCharge_1B 65535;
BA_ "GenSigMaxLatency" SG_ 1465 WhCounterCharge_1B 1013;
BA_ "Platform_Vivis2_Sig" SG_ 1465 WhCounterCharge_1B 1;
BA_ "GenSigCycleTime" SG_ 1465 WhCounterDischarge_1B 100;
BA_ "GenSigCycleTimeActive" SG_ 1465 WhCounterDischarge_1B 100;
BA_ "GenSigStartValue" SG_ 1465 WhCounterDischarge_1B 65535;
BA_ "GenSigMaxLatency" SG_ 1465 WhCounterDischarge_1B 1013;
BA_ "Platform_Vivis2_Sig" SG_ 1465 WhCounterDischarge_1B 1;
BA_ "GenSigCycleTime" SG_ 1463 WhCounterDischarge_2A 100;
BA_ "GenSigCycleTimeActive" SG_ 1463 WhCounterDischarge_2A 100;
BA_ "GenSigStartValue" SG_ 1463 WhCounterDischarge_2A 65535;
BA_ "GenSigMaxLatency" SG_ 1463 WhCounterDischarge_2A 1014;
BA_ "Platform_Vivis2_Sig" SG_ 1463 WhCounterDischarge_2A 1;
BA_ "GenSigCycleTime" SG_ 1463 HighCurrentIR1_2A 100;
BA_ "GenSigCycleTimeActive" SG_ 1463 HighCurrentIR1_2A 100;
BA_ "GenSigStartValue" SG_ 1463 HighCurrentIR1_2A 1023;
BA_ "GenSigMaxLatency" SG_ 1463 HighCurrentIR1_2A 1014;
BA_ "Platform_Vivis2_Sig" SG_ 1463 HighCurrentIR1_2A 1;
BA_ "GenSigCycleTime" SG_ 1463 WhCounterCharge_2A 100;
BA_ "GenSigCycleTimeActive" SG_ 1463 WhCounterCharge_2A 100;
BA_ "GenSigStartValue" SG_ 1463 WhCounterCharge_2A 65535;
BA_ "GenSigMaxLatency" SG_ 1463 WhCounterCharge_2A 1014;
BA_ "Platform_Vivis2_Sig" SG_ 1463 WhCounterCharge_2A 1;
BA_REL_ "GenSigFirstTimeoutTime" BU_SG_REL_ CCIOM SG_ 517 FrontProhibitControlRequest 3000;
BA_REL_ "GenSigTimeoutTime" BU_SG_REL_ CCIOM SG_ 517 FrontProhibitControlRequest 120;
BA_REL_ "GenSigFirstTimeoutTime" BU_SG_REL_ VCM SG_ 517 FrontProhibitControlRequest 3000;
BA_REL_ "GenSigTimeoutTime" BU_SG_REL_ VCM SG_ 517 FrontProhibitControlRequest 120;
BA_REL_ "GenSigFirstTimeoutTime" BU_SG_REL_ VCM SG_ 517 RampLevelStorageAck_ISig_4 3000;
BA_REL_ "GenSigTimeoutTime" BU_SG_REL_ VCM SG_ 517 RampLevelStorageAck_ISig_4 120;
BA_REL_ "GenSigFirstTimeoutTime" BU_SG_REL_ VCM SG_ 517 FrontLimpHomeCmd 3000;
BA_REL_ "GenSigTimeoutTime" BU_SG_REL_ VCM SG_ 517 FrontLimpHomeCmd 120;
BA_REL_ "GenSigFirstTimeoutTime" BU_SG_REL_ CCIOM SG_ 517 FrontLimpHomeCmd 3000;
BA_REL_ "GenSigTimeoutTime" BU_SG_REL_ CCIOM SG_ 517 FrontLimpHomeCmd 120;
BA_REL_ "GenSigFirstTimeoutTime" BU_SG_REL_ VCM SG_ 517 LiftingControlModeRearAxle 3000;
BA_REL_ "GenSigTimeoutTime" BU_SG_REL_ VCM SG_ 517 LiftingControlModeRearAxle 120;
BA_REL_ "GenSigFirstTimeoutTime" BU_SG_REL_ VCM SG_ 517 LoadDistributionChangeACK_ISig_4 3000;
BA_REL_ "GenSigTimeoutTime" BU_SG_REL_ VCM SG_ 517 LoadDistributionChangeACK_ISig_4 120;
BA_REL_ "GenSigFirstTimeoutTime" BU_SG_REL_ VCM SG_ 517 ECSStandbyAllowed_ISig_4 3000;
BA_REL_ "GenSigTimeoutTime" BU_SG_REL_ VCM SG_ 517 ECSStandbyAllowed_ISig_4 120;
BA_REL_ "GenSigFirstTimeoutTime" BU_SG_REL_ VCM SG_ 517 LiftAxle2LiftFuncSelected_ISig_4 3000;
BA_REL_ "GenSigTimeoutTime" BU_SG_REL_ VCM SG_ 517 LiftAxle2LiftFuncSelected_ISig_4 120;
BA_REL_ "GenSigFirstTimeoutTime" BU_SG_REL_ VCM SG_ 517 LiftAxle2UpRequestACK_ISig_4 3000;
BA_REL_ "GenSigTimeoutTime" BU_SG_REL_ VCM SG_ 517 LiftAxle2UpRequestACK_ISig_4 120;
BA_REL_ "GenSigFirstTimeoutTime" BU_SG_REL_ VCM SG_ 517 ProhibitControlStatus_ISig_4 3000;
BA_REL_ "GenSigTimeoutTime" BU_SG_REL_ VCM SG_ 517 ProhibitControlStatus_ISig_4 120;
BA_REL_ "GenSigFirstTimeoutTime" BU_SG_REL_ VCM SG_ 517 RampLevelStatus_ISig_4 3000;
BA_REL_ "GenSigTimeoutTime" BU_SG_REL_ VCM SG_ 517 RampLevelStatus_ISig_4 120;
BA_REL_ "GenSigFirstTimeoutTime" BU_SG_REL_ VCM SG_ 517 StopLevelChangeAck_ISig_4 3000;
BA_REL_ "GenSigTimeoutTime" BU_SG_REL_ VCM SG_ 517 StopLevelChangeAck_ISig_4 120;
BA_REL_ "GenSigFirstTimeoutTime" BU_SG_REL_ VCM SG_ 517 LiftAxle2LowerACK_ISig_4 3000;
BA_REL_ "GenSigTimeoutTime" BU_SG_REL_ VCM SG_ 517 LiftAxle2LowerACK_ISig_4 120;
BA_REL_ "GenSigFirstTimeoutTime" BU_SG_REL_ VCM SG_ 517 RideHeightStorageAck_ISig_4 3000;
BA_REL_ "GenSigTimeoutTime" BU_SG_REL_ VCM SG_ 517 RideHeightStorageAck_ISig_4 120;
BA_REL_ "GenSigFirstTimeoutTime" BU_SG_REL_ VCM SG_ 517 FrontParkBrakeOverrideCommand 3000;
BA_REL_ "GenSigTimeoutTime" BU_SG_REL_ VCM SG_ 517 FrontParkBrakeOverrideCommand 120;
BA_REL_ "GenSigFirstTimeoutTime" BU_SG_REL_ VCM SG_ 517 RideHeightOutsideTargetRange_ISi 3000;
BA_REL_ "GenSigTimeoutTime" BU_SG_REL_ VCM SG_ 517 RideHeightOutsideTargetRange_ISi 120;
BA_REL_ "GenSigFirstTimeoutTime" BU_SG_REL_ VCM SG_ 517 DisableMechFaultDctnFr_rqst 3000;
BA_REL_ "GenSigTimeoutTime" BU_SG_REL_ VCM SG_ 517 DisableMechFaultDctnFr_rqst 120;
BA_REL_ "GenSigFirstTimeoutTime" BU_SG_REL_ CCIOM SG_ 517 DisableMechFaultDctnFr_rqst 3000;
BA_REL_ "GenSigTimeoutTime" BU_SG_REL_ CCIOM SG_ 517 DisableMechFaultDctnFr_rqst 120;
BA_REL_ "GenSigFirstTimeoutTime" BU_SG_REL_ VCM SG_ 517 BrakePressureSensorDemand_ISig_4 3000;
BA_REL_ "GenSigTimeoutTime" BU_SG_REL_ VCM SG_ 517 BrakePressureSensorDemand_ISig_4 500;
BA_REL_ "GenSigFirstTimeoutTime" BU_SG_REL_ VCM SG_ 517 FogLamp_Rear_Status 3000;
BA_REL_ "GenSigTimeoutTime" BU_SG_REL_ VCM SG_ 517 FogLamp_Rear_Status 120;
BA_REL_ "GenSigFirstTimeoutTime" BU_SG_REL_ VCM SG_ 517 LiftingControlModeFrontAxle 3000;
BA_REL_ "GenSigTimeoutTime" BU_SG_REL_ VCM SG_ 517 LiftingControlModeFrontAxle 120;
BA_REL_ "GenSigFirstTimeoutTime" BU_SG_REL_ VCM SG_ 517 LiftAxle1UpRequestACK_ISig_4 3000;
BA_REL_ "GenSigTimeoutTime" BU_SG_REL_ VCM SG_ 517 LiftAxle1UpRequestACK_ISig_4 120;
BA_REL_ "GenSigFirstTimeoutTime" BU_SG_REL_ VCM SG_ 517 LiftAxle1LiftFuncSelected_ISig_4 3000;
BA_REL_ "GenSigTimeoutTime" BU_SG_REL_ VCM SG_ 517 LiftAxle1LiftFuncSelected_ISig_4 120;
BA_REL_ "GenSigFirstTimeoutTime" BU_SG_REL_ VCM SG_ 517 RearAxleInBumperRange_ISig_4 3000;
BA_REL_ "GenSigTimeoutTime" BU_SG_REL_ VCM SG_ 517 RearAxleInBumperRange_ISig_4 500;
BA_REL_ "GenSigFirstTimeoutTime" BU_SG_REL_ VCM SG_ 1339 HeadlampFan_stat_ISig_4 6000;
BA_REL_ "GenSigTimeoutTime" BU_SG_REL_ VCM SG_ 1339 HeadlampFan_stat_ISig_4 1500;
BA_REL_ "GenSigFirstTimeoutTime" BU_SG_REL_ VCM SG_ 1339 FrontConspicLamp_stat_HiRight_IS 6000;
BA_REL_ "GenSigTimeoutTime" BU_SG_REL_ VCM SG_ 1339 FrontConspicLamp_stat_HiRight_IS 1500;
BA_REL_ "GenSigFirstTimeoutTime" BU_SG_REL_ VCM SG_ 1339 AmbientAirTemperature2 6000;
BA_REL_ "GenSigTimeoutTime" BU_SG_REL_ VCM SG_ 1339 AmbientAirTemperature2 1500;
BA_REL_ "GenSigFirstTimeoutTime" BU_SG_REL_ VCM SG_ 1339 FrontConspicLamp_stat_LoRight_IS 6000;
BA_REL_ "GenSigTimeoutTime" BU_SG_REL_ VCM SG_ 1339 FrontConspicLamp_stat_LoRight_IS 1500;
BA_REL_ "GenSigFirstTimeoutTime" BU_SG_REL_ VCM SG_ 1339 FrontConspicLamp_stat_HiLeft_ISi 6000;
BA_REL_ "GenSigTimeoutTime" BU_SG_REL_ VCM SG_ 1339 FrontConspicLamp_stat_HiLeft_ISi 1500;
BA_REL_ "GenSigFirstTimeoutTime" BU_SG_REL_ VCM SG_ 1339 FrontConspicLamp_stat_LoLeft_ISi 6000;
BA_REL_ "GenSigTimeoutTime" BU_SG_REL_ VCM SG_ 1339 FrontConspicLamp_stat_LoLeft_ISi 1500;
BA_REL_ "GenSigFirstTimeoutTime" BU_SG_REL_ VCM SG_ 1243 MainBeamLEDStatusRight_ISig_4 3000;
BA_REL_ "GenSigTimeoutTime" BU_SG_REL_ VCM SG_ 1243 MainBeamLEDStatusRight_ISig_4 600;
BA_REL_ "GenSigFirstTimeoutTime" BU_SG_REL_ VCM SG_ 1243 DeicingBulb_Stat_ISig_4 3000;
BA_REL_ "GenSigTimeoutTime" BU_SG_REL_ VCM SG_ 1243 DeicingBulb_Stat_ISig_4 600;
BA_REL_ "GenSigFirstTimeoutTime" BU_SG_REL_ VCM SG_ 1243 DeicingFunction_Stat_ISig_4 3000;
BA_REL_ "GenSigTimeoutTime" BU_SG_REL_ VCM SG_ 1243 DeicingFunction_Stat_ISig_4 600;
BA_REL_ "GenSigFirstTimeoutTime" BU_SG_REL_ VCM SG_ 1243 MainBeamLEDStatusLeft_ISig_4 3000;
BA_REL_ "GenSigTimeoutTime" BU_SG_REL_ VCM SG_ 1243 MainBeamLEDStatusLeft_ISig_4 600;
BA_REL_ "GenSigFirstTimeoutTime" BU_SG_REL_ VCM SG_ 952 DRLLamp_stat_ISig_4 3000;
BA_REL_ "GenSigTimeoutTime" BU_SG_REL_ VCM SG_ 952 DRLLamp_stat_ISig_4 300;
BA_REL_ "GenSigFirstTimeoutTime" BU_SG_REL_ VCM SG_ 952 FogLamp_Front_Status 3000;
BA_REL_ "GenSigTimeoutTime" BU_SG_REL_ VCM SG_ 952 FogLamp_Front_Status 300;
BA_REL_ "GenSigFirstTimeoutTime" BU_SG_REL_ VCM SG_ 952 DirIndSideLamp1_stat 3000;
BA_REL_ "GenSigTimeoutTime" BU_SG_REL_ VCM SG_ 952 DirIndSideLamp1_stat 300;
BA_REL_ "GenSigFirstTimeoutTime" BU_SG_REL_ VCM SG_ 952 PositionLightLamp_stat_ISig_4 3000;
BA_REL_ "GenSigTimeoutTime" BU_SG_REL_ VCM SG_ 952 PositionLightLamp_stat_ISig_4 300;
BA_REL_ "GenSigFirstTimeoutTime" BU_SG_REL_ VCM SG_ 952 DippedBeamLamp_stat_ISig_4 3000;
BA_REL_ "GenSigTimeoutTime" BU_SG_REL_ VCM SG_ 952 DippedBeamLamp_stat_ISig_4 300;
BA_REL_ "GenSigFirstTimeoutTime" BU_SG_REL_ VCM SG_ 952 MainBeamLamp_stat_ISig_4 3000;
BA_REL_ "GenSigTimeoutTime" BU_SG_REL_ VCM SG_ 952 MainBeamLamp_stat_ISig_4 300;
BA_REL_ "GenSigFirstTimeoutTime" BU_SG_REL_ VCM SG_ 952 StaticCornerLightLamp_stat_ISig_ 3000;
BA_REL_ "GenSigTimeoutTime" BU_SG_REL_ VCM SG_ 952 StaticCornerLightLamp_stat_ISig_ 300;
BA_REL_ "GenSigFirstTimeoutTime" BU_SG_REL_ VCM SG_ 952 AuxLamp_Front_Status 3000;
BA_REL_ "GenSigTimeoutTime" BU_SG_REL_ VCM SG_ 952 AuxLamp_Front_Status 300;
BA_REL_ "GenSigFirstTimeoutTime" BU_SG_REL_ VCM SG_ 952 AuxFogLightLamp_stat_ISig_4 3000;
BA_REL_ "GenSigTimeoutTime" BU_SG_REL_ VCM SG_ 952 AuxFogLightLamp_stat_ISig_4 300;
BA_REL_ "GenSigFirstTimeoutTime" BU_SG_REL_ VCM SG_ 952 ExtraMainBeamLamp_stat_ISig_4 3000;
BA_REL_ "GenSigTimeoutTime" BU_SG_REL_ VCM SG_ 952 ExtraMainBeamLamp_stat_ISig_4 300;
BA_REL_ "GenSigFirstTimeoutTime" BU_SG_REL_ VCM SG_ 952 AmbientAirTemperature1 3000;
BA_REL_ "GenSigTimeoutTime" BU_SG_REL_ VCM SG_ 952 AmbientAirTemperature1 300;
BA_REL_ "GenSigFirstTimeoutTime" BU_SG_REL_ VCM SG_ 952 FogLightFrontLamp_stat_ISig_4 3000;
BA_REL_ "GenSigTimeoutTime" BU_SG_REL_ VCM SG_ 952 FogLightFrontLamp_stat_ISig_4 300;
BA_REL_ "GenSigFirstTimeoutTime" BU_SG_REL_ VCM SG_ 952 DirInd_Front_Status_ISig_4 3000;
BA_REL_ "GenSigTimeoutTime" BU_SG_REL_ VCM SG_ 952 DirInd_Front_Status_ISig_4 300;
BA_REL_ "GenSigFirstTimeoutTime" BU_SG_REL_ VCM SG_ 952 ChassiInstepLightsLamp_stat_ISig 3000;
BA_REL_ "GenSigTimeoutTime" BU_SG_REL_ VCM SG_ 952 ChassiInstepLightsLamp_stat_ISig 300;
BA_REL_ "GenSigFirstTimeoutTime" BU_SG_REL_ VCM SG_ 952 WasherFluidLevel 3000;
BA_REL_ "GenSigTimeoutTime" BU_SG_REL_ VCM SG_ 952 WasherFluidLevel 300;
BA_REL_ "GenSigFirstTimeoutTime" BU_SG_REL_ WSGW SG_ 1511 Trailer5TireInfoISO_Temperature_ 24000;
BA_REL_ "GenSigTimeoutTime" BU_SG_REL_ WSGW SG_ 1511 Trailer5TireInfoISO_Temperature_ 6000;
BA_REL_ "GenSigFirstTimeoutTime" BU_SG_REL_ WSGW SG_ 1511 Trailer5TireInfoISO_Pressure_ISi 24000;
BA_REL_ "GenSigTimeoutTime" BU_SG_REL_ WSGW SG_ 1511 Trailer5TireInfoISO_Pressure_ISi 6000;
BA_REL_ "GenSigFirstTimeoutTime" BU_SG_REL_ WSGW SG_ 1511 Trailer5TireInfoISO_Leakage_ISig 24000;
BA_REL_ "GenSigTimeoutTime" BU_SG_REL_ WSGW SG_ 1511 Trailer5TireInfoISO_Leakage_ISig 6000;
BA_REL_ "GenSigFirstTimeoutTime" BU_SG_REL_ WSGW SG_ 1511 Trailer5TireInfoISO_PresSuff_ISi 24000;
BA_REL_ "GenSigTimeoutTime" BU_SG_REL_ WSGW SG_ 1511 Trailer5TireInfoISO_PresSuff_ISi 6000;
BA_REL_ "GenSigFirstTimeoutTime" BU_SG_REL_ WSGW SG_ 1511 Trailer5TireInfoISO_PowerSupply_ 24000;
BA_REL_ "GenSigTimeoutTime" BU_SG_REL_ WSGW SG_ 1511 Trailer5TireInfoISO_PowerSupply_ 6000;
BA_REL_ "GenSigFirstTimeoutTime" BU_SG_REL_ WSGW SG_ 1511 Trailer5TireInfoISO_Warning_ISig 24000;
BA_REL_ "GenSigTimeoutTime" BU_SG_REL_ WSGW SG_ 1511 Trailer5TireInfoISO_Warning_ISig 6000;
BA_REL_ "GenSigFirstTimeoutTime" BU_SG_REL_ WSGW SG_ 1511 Trailer5TireInfoISO_TireId_ISig_ 24000;
BA_REL_ "GenSigTimeoutTime" BU_SG_REL_ WSGW SG_ 1511 Trailer5TireInfoISO_TireId_ISig_ 6000;
BA_REL_ "GenSigFirstTimeoutTime" BU_SG_REL_ WSGW SG_ 1511 Trailer5TireInfoISO_Active_ISig_ 24000;
BA_REL_ "GenSigTimeoutTime" BU_SG_REL_ WSGW SG_ 1511 Trailer5TireInfoISO_Active_ISig_ 6000;
BA_REL_ "GenSigFirstTimeoutTime" BU_SG_REL_ WSGW SG_ 1509 Trailer4TireInfoISO_Temperature_ 24000;
BA_REL_ "GenSigTimeoutTime" BU_SG_REL_ WSGW SG_ 1509 Trailer4TireInfoISO_Temperature_ 6000;
BA_REL_ "GenSigFirstTimeoutTime" BU_SG_REL_ WSGW SG_ 1509 Trailer4TireInfoISO_PresSuff_ISi 24000;
BA_REL_ "GenSigTimeoutTime" BU_SG_REL_ WSGW SG_ 1509 Trailer4TireInfoISO_PresSuff_ISi 6000;
BA_REL_ "GenSigFirstTimeoutTime" BU_SG_REL_ WSGW SG_ 1509 Trailer4TireInfoISO_Leakage_ISig 24000;
BA_REL_ "GenSigTimeoutTime" BU_SG_REL_ WSGW SG_ 1509 Trailer4TireInfoISO_Leakage_ISig 6000;
BA_REL_ "GenSigFirstTimeoutTime" BU_SG_REL_ WSGW SG_ 1509 Trailer4TireInfoISO_PowerSupply_ 24000;
BA_REL_ "GenSigTimeoutTime" BU_SG_REL_ WSGW SG_ 1509 Trailer4TireInfoISO_PowerSupply_ 6000;
BA_REL_ "GenSigFirstTimeoutTime" BU_SG_REL_ WSGW SG_ 1509 Trailer4TireInfoISO_Warning_ISig 24000;
BA_REL_ "GenSigTimeoutTime" BU_SG_REL_ WSGW SG_ 1509 Trailer4TireInfoISO_Warning_ISig 6000;
BA_REL_ "GenSigFirstTimeoutTime" BU_SG_REL_ WSGW SG_ 1509 Trailer4TireInfoISO_TireId_ISig_ 24000;
BA_REL_ "GenSigTimeoutTime" BU_SG_REL_ WSGW SG_ 1509 Trailer4TireInfoISO_TireId_ISig_ 6000;
BA_REL_ "GenSigFirstTimeoutTime" BU_SG_REL_ WSGW SG_ 1509 Trailer4TireInfoISO_Pressure_ISi 24000;
BA_REL_ "GenSigTimeoutTime" BU_SG_REL_ WSGW SG_ 1509 Trailer4TireInfoISO_Pressure_ISi 6000;
BA_REL_ "GenSigFirstTimeoutTime" BU_SG_REL_ WSGW SG_ 1509 Trailer4TireInfoISO_Active_ISig_ 24000;
BA_REL_ "GenSigTimeoutTime" BU_SG_REL_ WSGW SG_ 1509 Trailer4TireInfoISO_Active_ISig_ 6000;
BA_REL_ "GenSigFirstTimeoutTime" BU_SG_REL_ WSGW SG_ 1508 Trailer3TireInfoISO_Active_ISig_ 24000;
BA_REL_ "GenSigTimeoutTime" BU_SG_REL_ WSGW SG_ 1508 Trailer3TireInfoISO_Active_ISig_ 6000;
BA_REL_ "GenSigFirstTimeoutTime" BU_SG_REL_ WSGW SG_ 1508 Trailer3TireInfoISO_Warning_ISig 24000;
BA_REL_ "GenSigTimeoutTime" BU_SG_REL_ WSGW SG_ 1508 Trailer3TireInfoISO_Warning_ISig 6000;
BA_REL_ "GenSigFirstTimeoutTime" BU_SG_REL_ WSGW SG_ 1508 Trailer3TireInfoISO_TireId_ISig_ 24000;
BA_REL_ "GenSigTimeoutTime" BU_SG_REL_ WSGW SG_ 1508 Trailer3TireInfoISO_TireId_ISig_ 6000;
BA_REL_ "GenSigFirstTimeoutTime" BU_SG_REL_ WSGW SG_ 1508 Trailer3TireInfoISO_Pressure_ISi 24000;
BA_REL_ "GenSigTimeoutTime" BU_SG_REL_ WSGW SG_ 1508 Trailer3TireInfoISO_Pressure_ISi 6000;
BA_REL_ "GenSigFirstTimeoutTime" BU_SG_REL_ WSGW SG_ 1508 Trailer3TireInfoISO_Temperature_ 24000;
BA_REL_ "GenSigTimeoutTime" BU_SG_REL_ WSGW SG_ 1508 Trailer3TireInfoISO_Temperature_ 6000;
BA_REL_ "GenSigFirstTimeoutTime" BU_SG_REL_ WSGW SG_ 1508 Trailer3TireInfoISO_Leakage_ISig 24000;
BA_REL_ "GenSigTimeoutTime" BU_SG_REL_ WSGW SG_ 1508 Trailer3TireInfoISO_Leakage_ISig 6000;
BA_REL_ "GenSigFirstTimeoutTime" BU_SG_REL_ WSGW SG_ 1508 Trailer3TireInfoISO_PowerSupply_ 24000;
BA_REL_ "GenSigTimeoutTime" BU_SG_REL_ WSGW SG_ 1508 Trailer3TireInfoISO_PowerSupply_ 6000;
BA_REL_ "GenSigFirstTimeoutTime" BU_SG_REL_ WSGW SG_ 1508 Trailer3TireInfoISO_PresSuff_ISi 24000;
BA_REL_ "GenSigTimeoutTime" BU_SG_REL_ WSGW SG_ 1508 Trailer3TireInfoISO_PresSuff_ISi 6000;
BA_REL_ "GenSigFirstTimeoutTime" BU_SG_REL_ WSGW SG_ 959 WhlSpdSenTothCnt456_Axle6Left_IS 3000;
BA_REL_ "GenSigTimeoutTime" BU_SG_REL_ WSGW SG_ 959 WhlSpdSenTothCnt456_Axle6Left_IS 300;
BA_REL_ "GenSigFirstTimeoutTime" BU_SG_REL_ WSGW SG_ 959 WhlSpdSenTothCnt456_Axle5Right_I 3000;
BA_REL_ "GenSigTimeoutTime" BU_SG_REL_ WSGW SG_ 959 WhlSpdSenTothCnt456_Axle5Right_I 300;
BA_REL_ "GenSigFirstTimeoutTime" BU_SG_REL_ WSGW SG_ 959 WhlSpdSenTothCnt456_Axle5Left_IS 3000;
BA_REL_ "GenSigTimeoutTime" BU_SG_REL_ WSGW SG_ 959 WhlSpdSenTothCnt456_Axle5Left_IS 300;
BA_REL_ "GenSigFirstTimeoutTime" BU_SG_REL_ WSGW SG_ 959 WhlSpdSenTothCnt456_Axle4Right_I 3000;
BA_REL_ "GenSigTimeoutTime" BU_SG_REL_ WSGW SG_ 959 WhlSpdSenTothCnt456_Axle4Right_I 300;
BA_REL_ "GenSigFirstTimeoutTime" BU_SG_REL_ WSGW SG_ 959 WhlSpdSenTothCnt456_TimeStamp_IS 3000;
BA_REL_ "GenSigTimeoutTime" BU_SG_REL_ WSGW SG_ 959 WhlSpdSenTothCnt456_TimeStamp_IS 300;
BA_REL_ "GenSigFirstTimeoutTime" BU_SG_REL_ WSGW SG_ 959 WhlSpdSenTothCnt456_Axle6Right_I 3000;
BA_REL_ "GenSigTimeoutTime" BU_SG_REL_ WSGW SG_ 959 WhlSpdSenTothCnt456_Axle6Right_I 300;
BA_REL_ "GenSigFirstTimeoutTime" BU_SG_REL_ WSGW SG_ 959 WhlSpdSenTothCnt456_Axle4Left_IS 3000;
BA_REL_ "GenSigTimeoutTime" BU_SG_REL_ WSGW SG_ 959 WhlSpdSenTothCnt456_Axle4Left_IS 300;
BA_REL_ "GenSigFirstTimeoutTime" BU_SG_REL_ WSGW SG_ 832 WhlSpdSenTothCnt123_TimeStamp_IS 3000;
BA_REL_ "GenSigTimeoutTime" BU_SG_REL_ WSGW SG_ 832 WhlSpdSenTothCnt123_TimeStamp_IS 300;
BA_REL_ "GenSigFirstTimeoutTime" BU_SG_REL_ WSGW SG_ 832 WhlSpdSenTothCnt123_Axle2Right_I 3000;
BA_REL_ "GenSigTimeoutTime" BU_SG_REL_ WSGW SG_ 832 WhlSpdSenTothCnt123_Axle2Right_I 300;
BA_REL_ "GenSigFirstTimeoutTime" BU_SG_REL_ WSGW SG_ 832 WhlSpdSenTothCnt123_Axle3Right_I 3000;
BA_REL_ "GenSigTimeoutTime" BU_SG_REL_ WSGW SG_ 832 WhlSpdSenTothCnt123_Axle3Right_I 300;
BA_REL_ "GenSigFirstTimeoutTime" BU_SG_REL_ WSGW SG_ 832 WhlSpdSenTothCnt123_Axle1Right_I 3000;
BA_REL_ "GenSigTimeoutTime" BU_SG_REL_ WSGW SG_ 832 WhlSpdSenTothCnt123_Axle1Right_I 300;
BA_REL_ "GenSigFirstTimeoutTime" BU_SG_REL_ WSGW SG_ 832 WhlSpdSenTothCnt123_Axle1Left_IS 3000;
BA_REL_ "GenSigTimeoutTime" BU_SG_REL_ WSGW SG_ 832 WhlSpdSenTothCnt123_Axle1Left_IS 300;
BA_REL_ "GenSigFirstTimeoutTime" BU_SG_REL_ WSGW SG_ 832 WhlSpdSenTothCnt123_Axle2Left_IS 3000;
BA_REL_ "GenSigTimeoutTime" BU_SG_REL_ WSGW SG_ 832 WhlSpdSenTothCnt123_Axle2Left_IS 300;
BA_REL_ "GenSigFirstTimeoutTime" BU_SG_REL_ WSGW SG_ 832 WhlSpdSenTothCnt123_Axle3Left_IS 3000;
BA_REL_ "GenSigTimeoutTime" BU_SG_REL_ WSGW SG_ 832 WhlSpdSenTothCnt123_Axle3Left_IS 300;
BA_REL_ "GenSigFirstTimeoutTime" BU_SG_REL_ RCIOM SG_ 1232 TrailerCommunicationType_ISig_4 3000;
BA_REL_ "GenSigTimeoutTime" BU_SG_REL_ RCIOM SG_ 1232 TrailerCommunicationType_ISig_4 600;
BA_REL_ "GenSigFirstTimeoutTime" BU_SG_REL_ WSGW SG_ 1507 PLCBusStatus_ISig_4 24000;
BA_REL_ "GenSigTimeoutTime" BU_SG_REL_ WSGW SG_ 1507 PLCBusStatus_ISig_4 6000;
BA_REL_ "GenSigFirstTimeoutTime" BU_SG_REL_ WSGW SG_ 1501 Trailer2TireInfoISO_PowerSupply_ 24000;
BA_REL_ "GenSigTimeoutTime" BU_SG_REL_ WSGW SG_ 1501 Trailer2TireInfoISO_PowerSupply_ 6000;
BA_REL_ "GenSigFirstTimeoutTime" BU_SG_REL_ WSGW SG_ 1501 Trailer2TireInfoISO_Temperature_ 24000;
BA_REL_ "GenSigTimeoutTime" BU_SG_REL_ WSGW SG_ 1501 Trailer2TireInfoISO_Temperature_ 6000;
BA_REL_ "GenSigFirstTimeoutTime" BU_SG_REL_ WSGW SG_ 1501 Trailer2TireInfoISO_PresSuff_ISi 24000;
BA_REL_ "GenSigTimeoutTime" BU_SG_REL_ WSGW SG_ 1501 Trailer2TireInfoISO_PresSuff_ISi 6000;
BA_REL_ "GenSigFirstTimeoutTime" BU_SG_REL_ WSGW SG_ 1501 Trailer2TireInfoISO_Pressure_ISi 24000;
BA_REL_ "GenSigTimeoutTime" BU_SG_REL_ WSGW SG_ 1501 Trailer2TireInfoISO_Pressure_ISi 6000;
BA_REL_ "GenSigFirstTimeoutTime" BU_SG_REL_ WSGW SG_ 1501 Trailer2TireInfoISO_Warning_ISig 24000;
BA_REL_ "GenSigTimeoutTime" BU_SG_REL_ WSGW SG_ 1501 Trailer2TireInfoISO_Warning_ISig 6000;
BA_REL_ "GenSigFirstTimeoutTime" BU_SG_REL_ WSGW SG_ 1501 Trailer2TireInfoISO_TireId_ISig_ 24000;
BA_REL_ "GenSigTimeoutTime" BU_SG_REL_ WSGW SG_ 1501 Trailer2TireInfoISO_TireId_ISig_ 6000;
BA_REL_ "GenSigFirstTimeoutTime" BU_SG_REL_ WSGW SG_ 1501 Trailer2TireInfoISO_Leakage_ISig 24000;
BA_REL_ "GenSigTimeoutTime" BU_SG_REL_ WSGW SG_ 1501 Trailer2TireInfoISO_Leakage_ISig 6000;
BA_REL_ "GenSigFirstTimeoutTime" BU_SG_REL_ WSGW SG_ 1501 Trailer2TireInfoISO_Active_ISig_ 24000;
BA_REL_ "GenSigTimeoutTime" BU_SG_REL_ WSGW SG_ 1501 Trailer2TireInfoISO_Active_ISig_ 6000;
BA_REL_ "GenSigFirstTimeoutTime" BU_SG_REL_ WSGW SG_ 1498 Trailer1TireInfoISO_Leakage_ISig 24000;
BA_REL_ "GenSigTimeoutTime" BU_SG_REL_ WSGW SG_ 1498 Trailer1TireInfoISO_Leakage_ISig 6000;
BA_REL_ "GenSigFirstTimeoutTime" BU_SG_REL_ WSGW SG_ 1498 Trailer1TireInfoISO_Active_ISig_ 24000;
BA_REL_ "GenSigTimeoutTime" BU_SG_REL_ WSGW SG_ 1498 Trailer1TireInfoISO_Active_ISig_ 6000;
BA_REL_ "GenSigFirstTimeoutTime" BU_SG_REL_ WSGW SG_ 1498 Trailer1TireInfoISO_Warning_ISig 24000;
BA_REL_ "GenSigTimeoutTime" BU_SG_REL_ WSGW SG_ 1498 Trailer1TireInfoISO_Warning_ISig 6000;
BA_REL_ "GenSigFirstTimeoutTime" BU_SG_REL_ WSGW SG_ 1498 Trailer1TireInfoISO_PowerSupply_ 24000;
BA_REL_ "GenSigTimeoutTime" BU_SG_REL_ WSGW SG_ 1498 Trailer1TireInfoISO_PowerSupply_ 6000;
BA_REL_ "GenSigFirstTimeoutTime" BU_SG_REL_ WSGW SG_ 1498 Trailer1TireInfoISO_PresSuff_ISi 24000;
BA_REL_ "GenSigTimeoutTime" BU_SG_REL_ WSGW SG_ 1498 Trailer1TireInfoISO_PresSuff_ISi 6000;
BA_REL_ "GenSigFirstTimeoutTime" BU_SG_REL_ WSGW SG_ 1498 Trailer1TireInfoISO_Temperature_ 24000;
BA_REL_ "GenSigTimeoutTime" BU_SG_REL_ WSGW SG_ 1498 Trailer1TireInfoISO_Temperature_ 6000;
BA_REL_ "GenSigFirstTimeoutTime" BU_SG_REL_ WSGW SG_ 1498 Trailer1TireInfoISO_TireId_ISig_ 24000;
BA_REL_ "GenSigTimeoutTime" BU_SG_REL_ WSGW SG_ 1498 Trailer1TireInfoISO_TireId_ISig_ 6000;
BA_REL_ "GenSigFirstTimeoutTime" BU_SG_REL_ WSGW SG_ 1498 Trailer1TireInfoISO_Pressure_ISi 24000;
BA_REL_ "GenSigTimeoutTime" BU_SG_REL_ WSGW SG_ 1498 Trailer1TireInfoISO_Pressure_ISi 6000;
BA_REL_ "GenSigFirstTimeoutTime" BU_SG_REL_ RCIOM SG_ 396 ThrdRrDriveAxLeftWheelSpeed_ISig 3000;
BA_REL_ "GenSigTimeoutTime" BU_SG_REL_ RCIOM SG_ 396 ThrdRrDriveAxLeftWheelSpeed_ISig 60;
BA_REL_ "GenSigFirstTimeoutTime" BU_SG_REL_ RCIOM SG_ 396 ThrdRrDriveAxRightWheelSpeed_ISi 3000;
BA_REL_ "GenSigTimeoutTime" BU_SG_REL_ RCIOM SG_ 396 ThrdRrDriveAxRightWheelSpeed_ISi 60;
BA_REL_ "GenSigFirstTimeoutTime" BU_SG_REL_ RCIOM SG_ 395 SteeringWheelAngle_ISig_4 3000;
BA_REL_ "GenSigTimeoutTime" BU_SG_REL_ RCIOM SG_ 395 SteeringWheelAngle_ISig_4 500;
BA_REL_ "GenSigFirstTimeoutTime" BU_SG_REL_ CCIOM SG_ 394 ScndRrDriveAxleLeftWheelSpeed_IS 3000;
BA_REL_ "GenSigTimeoutTime" BU_SG_REL_ CCIOM SG_ 394 ScndRrDriveAxleLeftWheelSpeed_IS 60;
BA_REL_ "GenSigFirstTimeoutTime" BU_SG_REL_ RCIOM SG_ 394 ScndRrDriveAxleLeftWheelSpeed_IS 3000;
BA_REL_ "GenSigTimeoutTime" BU_SG_REL_ RCIOM SG_ 394 ScndRrDriveAxleLeftWheelSpeed_IS 60;
BA_REL_ "GenSigFirstTimeoutTime" BU_SG_REL_ RCIOM SG_ 394 ScndRrDriveAxleRightWheelSpeed_I 3000;
BA_REL_ "GenSigTimeoutTime" BU_SG_REL_ RCIOM SG_ 394 ScndRrDriveAxleRightWheelSpeed_I 60;
BA_REL_ "GenSigFirstTimeoutTime" BU_SG_REL_ CCIOM SG_ 394 ScndRrDriveAxleRightWheelSpeed_I 3000;
BA_REL_ "GenSigTimeoutTime" BU_SG_REL_ CCIOM SG_ 394 ScndRrDriveAxleRightWheelSpeed_I 60;
BA_REL_ "GenSigFirstTimeoutTime" BU_SG_REL_ RCIOM SG_ 386 LateralAcceleration_ISig_4 3000;
BA_REL_ "GenSigTimeoutTime" BU_SG_REL_ RCIOM SG_ 386 LateralAcceleration_ISig_4 60;
BA_REL_ "GenSigFirstTimeoutTime" BU_SG_REL_ RCIOM SG_ 386 VDCBrakeLightRequest_ISig_4 3000;
BA_REL_ "GenSigTimeoutTime" BU_SG_REL_ RCIOM SG_ 386 VDCBrakeLightRequest_ISig_4 60;
BA_REL_ "GenSigFirstTimeoutTime" BU_SG_REL_ RCIOM SG_ 386 EBSBrakeSwitch_ISig_4 3000;
BA_REL_ "GenSigTimeoutTime" BU_SG_REL_ RCIOM SG_ 386 EBSBrakeSwitch_ISig_4 60;
BA_REL_ "GenSigFirstTimeoutTime" BU_SG_REL_ RCIOM SG_ 386 BrakeLightActivationRequest_ISig 3000;
BA_REL_ "GenSigTimeoutTime" BU_SG_REL_ RCIOM SG_ 386 BrakeLightActivationRequest_ISig 60;
BA_REL_ "GenSigFirstTimeoutTime" BU_SG_REL_ RCIOM SG_ 386 LongitudinalAcceleration_ISig_4 3000;
BA_REL_ "GenSigTimeoutTime" BU_SG_REL_ RCIOM SG_ 386 LongitudinalAcceleration_ISig_4 60;
BA_REL_ "GenSigFirstTimeoutTime" BU_SG_REL_ RCIOM SG_ 824 Trailer1TractionHelp_ISig_4 3000;
BA_REL_ "GenSigTimeoutTime" BU_SG_REL_ RCIOM SG_ 824 Trailer1TractionHelp_ISig_4 180;
BA_REL_ "GenSigFirstTimeoutTime" BU_SG_REL_ RCIOM SG_ 824 TrailerBrake_Stat_ISig_4 3000;
BA_REL_ "GenSigTimeoutTime" BU_SG_REL_ RCIOM SG_ 824 TrailerBrake_Stat_ISig_4 180;
BA_REL_ "GenSigFirstTimeoutTime" BU_SG_REL_ CCIOM SG_ 824 SplitBoxDiffLockActvnFuncReq_ISi 3000;
BA_REL_ "GenSigTimeoutTime" BU_SG_REL_ CCIOM SG_ 824 SplitBoxDiffLockActvnFuncReq_ISi 180;
BA_REL_ "GenSigFirstTimeoutTime" BU_SG_REL_ CCIOM SG_ 824 BrakingSystemPressureLim_rqst_IS 3000;
BA_REL_ "GenSigTimeoutTime" BU_SG_REL_ CCIOM SG_ 824 BrakingSystemPressureLim_rqst_IS 180;
BA_REL_ "GenSigFirstTimeoutTime" BU_SG_REL_ RCIOM SG_ 824 TagLiftAxleLoweringInhibit 3000;
BA_REL_ "GenSigTimeoutTime" BU_SG_REL_ RCIOM SG_ 824 TagLiftAxleLoweringInhibit 180;
BA_REL_ "GenSigFirstTimeoutTime" BU_SG_REL_ RCIOM SG_ 824 ScndRrAxlDiffLckActvnFuncReq_ISi 3000;
BA_REL_ "GenSigTimeoutTime" BU_SG_REL_ RCIOM SG_ 824 ScndRrAxlDiffLckActvnFuncReq_ISi 180;
BA_REL_ "GenSigFirstTimeoutTime" BU_SG_REL_ RCIOM SG_ 824 Trailer1LiftAxle1Pos_ISig_4 3000;
BA_REL_ "GenSigTimeoutTime" BU_SG_REL_ RCIOM SG_ 824 Trailer1LiftAxle1Pos_ISig_4 180;
BA_REL_ "GenSigFirstTimeoutTime" BU_SG_REL_ RCIOM SG_ 824 PusherLiftAxleLoweringInhibit_IS 3000;
BA_REL_ "GenSigTimeoutTime" BU_SG_REL_ RCIOM SG_ 824 PusherLiftAxleLoweringInhibit_IS 180;
BA_REL_ "GenSigFirstTimeoutTime" BU_SG_REL_ RCIOM SG_ 824 StretchBrake_Stat_ISig_4 3000;
BA_REL_ "GenSigTimeoutTime" BU_SG_REL_ RCIOM SG_ 824 StretchBrake_Stat_ISig_4 180;
BA_REL_ "GenSigFirstTimeoutTime" BU_SG_REL_ RCIOM SG_ 824 TrailersConnected_ISig_4 3000;
BA_REL_ "GenSigTimeoutTime" BU_SG_REL_ RCIOM SG_ 824 TrailersConnected_ISig_4 180;
BA_REL_ "GenSigFirstTimeoutTime" BU_SG_REL_ RCIOM SG_ 824 Trailer1LiftAxle2Pos_ISig_4 3000;
BA_REL_ "GenSigTimeoutTime" BU_SG_REL_ RCIOM SG_ 824 Trailer1LiftAxle2Pos_ISig_4 180;
BA_REL_ "GenSigFirstTimeoutTime" BU_SG_REL_ RCIOM SG_ 824 TrailerEBSAmberWarning_ISig_4 3000;
BA_REL_ "GenSigTimeoutTime" BU_SG_REL_ RCIOM SG_ 824 TrailerEBSAmberWarning_ISig_4 180;
BA_REL_ "GenSigFirstTimeoutTime" BU_SG_REL_ RCIOM SG_ 516 EASPusherLiftAxleLoweringInhib 3000;
BA_REL_ "GenSigTimeoutTime" BU_SG_REL_ RCIOM SG_ 516 EASPusherLiftAxleLoweringInhib 120;
BA_REL_ "GenSigFirstTimeoutTime" BU_SG_REL_ VCM SG_ 1500 DiagFaultStat_RCIOM_DtcIdB 24000;
BA_REL_ "GenSigTimeoutTime" BU_SG_REL_ VCM SG_ 1500 DiagFaultStat_RCIOM_DtcIdB 6000;
BA_REL_ "GenSigFirstTimeoutTime" BU_SG_REL_ VCM SG_ 1500 DiagFaultStat_RCIOM_FailTA 24000;
BA_REL_ "GenSigTimeoutTime" BU_SG_REL_ VCM SG_ 1500 DiagFaultStat_RCIOM_FailTA 6000;
BA_REL_ "GenSigFirstTimeoutTime" BU_SG_REL_ VCM SG_ 1500 DiagFaultStat_RCIOM_FailTB 24000;
BA_REL_ "GenSigTimeoutTime" BU_SG_REL_ VCM SG_ 1500 DiagFaultStat_RCIOM_FailTB 6000;
BA_REL_ "GenSigFirstTimeoutTime" BU_SG_REL_ VCM SG_ 1500 DiagFaultStat_RCIOM_DtcIdA 24000;
BA_REL_ "GenSigTimeoutTime" BU_SG_REL_ VCM SG_ 1500 DiagFaultStat_RCIOM_DtcIdA 6000;
BA_REL_ "GenSigFirstTimeoutTime" BU_SG_REL_ VCM SG_ 1500 DiagFaultStat_RCIOM_EcuAdr 24000;
BA_REL_ "GenSigTimeoutTime" BU_SG_REL_ VCM SG_ 1500 DiagFaultStat_RCIOM_EcuAdr 6000;
BA_REL_ "GenSigFirstTimeoutTime" BU_SG_REL_ VCM SG_ 1497 DiagFaultStat_GFHCM2_DtcIdA 24000;
BA_REL_ "GenSigTimeoutTime" BU_SG_REL_ VCM SG_ 1497 DiagFaultStat_GFHCM2_DtcIdA 6000;
BA_REL_ "GenSigFirstTimeoutTime" BU_SG_REL_ VCM SG_ 1497 DiagFaultStat_GFHCM2_FailTB 24000;
BA_REL_ "GenSigTimeoutTime" BU_SG_REL_ VCM SG_ 1497 DiagFaultStat_GFHCM2_FailTB 6000;
BA_REL_ "GenSigFirstTimeoutTime" BU_SG_REL_ VCM SG_ 1497 DiagFaultStat_GFHCM2_DtcIdB 24000;
BA_REL_ "GenSigTimeoutTime" BU_SG_REL_ VCM SG_ 1497 DiagFaultStat_GFHCM2_DtcIdB 6000;
BA_REL_ "GenSigFirstTimeoutTime" BU_SG_REL_ VCM SG_ 1497 DiagFaultStat_GFHCM2_EcuAdr 24000;
BA_REL_ "GenSigTimeoutTime" BU_SG_REL_ VCM SG_ 1497 DiagFaultStat_GFHCM2_EcuAdr 6000;
BA_REL_ "GenSigFirstTimeoutTime" BU_SG_REL_ VCM SG_ 1497 DiagFaultStat_GFHCM2_FailTA 24000;
BA_REL_ "GenSigTimeoutTime" BU_SG_REL_ VCM SG_ 1497 DiagFaultStat_GFHCM2_FailTA 6000;
BA_REL_ "GenSigFirstTimeoutTime" BU_SG_REL_ VCM SG_ 1496 DiagFaultStat_GFHCM1_EcuAdr 24000;
BA_REL_ "GenSigTimeoutTime" BU_SG_REL_ VCM SG_ 1496 DiagFaultStat_GFHCM1_EcuAdr 6000;
BA_REL_ "GenSigFirstTimeoutTime" BU_SG_REL_ VCM SG_ 1496 DiagFaultStat_GFHCM1_DtcIdB 24000;
BA_REL_ "GenSigTimeoutTime" BU_SG_REL_ VCM SG_ 1496 DiagFaultStat_GFHCM1_DtcIdB 6000;
BA_REL_ "GenSigFirstTimeoutTime" BU_SG_REL_ VCM SG_ 1496 DiagFaultStat_GFHCM1_FailTB 24000;
BA_REL_ "GenSigTimeoutTime" BU_SG_REL_ VCM SG_ 1496 DiagFaultStat_GFHCM1_FailTB 6000;
BA_REL_ "GenSigFirstTimeoutTime" BU_SG_REL_ VCM SG_ 1496 DiagFaultStat_GFHCM1_FailTA 24000;
BA_REL_ "GenSigTimeoutTime" BU_SG_REL_ VCM SG_ 1496 DiagFaultStat_GFHCM1_FailTA 6000;
BA_REL_ "GenSigFirstTimeoutTime" BU_SG_REL_ VCM SG_ 1496 DiagFaultStat_GFHCM1_DtcIdA 24000;
BA_REL_ "GenSigTimeoutTime" BU_SG_REL_ VCM SG_ 1496 DiagFaultStat_GFHCM1_DtcIdA 6000;
BA_REL_ "GenSigFirstTimeoutTime" BU_SG_REL_ VCM SG_ 1499 DiagFaultStat_FCIOM_DtcIdA 24000;
BA_REL_ "GenSigTimeoutTime" BU_SG_REL_ VCM SG_ 1499 DiagFaultStat_FCIOM_DtcIdA 6000;
BA_REL_ "GenSigFirstTimeoutTime" BU_SG_REL_ VCM SG_ 1499 DiagFaultStat_FCIOM_FailTA 24000;
BA_REL_ "GenSigTimeoutTime" BU_SG_REL_ VCM SG_ 1499 DiagFaultStat_FCIOM_FailTA 6000;
BA_REL_ "GenSigFirstTimeoutTime" BU_SG_REL_ VCM SG_ 1499 DiagFaultStat_FCIOM_FailTB 24000;
BA_REL_ "GenSigTimeoutTime" BU_SG_REL_ VCM SG_ 1499 DiagFaultStat_FCIOM_FailTB 6000;
BA_REL_ "GenSigFirstTimeoutTime" BU_SG_REL_ VCM SG_ 1499 DiagFaultStat_FCIOM_DtcIdB 24000;
BA_REL_ "GenSigTimeoutTime" BU_SG_REL_ VCM SG_ 1499 DiagFaultStat_FCIOM_DtcIdB 6000;
BA_REL_ "GenSigFirstTimeoutTime" BU_SG_REL_ VCM SG_ 1499 DiagFaultStat_FCIOM_EcuAdr 24000;
BA_REL_ "GenSigTimeoutTime" BU_SG_REL_ VCM SG_ 1499 DiagFaultStat_FCIOM_EcuAdr 6000;
BA_REL_ "GenSigFirstTimeoutTime" BU_SG_REL_ VCM SG_ 1490 DiagFaultStat_CCIOM_EcuAdr 24000;
BA_REL_ "GenSigTimeoutTime" BU_SG_REL_ VCM SG_ 1490 DiagFaultStat_CCIOM_EcuAdr 6000;
BA_REL_ "GenSigFirstTimeoutTime" BU_SG_REL_ VCM SG_ 1490 DiagFaultStat_CCIOM_FailTA 24000;
BA_REL_ "GenSigTimeoutTime" BU_SG_REL_ VCM SG_ 1490 DiagFaultStat_CCIOM_FailTA 6000;
BA_REL_ "GenSigFirstTimeoutTime" BU_SG_REL_ VCM SG_ 1490 DiagFaultStat_CCIOM_DtcIdB 24000;
BA_REL_ "GenSigTimeoutTime" BU_SG_REL_ VCM SG_ 1490 DiagFaultStat_CCIOM_DtcIdB 6000;
BA_REL_ "GenSigFirstTimeoutTime" BU_SG_REL_ VCM SG_ 1490 DiagFaultStat_CCIOM_FailTB 24000;
BA_REL_ "GenSigTimeoutTime" BU_SG_REL_ VCM SG_ 1490 DiagFaultStat_CCIOM_FailTB 6000;
BA_REL_ "GenSigFirstTimeoutTime" BU_SG_REL_ VCM SG_ 1490 DiagFaultStat_CCIOM_DtcIdA 24000;
BA_REL_ "GenSigTimeoutTime" BU_SG_REL_ VCM SG_ 1490 DiagFaultStat_CCIOM_DtcIdA 6000;
BA_REL_ "GenSigFirstTimeoutTime" BU_SG_REL_ VCM SG_ 1253 SensorCleaningFluidLevel_ISig_4 3000;
BA_REL_ "GenSigTimeoutTime" BU_SG_REL_ VCM SG_ 1253 SensorCleaningFluidLevel_ISig_4 600;
BA_REL_ "GenSigFirstTimeoutTime" BU_SG_REL_ VCM SG_ 1253 SensorCleaningPumpPressure_ISig_ 3000;
BA_REL_ "GenSigTimeoutTime" BU_SG_REL_ VCM SG_ 1253 SensorCleaningPumpPressure_ISig_ 600;
BA_REL_ "GenSigFirstTimeoutTime" BU_SG_REL_ VCM SG_ 1253 SensorCleaningFluidLevelStatus_I 3000;
BA_REL_ "GenSigTimeoutTime" BU_SG_REL_ VCM SG_ 1253 SensorCleaningFluidLevelStatus_I 600;
BA_REL_ "GenSigFirstTimeoutTime" BU_SG_REL_ VCM SG_ 1372 OpLevelItem11 12000;
BA_REL_ "GenSigTimeoutTime" BU_SG_REL_ VCM SG_ 1372 OpLevelItem11 3000;
BA_REL_ "GenSigFirstTimeoutTime" BU_SG_REL_ VCM SG_ 1372 OpLevelItem14 12000;
BA_REL_ "GenSigTimeoutTime" BU_SG_REL_ VCM SG_ 1372 OpLevelItem14 3000;
BA_REL_ "GenSigFirstTimeoutTime" BU_SG_REL_ VCM SG_ 1372 OpLevelItem12 12000;
BA_REL_ "GenSigTimeoutTime" BU_SG_REL_ VCM SG_ 1372 OpLevelItem12 3000;
BA_REL_ "GenSigFirstTimeoutTime" BU_SG_REL_ VCM SG_ 1372 OpLevelItem15 12000;
BA_REL_ "GenSigTimeoutTime" BU_SG_REL_ VCM SG_ 1372 OpLevelItem15 3000;
BA_REL_ "GenSigFirstTimeoutTime" BU_SG_REL_ VCM SG_ 1372 OpLevelItem13 12000;
BA_REL_ "GenSigTimeoutTime" BU_SG_REL_ VCM SG_ 1372 OpLevelItem13 3000;
BA_REL_ "GenSigFirstTimeoutTime" BU_SG_REL_ VCM SG_ 1371 OpLevelItem1 12000;
BA_REL_ "GenSigTimeoutTime" BU_SG_REL_ VCM SG_ 1371 OpLevelItem1 3000;
BA_REL_ "GenSigFirstTimeoutTime" BU_SG_REL_ VCM SG_ 1371 OpLevelItem8 12000;
BA_REL_ "GenSigTimeoutTime" BU_SG_REL_ VCM SG_ 1371 OpLevelItem8 3000;
BA_REL_ "GenSigFirstTimeoutTime" BU_SG_REL_ VCM SG_ 1371 OpLevelItem5 12000;
BA_REL_ "GenSigTimeoutTime" BU_SG_REL_ VCM SG_ 1371 OpLevelItem5 3000;
BA_REL_ "GenSigFirstTimeoutTime" BU_SG_REL_ VCM SG_ 1371 OpLevelItem6 12000;
BA_REL_ "GenSigTimeoutTime" BU_SG_REL_ VCM SG_ 1371 OpLevelItem6 3000;
BA_REL_ "GenSigFirstTimeoutTime" BU_SG_REL_ VCM SG_ 1371 OpLevelItem10 12000;
BA_REL_ "GenSigTimeoutTime" BU_SG_REL_ VCM SG_ 1371 OpLevelItem10 3000;
BA_REL_ "GenSigFirstTimeoutTime" BU_SG_REL_ VCM SG_ 1371 OpLevelItem7 12000;
BA_REL_ "GenSigTimeoutTime" BU_SG_REL_ VCM SG_ 1371 OpLevelItem7 3000;
BA_REL_ "GenSigFirstTimeoutTime" BU_SG_REL_ VCM SG_ 1371 OpLevelItem9 12000;
BA_REL_ "GenSigTimeoutTime" BU_SG_REL_ VCM SG_ 1371 OpLevelItem9 3000;
BA_REL_ "GenSigFirstTimeoutTime" BU_SG_REL_ VCM SG_ 1371 OpLevelItem4 12000;
BA_REL_ "GenSigTimeoutTime" BU_SG_REL_ VCM SG_ 1371 OpLevelItem4 3000;
BA_REL_ "GenSigFirstTimeoutTime" BU_SG_REL_ VCM SG_ 1362 Cur_EnergySetting_ISig_4 12000;
BA_REL_ "GenSigTimeoutTime" BU_SG_REL_ VCM SG_ 1362 Cur_EnergySetting_ISig_4 3000;
BA_REL_ "GenSigFirstTimeoutTime" BU_SG_REL_ VCM SG_ 1362 Cur_LG5CutoffValue_ISig_4 12000;
BA_REL_ "GenSigTimeoutTime" BU_SG_REL_ VCM SG_ 1362 Cur_LG5CutoffValue_ISig_4 3000;
BA_REL_ "GenSigFirstTimeoutTime" BU_SG_REL_ VCM SG_ 1362 Cur_LG6CutoffValue_ISig_4 12000;
BA_REL_ "GenSigTimeoutTime" BU_SG_REL_ VCM SG_ 1362 Cur_LG6CutoffValue_ISig_4 3000;
BA_REL_ "GenSigFirstTimeoutTime" BU_SG_REL_ VCM SG_ 1362 Cur_LG2CutoffValue_ISig_4 12000;
BA_REL_ "GenSigTimeoutTime" BU_SG_REL_ VCM SG_ 1362 Cur_LG2CutoffValue_ISig_4 3000;
BA_REL_ "GenSigFirstTimeoutTime" BU_SG_REL_ VCM SG_ 1362 Cur_LG1CutoffValue_ISig_4 12000;
BA_REL_ "GenSigTimeoutTime" BU_SG_REL_ VCM SG_ 1362 Cur_LG1CutoffValue_ISig_4 3000;
BA_REL_ "GenSigFirstTimeoutTime" BU_SG_REL_ VCM SG_ 1362 Cur_LG4CutoffValue_ISig_4 12000;
BA_REL_ "GenSigTimeoutTime" BU_SG_REL_ VCM SG_ 1362 Cur_LG4CutoffValue_ISig_4 3000;
BA_REL_ "GenSigFirstTimeoutTime" BU_SG_REL_ VCM SG_ 1362 Cur_LG3CutoffValue_ISig_4 12000;
BA_REL_ "GenSigTimeoutTime" BU_SG_REL_ VCM SG_ 1362 Cur_LG3CutoffValue_ISig_4 3000;
BA_REL_ "GenSigFirstTimeoutTime" BU_SG_REL_ VCM SG_ 1444 CrankDiagInfo4_1 24000;
BA_REL_ "GenSigTimeoutTime" BU_SG_REL_ VCM SG_ 1444 CrankDiagInfo4_1 6000;
BA_REL_ "GenSigFirstTimeoutTime" BU_SG_REL_ VCM SG_ 1444 CrankDiagInfo3_1 24000;
BA_REL_ "GenSigTimeoutTime" BU_SG_REL_ VCM SG_ 1444 CrankDiagInfo3_1 6000;
BA_REL_ "GenSigFirstTimeoutTime" BU_SG_REL_ VCM SG_ 1444 BatteryCapacityGrpAck_Pos3 24000;
BA_REL_ "GenSigTimeoutTime" BU_SG_REL_ VCM SG_ 1444 BatteryCapacityGrpAck_Pos3 6000;
BA_REL_ "GenSigFirstTimeoutTime" BU_SG_REL_ VCM SG_ 1444 CrankDiagInfo2_1 24000;
BA_REL_ "GenSigTimeoutTime" BU_SG_REL_ VCM SG_ 1444 CrankDiagInfo2_1 6000;
BA_REL_ "GenSigFirstTimeoutTime" BU_SG_REL_ VCM SG_ 1444 BatteryCapacityGrpAck_Pos2 24000;
BA_REL_ "GenSigTimeoutTime" BU_SG_REL_ VCM SG_ 1444 BatteryCapacityGrpAck_Pos2 6000;
BA_REL_ "GenSigFirstTimeoutTime" BU_SG_REL_ VCM SG_ 1444 BatteryCapacityGrpAck_Pos1 24000;
BA_REL_ "GenSigTimeoutTime" BU_SG_REL_ VCM SG_ 1444 BatteryCapacityGrpAck_Pos1 6000;
BA_REL_ "GenSigFirstTimeoutTime" BU_SG_REL_ VCM SG_ 1444 CrankDiagInfo1_1 24000;
BA_REL_ "GenSigTimeoutTime" BU_SG_REL_ VCM SG_ 1444 CrankDiagInfo1_1 6000;
BA_REL_ "GenSigFirstTimeoutTime" BU_SG_REL_ VCM SG_ 1471 BatterySOHCapa1_1 24000;
BA_REL_ "GenSigTimeoutTime" BU_SG_REL_ VCM SG_ 1471 BatterySOHCapa1_1 6000;
BA_REL_ "GenSigFirstTimeoutTime" BU_SG_REL_ VCM SG_ 1471 BatterySOCTrustLevel_stat1_1 24000;
BA_REL_ "GenSigTimeoutTime" BU_SG_REL_ VCM SG_ 1471 BatterySOCTrustLevel_stat1_1 6000;
BA_REL_ "GenSigFirstTimeoutTime" BU_SG_REL_ VCM SG_ 1471 EndOfDischargeStatus1_1 24000;
BA_REL_ "GenSigTimeoutTime" BU_SG_REL_ VCM SG_ 1471 EndOfDischargeStatus1_1 6000;
BA_REL_ "GenSigFirstTimeoutTime" BU_SG_REL_ VCM SG_ 1471 DeepDischargestatus_1 24000;
BA_REL_ "GenSigTimeoutTime" BU_SG_REL_ VCM SG_ 1471 DeepDischargestatus_1 6000;
BA_REL_ "GenSigFirstTimeoutTime" BU_SG_REL_ VCM SG_ 1471 BatteryEndOfCharge_ISig_4 24000;
BA_REL_ "GenSigTimeoutTime" BU_SG_REL_ VCM SG_ 1471 BatteryEndOfCharge_ISig_4 6000;
BA_REL_ "GenSigFirstTimeoutTime" BU_SG_REL_ VCM SG_ 1471 BatteryExchangeDetect_1 24000;
BA_REL_ "GenSigTimeoutTime" BU_SG_REL_ VCM SG_ 1471 BatteryExchangeDetect_1 6000;
BA_REL_ "GenSigFirstTimeoutTime" BU_SG_REL_ VCM SG_ 1471 BatterySOHTrustLevel_stat1_1 24000;
BA_REL_ "GenSigTimeoutTime" BU_SG_REL_ VCM SG_ 1471 BatterySOHTrustLevel_stat1_1 6000;
BA_REL_ "GenSigFirstTimeoutTime" BU_SG_REL_ VCM SG_ 1471 Endofchargestatus1_1 24000;
BA_REL_ "GenSigTimeoutTime" BU_SG_REL_ VCM SG_ 1471 Endofchargestatus1_1 6000;
BA_REL_ "GenSigFirstTimeoutTime" BU_SG_REL_ VCM SG_ 1471 BatterySOHPowerTrustLevel1_1 24000;
BA_REL_ "GenSigTimeoutTime" BU_SG_REL_ VCM SG_ 1471 BatterySOHPowerTrustLevel1_1 6000;
BA_REL_ "GenSigFirstTimeoutTime" BU_SG_REL_ VCM SG_ 1471 BatteryTempCo_1 24000;
BA_REL_ "GenSigTimeoutTime" BU_SG_REL_ VCM SG_ 1471 BatteryTempCo_1 6000;
BA_REL_ "GenSigFirstTimeoutTime" BU_SG_REL_ VCM SG_ 1471 BatterySOHPower1_1 24000;
BA_REL_ "GenSigTimeoutTime" BU_SG_REL_ VCM SG_ 1471 BatterySOHPower1_1 6000;
BA_REL_ "GenSigFirstTimeoutTime" BU_SG_REL_ VCM SG_ 1471 BatteryReconnectionDetect_1 24000;
BA_REL_ "GenSigTimeoutTime" BU_SG_REL_ VCM SG_ 1471 BatteryReconnectionDetect_1 6000;
BA_REL_ "GenSigFirstTimeoutTime" BU_SG_REL_ VCM SG_ 1471 BatterySoCcrankLimit1_1 24000;
BA_REL_ "GenSigTimeoutTime" BU_SG_REL_ VCM SG_ 1471 BatterySoCcrankLimit1_1 6000;
BA_REL_ "GenSigFirstTimeoutTime" BU_SG_REL_ VCM SG_ 1469 WhCounterCharge_1 24000;
BA_REL_ "GenSigTimeoutTime" BU_SG_REL_ VCM SG_ 1469 WhCounterCharge_1 6000;
BA_REL_ "GenSigFirstTimeoutTime" BU_SG_REL_ VCM SG_ 1469 HighCurrentIR1_1 24000;
BA_REL_ "GenSigTimeoutTime" BU_SG_REL_ VCM SG_ 1469 HighCurrentIR1_1 6000;
BA_REL_ "GenSigFirstTimeoutTime" BU_SG_REL_ VCM SG_ 1469 WhCounterDischarge_1 24000;
BA_REL_ "GenSigTimeoutTime" BU_SG_REL_ VCM SG_ 1469 WhCounterDischarge_1 6000;
BA_REL_ "GenSigFirstTimeoutTime" BU_SG_REL_ VCM SG_ 1467 WhCounterCharge_1A 24000;
BA_REL_ "GenSigTimeoutTime" BU_SG_REL_ VCM SG_ 1467 WhCounterCharge_1A 6000;
BA_REL_ "GenSigFirstTimeoutTime" BU_SG_REL_ VCM SG_ 1467 HighCurrentIR1_1A 24000;
BA_REL_ "GenSigTimeoutTime" BU_SG_REL_ VCM SG_ 1467 HighCurrentIR1_1A 6000;
BA_REL_ "GenSigFirstTimeoutTime" BU_SG_REL_ VCM SG_ 1467 WhCounterDischarge_1A 24000;
BA_REL_ "GenSigTimeoutTime" BU_SG_REL_ VCM SG_ 1467 WhCounterDischarge_1A 6000;
BA_REL_ "GenSigFirstTimeoutTime" BU_SG_REL_ VCM SG_ 1465 HighCurrentIR1_1B 24000;
BA_REL_ "GenSigTimeoutTime" BU_SG_REL_ VCM SG_ 1465 HighCurrentIR1_1B 6000;
BA_REL_ "GenSigFirstTimeoutTime" BU_SG_REL_ VCM SG_ 1465 WhCounterCharge_1B 24000;
BA_REL_ "GenSigTimeoutTime" BU_SG_REL_ VCM SG_ 1465 WhCounterCharge_1B 6000;
BA_REL_ "GenSigFirstTimeoutTime" BU_SG_REL_ VCM SG_ 1465 WhCounterDischarge_1B 24000;
BA_REL_ "GenSigTimeoutTime" BU_SG_REL_ VCM SG_ 1465 WhCounterDischarge_1B 6000;
BA_REL_ "GenSigFirstTimeoutTime" BU_SG_REL_ VCM SG_ 1463 WhCounterDischarge_2A 24000;
BA_REL_ "GenSigTimeoutTime" BU_SG_REL_ VCM SG_ 1463 WhCounterDischarge_2A 6000;
BA_REL_ "GenSigFirstTimeoutTime" BU_SG_REL_ VCM SG_ 1463 HighCurrentIR1_2A 24000;
BA_REL_ "GenSigTimeoutTime" BU_SG_REL_ VCM SG_ 1463 HighCurrentIR1_2A 6000;
BA_REL_ "GenSigFirstTimeoutTime" BU_SG_REL_ VCM SG_ 1463 WhCounterCharge_2A 24000;
BA_REL_ "GenSigTimeoutTime" BU_SG_REL_ VCM SG_ 1463 WhCounterCharge_2A 6000;
VAL_ 517 FrontProhibitControlRequest 3 "Request_NotAvailable" 2 "Request_Error" 1 "Request_RequestActive" 0 "Request_NotRequested" ;
VAL_ 517 RampLevelStorageAck_ISig_4 3 "StorageAck_NotAvaiable" 2 "StorageAck_Error" 1 "StorageAck_ChangeAcknowledged" 0 "StorageAck_TakeNoAction" ;
VAL_ 517 FrontLimpHomeCmd 7 "LimpHomeCmd_NotAvailable" 6 "LimpHomeCmd_Error" 5 "LimpHomeCmd_Spare_01" 4 "LimpHomeCmd_Spare" 3 "LimpHomeCmd_Fill" 2 "LimpHomeCmd_Drain" 1 "LimpHomeCmd_CloseValves" 0 "LimpHomeCmd_Inactive" ;
VAL_ 517 LiftingControlModeRearAxle 3 "InactiveActive_NotAvailable" 2 "InactiveActive_Error" 1 "InactiveActive_Active" 0 "InactiveActive_Inactive" ;
VAL_ 517 LoadDistributionChangeACK_ISig_4 7 "LoadDistributionChangeACK_NotAvailable" 6 "LoadDistributionChangeACK_Error" 5 "LoadDistributionChangeACK_SystemDeniedVersatile" 4 "LoadDistributionChangeACK_Reserved_2" 3 "LoadDistributionChangeACK_DeniedDueToDisengagedDifflock" 2 "LoadDistributionChangeACK_LoadShiftDeniedFALIMOverload" 1 "LoadDistributionChangeACK_ChangeAcknowledged" 0 "LoadDistributionChangeACK_NoAction" ;
VAL_ 517 ECSStandbyAllowed_ISig_4 3 "FalseTrue_NotAvaiable" 2 "FalseTrue_Error" 1 "FalseTrue_True" 0 "FalseTrue_False" ;
VAL_ 517 LiftAxle2LiftFuncSelected_ISig_4 7 "LiftAxleLiftAutoFuncSelected_NotAvailable" 6 "LiftAxleLiftAutoFuncSelected_Error" 5 "LiftAxleLiftAutoFuncSelected_Reserved" 4 "LiftAxleLiftAutoFuncSelected_UnlimitedLift" 3 "LiftAxleLiftAutoFuncSelected_LiftOverload" 2 "LiftAxleLiftAutoFuncSelected_LiftPlus30" 1 "LiftAxleLiftAutoFuncSelected_Lift" 0 "LiftAxleLiftAutoFuncSelected_NoLift" ;
VAL_ 517 LiftAxle2UpRequestACK_ISig_4 7 "LiftAxleUpRequestACK_NotAvailable" 6 "LiftAxleUpRequestACK_Error" 5 "LiftAxleUpRequestACK_SystemDeniedVersatile" 4 "LiftAxleUpRequestACK_LiftDeniedPBrakeActive" 3 "LiftAxleUpRequestACK_LiftDeniedRearOverload" 2 "LiftAxleUpRequestACK_LiftDeniedFrontOverload" 1 "LiftAxleUpRequestACK_ChangeAcknowledged" 0 "LiftAxleUpRequestACK_NoAction" ;
VAL_ 517 ProhibitControlStatus_ISig_4 3 "InactiveActive_NotAvailable" 2 "InactiveActive_Error" 1 "InactiveActive_Active" 0 "InactiveActive_Inactive" ;
VAL_ 517 RampLevelStatus_ISig_4 15 "RampLevelStatus_NotAvaiable" 14 "RampLevelStatus_ErrorIndicator" 13 "RampLevelStatus_NotDefined_05" 12 "RampLevelStatus_NotDefined_04" 11 "RampLevelStatus_NotDefined_03" 10 "RampLevelStatus_NotDefined_02" 9 "RampLevelStatus_NotDefined_01" 8 "RampLevelStatus_NotDefined" 7 "RampLevelStatus_RampLevelM7" 6 "RampLevelStatus_RampLevelM6" 5 "RampLevelStatus_RampLevelM5" 4 "RampLevelStatus_RampLevelM4" 3 "RampLevelStatus_RampLevelM3" 2 "RampLevelStatus_RampLevelM2" 1 "RampLevelStatus_RampLevelM1" 0 "RampLevelStatus_Inactive" ;
VAL_ 517 StopLevelChangeAck_ISig_4 3 "StopLevelChangeStatus_NotAvailable" 2 "StopLevelChangeStatus_ErrorIndicator" 1 "StopLevelChangeStatus_LevelChangedStopped" 0 "StopLevelChangeStatus_NoStopRequest" ;
VAL_ 517 LiftAxle2LowerACK_ISig_4 7 "LiftAxle2LowerACK_NotAvailable" 6 "LiftAxle2LowerACK_Error" 5 "LiftAxle2LowerACK_SystemDeniedVersatile" 4 "LiftAxle2LowerACK_Spare_01" 3 "LiftAxle2LowerACK_Spare" 2 "LiftAxle2LowerACK_LowerDeniedRAS_EC" 1 "LiftAxle2LowerACK_ChangeAcknowledged" 0 "LiftAxle2LowerACK_NoAction" ;
VAL_ 517 RideHeightStorageAck_ISig_4 3 "StorageAck_NotAvaiable" 2 "StorageAck_Error" 1 "StorageAck_ChangeAcknowledged" 0 "StorageAck_TakeNoAction" ;
VAL_ 517 FrontParkBrakeOverrideCommand 3 "FrontParkBrakeOverrideCommand_NotAvailable" 2 "FrontParkBrakeOverrideCommand_ErrorIndicator" 1 "FrontParkBrakeOverrideCommand_FrontParkBrakeOverrideCommand" 0 "FrontParkBrakeOverrideCommand_NoCommand" ;
VAL_ 517 RideHeightOutsideTargetRange_ISi 7 "HeightOutsideTargetRange_NotAvailable" 6 "HeightOutsideTargetRange_Error" 5 "HeightOutsideTargetRange_NotDefined_02" 4 "HeightOutsideTargetRange_NotDefined_01" 3 "HeightOutsideTargetRange_NotDefined" 2 "HeightOutsideTargetRange_ToHigh" 1 "HeightOutsideTargetRange_ToLow" 0 "HeightOutsideTargetRange_Inactive" ;
VAL_ 517 DisableMechFaultDctnFr_rqst 3 "FalseTrue_NotAvaiable" 2 "FalseTrue_Error" 1 "FalseTrue_True" 0 "FalseTrue_False" ;
VAL_ 517 FogLamp_Rear_Status 3 "InactiveActive_NotAvailable" 2 "InactiveActive_Error" 1 "InactiveActive_Active" 0 "InactiveActive_Inactive" ;
VAL_ 517 LiftingControlModeFrontAxle 3 "InactiveActive_NotAvailable" 2 "InactiveActive_Error" 1 "InactiveActive_Active" 0 "InactiveActive_Inactive" ;
VAL_ 517 LiftAxle1UpRequestACK_ISig_4 7 "LiftAxleUpRequestACK_NotAvailable" 6 "LiftAxleUpRequestACK_Error" 5 "LiftAxleUpRequestACK_SystemDeniedVersatile" 4 "LiftAxleUpRequestACK_LiftDeniedPBrakeActive" 3 "LiftAxleUpRequestACK_LiftDeniedRearOverload" 2 "LiftAxleUpRequestACK_LiftDeniedFrontOverload" 1 "LiftAxleUpRequestACK_ChangeAcknowledged" 0 "LiftAxleUpRequestACK_NoAction" ;
VAL_ 517 LiftAxle1LiftFuncSelected_ISig_4 7 "LiftAxleLiftAutoFuncSelected_NotAvailable" 6 "LiftAxleLiftAutoFuncSelected_Error" 5 "LiftAxleLiftAutoFuncSelected_Reserved" 4 "LiftAxleLiftAutoFuncSelected_UnlimitedLift" 3 "LiftAxleLiftAutoFuncSelected_LiftOverload" 2 "LiftAxleLiftAutoFuncSelected_LiftPlus30" 1 "LiftAxleLiftAutoFuncSelected_Lift" 0 "LiftAxleLiftAutoFuncSelected_NoLift" ;
VAL_ 517 RearAxleInBumperRange_ISig_4 3 "AxleInBumperRange_NotAvailable" 2 "AxleInBumperRange_ErrorIndicator" 1 "AxleInBumperRange_ActualLevelWithinBumperRange" 0 "AxleInBumperRange_ActualLevelOutOfBumperRange" ;
VAL_ 1339 HeadlampFan_stat_ISig_4 7 "LampFanTestStat_NotAvailable" 6 "LampFanTestStat_Error" 5 "LampFanTestStat_Spare3" 4 "LampFanTestStat_Spare2" 3 "LampFanTestStat_Spare1" 2 "LampFanTestStat_FanTestedNOK" 1 "LampFanTestStat_FanTestedOK" 0 "LampFanTestStat_NotTested" ;
VAL_ 1339 FrontConspicLamp_stat_HiRight_IS 7 "LampCheck_stat_NotAvailable" 6 "LampCheck_stat_Error" 5 "LampCheck_stat_Spare_02" 4 "LampCheck_stat_Spare_01" 3 "LampCheck_stat_Spare" 2 "LampCheck_stat_TestedLampNOK" 1 "LampCheck_stat_TestedLampOK" 0 "LampCheck_stat_NotTested" ;
VAL_ 1339 FrontConspicLamp_stat_LoRight_IS 7 "LampCheck_stat_NotAvailable" 6 "LampCheck_stat_Error" 5 "LampCheck_stat_Spare_02" 4 "LampCheck_stat_Spare_01" 3 "LampCheck_stat_Spare" 2 "LampCheck_stat_TestedLampNOK" 1 "LampCheck_stat_TestedLampOK" 0 "LampCheck_stat_NotTested" ;
VAL_ 1339 FrontConspicLamp_stat_HiLeft_ISi 7 "LampCheck_stat_NotAvailable" 6 "LampCheck_stat_Error" 5 "LampCheck_stat_Spare_02" 4 "LampCheck_stat_Spare_01" 3 "LampCheck_stat_Spare" 2 "LampCheck_stat_TestedLampNOK" 1 "LampCheck_stat_TestedLampOK" 0 "LampCheck_stat_NotTested" ;
VAL_ 1339 FrontConspicLamp_stat_LoLeft_ISi 7 "LampCheck_stat_NotAvailable" 6 "LampCheck_stat_Error" 5 "LampCheck_stat_Spare_02" 4 "LampCheck_stat_Spare_01" 3 "LampCheck_stat_Spare" 2 "LampCheck_stat_TestedLampNOK" 1 "LampCheck_stat_TestedLampOK" 0 "LampCheck_stat_NotTested" ;
VAL_ 1243 MainBeamLEDStatusRight_ISig_4 7 "LampCheck_stat_NotAvailable" 6 "LampCheck_stat_Error" 5 "LampCheck_stat_Spare_02" 4 "LampCheck_stat_Spare_01" 3 "LampCheck_stat_Spare" 2 "LampCheck_stat_TestedLampNOK" 1 "LampCheck_stat_TestedLampOK" 0 "LampCheck_stat_NotTested" ;
VAL_ 1243 DeicingBulb_Stat_ISig_4 7 "DeicingBulb_Stat_NotAvailable" 6 "DeicingBulb_Stat_Error" 5 "DeicingBulb_Stat_Spare2" 4 "DeicingBulb_Stat_Spare1" 3 "DeicingBulb_Stat_BothLampsNOK" 2 "DeicingBulb_Stat_AtleastOneLampOK" 1 "DeicingBulb_Stat_BothLampsOK" 0 "DeicingBulb_Stat_NotTested" ;
VAL_ 1243 DeicingFunction_Stat_ISig_4 7 "DeicingFunction_Stat_NotAvailable" 6 "DeicingFunction_Stat_Spare2" 5 "DeicingFunction_Stat_Spare1" 4 "DeicingFunction_Stat_Fault" 3 "DeicingFunction_Stat_Deactivated" 2 "DeicingFunction_Stat_Ongoing" 1 "DeicingFunction_Stat_Activated" 0 "DeicingFunction_Stat_NotTested" ;
VAL_ 1243 MainBeamLEDStatusLeft_ISig_4 7 "LampCheck_stat_NotAvailable" 6 "LampCheck_stat_Error" 5 "LampCheck_stat_Spare_02" 4 "LampCheck_stat_Spare_01" 3 "LampCheck_stat_Spare" 2 "LampCheck_stat_TestedLampNOK" 1 "LampCheck_stat_TestedLampOK" 0 "LampCheck_stat_NotTested" ;
VAL_ 952 DRLLamp_stat_ISig_4 7 "LampCheckLeftRight_stat_NotAvailable" 6 "LampCheckLeftRight_stat_Error" 5 "LampCheckLeftRight_stat_Spare" 4 "LampCheckLeftRight_stat_TestedLeftAndRightLampNOK" 3 "LampCheckLeftRight_stat_TestedRightLampNOK" 2 "LampCheckLeftRight_stat_TestedLeftLampNOK" 1 "LampCheckLeftRight_stat_TestedLampOK" 0 "LampCheckLeftRight_stat_NotTested" ;
VAL_ 952 FogLamp_Front_Status 3 "InactiveActive_NotAvailable" 2 "InactiveActive_Error" 1 "InactiveActive_Active" 0 "InactiveActive_Inactive" ;
VAL_ 952 DirIndSideLamp1_stat 7 "LampCheckLeftRight_stat_NotAvailable" 6 "LampCheckLeftRight_stat_Error" 5 "LampCheckLeftRight_stat_Spare" 4 "LampCheckLeftRight_stat_TestedLeftAndRightLampNOK" 3 "LampCheckLeftRight_stat_TestedRightLampNOK" 2 "LampCheckLeftRight_stat_TestedLeftLampNOK" 1 "LampCheckLeftRight_stat_TestedLampOK" 0 "LampCheckLeftRight_stat_NotTested" ;
VAL_ 952 PositionLightLamp_stat_ISig_4 7 "LampCheckLeftRight_stat_NotAvailable" 6 "LampCheckLeftRight_stat_Error" 5 "LampCheckLeftRight_stat_Spare" 4 "LampCheckLeftRight_stat_TestedLeftAndRightLampNOK" 3 "LampCheckLeftRight_stat_TestedRightLampNOK" 2 "LampCheckLeftRight_stat_TestedLeftLampNOK" 1 "LampCheckLeftRight_stat_TestedLampOK" 0 "LampCheckLeftRight_stat_NotTested" ;
VAL_ 952 DippedBeamLamp_stat_ISig_4 7 "LampCheckLeftRight_stat_NotAvailable" 6 "LampCheckLeftRight_stat_Error" 5 "LampCheckLeftRight_stat_Spare" 4 "LampCheckLeftRight_stat_TestedLeftAndRightLampNOK" 3 "LampCheckLeftRight_stat_TestedRightLampNOK" 2 "LampCheckLeftRight_stat_TestedLeftLampNOK" 1 "LampCheckLeftRight_stat_TestedLampOK" 0 "LampCheckLeftRight_stat_NotTested" ;
VAL_ 952 MainBeamLamp_stat_ISig_4 7 "LampCheckLeftRight_stat_NotAvailable" 6 "LampCheckLeftRight_stat_Error" 5 "LampCheckLeftRight_stat_Spare" 4 "LampCheckLeftRight_stat_TestedLeftAndRightLampNOK" 3 "LampCheckLeftRight_stat_TestedRightLampNOK" 2 "LampCheckLeftRight_stat_TestedLeftLampNOK" 1 "LampCheckLeftRight_stat_TestedLampOK" 0 "LampCheckLeftRight_stat_NotTested" ;
VAL_ 952 StaticCornerLightLamp_stat_ISig_ 7 "LampCheckLeftRight_stat_NotAvailable" 6 "LampCheckLeftRight_stat_Error" 5 "LampCheckLeftRight_stat_Spare" 4 "LampCheckLeftRight_stat_TestedLeftAndRightLampNOK" 3 "LampCheckLeftRight_stat_TestedRightLampNOK" 2 "LampCheckLeftRight_stat_TestedLeftLampNOK" 1 "LampCheckLeftRight_stat_TestedLampOK" 0 "LampCheckLeftRight_stat_NotTested" ;
VAL_ 952 AuxLamp_Front_Status 3 "InactiveActive_NotAvailable" 2 "InactiveActive_Error" 1 "InactiveActive_Active" 0 "InactiveActive_Inactive" ;
VAL_ 952 AuxFogLightLamp_stat_ISig_4 7 "LampCheckLeftRight_stat_NotAvailable" 6 "LampCheckLeftRight_stat_Error" 5 "LampCheckLeftRight_stat_Spare" 4 "LampCheckLeftRight_stat_TestedLeftAndRightLampNOK" 3 "LampCheckLeftRight_stat_TestedRightLampNOK" 2 "LampCheckLeftRight_stat_TestedLeftLampNOK" 1 "LampCheckLeftRight_stat_TestedLampOK" 0 "LampCheckLeftRight_stat_NotTested" ;
VAL_ 952 ExtraMainBeamLamp_stat_ISig_4 7 "LampCheckLeftRight_stat_NotAvailable" 6 "LampCheckLeftRight_stat_Error" 5 "LampCheckLeftRight_stat_Spare" 4 "LampCheckLeftRight_stat_TestedLeftAndRightLampNOK" 3 "LampCheckLeftRight_stat_TestedRightLampNOK" 2 "LampCheckLeftRight_stat_TestedLeftLampNOK" 1 "LampCheckLeftRight_stat_TestedLampOK" 0 "LampCheckLeftRight_stat_NotTested" ;
VAL_ 952 FogLightFrontLamp_stat_ISig_4 7 "LampCheck_stat_NotAvailable" 6 "LampCheck_stat_Error" 5 "LampCheck_stat_Spare_02" 4 "LampCheck_stat_Spare_01" 3 "LampCheck_stat_Spare" 2 "LampCheck_stat_TestedLampNOK" 1 "LampCheck_stat_TestedLampOK" 0 "LampCheck_stat_NotTested" ;
VAL_ 952 DirInd_Front_Status_ISig_4 7 "DirIndFaultStatus_NotAvailable" 6 "DirIndFaultStatus_Error" 5 "DirIndFaultStatus_SpareValue_01" 4 "DirIndFaultStatus_SpareValue" 3 "DirIndFaultStatus_BothLeftAndRightDirectionIndicatorsFault" 2 "DirIndFaultStatus_RightDirectionIndicatorLampFault" 1 "DirIndFaultStatus_LeftDirectionIndicatorLampFault" 0 "DirIndFaultStatus_NoError" ;
VAL_ 952 ChassiInstepLightsLamp_stat_ISig 7 "LampCheck_stat_NotAvailable" 6 "LampCheck_stat_Error" 5 "LampCheck_stat_Spare_02" 4 "LampCheck_stat_Spare_01" 3 "LampCheck_stat_Spare" 2 "LampCheck_stat_TestedLampNOK" 1 "LampCheck_stat_TestedLampOK" 0 "LampCheck_stat_NotTested" ;
VAL_ 952 WasherFluidLevel 7 "WasherFluidLevel_NotAvailable" 6 "WasherFluidLevel_ErrorIndicator" 5 "WasherFluidLevel_Spare_02" 4 "WasherFluidLevel_Spare_01" 3 "WasherFluidLevel_Spare" 2 "WasherFluidLevel_Level2" 1 "WasherFluidLevel_Level1" 0 "WasherFluidLevel_Level0" ;
VAL_ 1511 Trailer5TireInfoISO_PresSuff_ISi 3 "TPMISOPresSuff_NotAvailable" 2 "TPMISOPresSuff_Error" 1 "TPMISOPresSuff_TirePressureSufficient" 0 "TPMISOPresSuff_TirePressureInsufficient" ;
VAL_ 1511 Trailer5TireInfoISO_PowerSupply_ 3 "TPMISOPowerSupply_NotAvailable" 2 "TPMISOPowerSupply_Error" 1 "TPMISOPowerSupply_SufficientPowerSupply" 0 "TPMISOPowerSupply_InsufficientPowerSupply" ;
VAL_ 1511 Trailer5TireInfoISO_Warning_ISig 7 "TPMPressureWarning_NotAvailable" 6 "TPMPressureWarning_Error" 5 "TPMPressureWarning_Spare" 4 "TPMPressureWarning_ExtremeUnderPressure" 3 "TPMPressureWarning_UnderPressure" 2 "TPMPressureWarning_NoWarningPressure" 1 "TPMPressureWarning_OverPressure" 0 "TPMPressureWarning_ExtremeOverPressure" ;
VAL_ 1511 Trailer5TireInfoISO_Active_ISig_ 3 "TPMTireActive_NotAvailable" 2 "TPMTireActive_Error" 1 "TPMTireActive_TireActivePositioned" 0 "TPMTireActive_TireNotActive" ;
VAL_ 1509 Trailer4TireInfoISO_PresSuff_ISi 3 "TPMISOPresSuff_NotAvailable" 2 "TPMISOPresSuff_Error" 1 "TPMISOPresSuff_TirePressureSufficient" 0 "TPMISOPresSuff_TirePressureInsufficient" ;
VAL_ 1509 Trailer4TireInfoISO_PowerSupply_ 3 "TPMISOPowerSupply_NotAvailable" 2 "TPMISOPowerSupply_Error" 1 "TPMISOPowerSupply_SufficientPowerSupply" 0 "TPMISOPowerSupply_InsufficientPowerSupply" ;
VAL_ 1509 Trailer4TireInfoISO_Warning_ISig 7 "TPMPressureWarning_NotAvailable" 6 "TPMPressureWarning_Error" 5 "TPMPressureWarning_Spare" 4 "TPMPressureWarning_ExtremeUnderPressure" 3 "TPMPressureWarning_UnderPressure" 2 "TPMPressureWarning_NoWarningPressure" 1 "TPMPressureWarning_OverPressure" 0 "TPMPressureWarning_ExtremeOverPressure" ;
VAL_ 1509 Trailer4TireInfoISO_Active_ISig_ 3 "TPMTireActive_NotAvailable" 2 "TPMTireActive_Error" 1 "TPMTireActive_TireActivePositioned" 0 "TPMTireActive_TireNotActive" ;
VAL_ 1508 Trailer3TireInfoISO_Active_ISig_ 3 "TPMTireActive_NotAvailable" 2 "TPMTireActive_Error" 1 "TPMTireActive_TireActivePositioned" 0 "TPMTireActive_TireNotActive" ;
VAL_ 1508 Trailer3TireInfoISO_Warning_ISig 7 "TPMPressureWarning_NotAvailable" 6 "TPMPressureWarning_Error" 5 "TPMPressureWarning_Spare" 4 "TPMPressureWarning_ExtremeUnderPressure" 3 "TPMPressureWarning_UnderPressure" 2 "TPMPressureWarning_NoWarningPressure" 1 "TPMPressureWarning_OverPressure" 0 "TPMPressureWarning_ExtremeOverPressure" ;
VAL_ 1508 Trailer3TireInfoISO_PowerSupply_ 3 "TPMISOPowerSupply_NotAvailable" 2 "TPMISOPowerSupply_Error" 1 "TPMISOPowerSupply_SufficientPowerSupply" 0 "TPMISOPowerSupply_InsufficientPowerSupply" ;
VAL_ 1508 Trailer3TireInfoISO_PresSuff_ISi 3 "TPMISOPresSuff_NotAvailable" 2 "TPMISOPresSuff_Error" 1 "TPMISOPresSuff_TirePressureSufficient" 0 "TPMISOPresSuff_TirePressureInsufficient" ;
VAL_ 1232 TrailerCommunicationType_ISig_4 7 "TrailerCommunicationType_NotAvailable" 6 "TrailerCommunicationType_Error" 5 "TrailerCommunicationType_Spare3" 4 "TrailerCommunicationType_Spare2" 3 "TrailerCommunicationType_Spare1" 2 "TrailerCommunicationType_SAE_J2497_Communication" 1 "TrailerCommunicationType_ISO_11992_2_Communication" 0 "TrailerCommunicationType_NoCommunication" ;
VAL_ 1501 Trailer2TireInfoISO_PowerSupply_ 3 "TPMISOPowerSupply_NotAvailable" 2 "TPMISOPowerSupply_Error" 1 "TPMISOPowerSupply_SufficientPowerSupply" 0 "TPMISOPowerSupply_InsufficientPowerSupply" ;
VAL_ 1501 Trailer2TireInfoISO_PresSuff_ISi 3 "TPMISOPresSuff_NotAvailable" 2 "TPMISOPresSuff_Error" 1 "TPMISOPresSuff_TirePressureSufficient" 0 "TPMISOPresSuff_TirePressureInsufficient" ;
VAL_ 1501 Trailer2TireInfoISO_Warning_ISig 7 "TPMPressureWarning_NotAvailable" 6 "TPMPressureWarning_Error" 5 "TPMPressureWarning_Spare" 4 "TPMPressureWarning_ExtremeUnderPressure" 3 "TPMPressureWarning_UnderPressure" 2 "TPMPressureWarning_NoWarningPressure" 1 "TPMPressureWarning_OverPressure" 0 "TPMPressureWarning_ExtremeOverPressure" ;
VAL_ 1501 Trailer2TireInfoISO_Active_ISig_ 3 "TPMTireActive_NotAvailable" 2 "TPMTireActive_Error" 1 "TPMTireActive_TireActivePositioned" 0 "TPMTireActive_TireNotActive" ;
VAL_ 1498 Trailer1TireInfoISO_Active_ISig_ 3 "TPMTireActive_NotAvailable" 2 "TPMTireActive_Error" 1 "TPMTireActive_TireActivePositioned" 0 "TPMTireActive_TireNotActive" ;
VAL_ 1498 Trailer1TireInfoISO_Warning_ISig 7 "TPMPressureWarning_NotAvailable" 6 "TPMPressureWarning_Error" 5 "TPMPressureWarning_Spare" 4 "TPMPressureWarning_ExtremeUnderPressure" 3 "TPMPressureWarning_UnderPressure" 2 "TPMPressureWarning_NoWarningPressure" 1 "TPMPressureWarning_OverPressure" 0 "TPMPressureWarning_ExtremeOverPressure" ;
VAL_ 1498 Trailer1TireInfoISO_PowerSupply_ 3 "TPMISOPowerSupply_NotAvailable" 2 "TPMISOPowerSupply_Error" 1 "TPMISOPowerSupply_SufficientPowerSupply" 0 "TPMISOPowerSupply_InsufficientPowerSupply" ;
VAL_ 1498 Trailer1TireInfoISO_PresSuff_ISi 3 "TPMISOPresSuff_NotAvailable" 2 "TPMISOPresSuff_Error" 1 "TPMISOPresSuff_TirePressureSufficient" 0 "TPMISOPresSuff_TirePressureInsufficient" ;
VAL_ 386 VDCBrakeLightRequest_ISig_4 3 "VDCBrakeLightRequest_DontCareTakeNoAction" 2 "VDCBrakeLightRequest_Reserved" 1 "VDCBrakeLightRequest_TurnBrakeLightON" 0 "VDCBrakeLightRequest_TurnBrakeLightOFF" ;
VAL_ 386 EBSBrakeSwitch_ISig_4 3 "EBSBrakeSwitch_NotAvailable" 2 "EBSBrakeSwitch_Error" 1 "EBSBrakeSwitch_BrakePedalDepressed" 0 "EBSBrakeSwitch_BrakePedalReleased" ;
VAL_ 386 BrakeLightActivationRequest_ISig 3 "OffOn_NotAvailable" 2 "OffOn_Error" 1 "OffOn_On" 0 "OffOn_Off" ;
VAL_ 824 Trailer1TractionHelp_ISig_4 3 "InactiveActive_NotAvailable" 2 "InactiveActive_Error" 1 "InactiveActive_Active" 0 "InactiveActive_Inactive" ;
VAL_ 824 TrailerBrake_Stat_ISig_4 3 "InactiveActive_NotAvailable" 2 "InactiveActive_Error" 1 "InactiveActive_Active" 0 "InactiveActive_Inactive" ;
VAL_ 824 SplitBoxDiffLockActvnFuncReq_ISi 3 "DisengageEngage_NotAvailable" 2 "DisengageEngage_Error" 1 "DisengageEngage_Engage" 0 "DisengageEngage_Disengage" ;
VAL_ 824 BrakingSystemPressureLim_rqst_IS 3 "Request_NotAvailable" 2 "Request_Error" 1 "Request_RequestActive" 0 "Request_NotRequested" ;
VAL_ 824 TagLiftAxleLoweringInhibit 3 "InhibitStatus_NotAvailable" 2 "InhibitStatus_Reserved" 1 "InhibitStatus_Inhibited" 0 "InhibitStatus_NotInhibited" ;
VAL_ 824 ScndRrAxlDiffLckActvnFuncReq_ISi 3 "RearAxleDiffLockActvnFuncReq_TakeNoAction" 2 "RearAxleDiffLockActvnFuncReq_Reserved" 1 "RearAxleDiffLockActvnFuncReq_DisengageDifferentialLock" 0 "RearAxleDiffLockActvnFuncReq_EngageDifferentialLock" ;
VAL_ 824 Trailer1LiftAxle1Pos_ISig_4 3 "TrailerLiftAxlePos_NotAvailable" 2 "TrailerLiftAxlePos_Error" 1 "TrailerLiftAxlePos_AxleLifted" 0 "TrailerLiftAxlePos_AxleDown" ;
VAL_ 824 PusherLiftAxleLoweringInhibit_IS 3 "InhibitStatus_NotAvailable" 2 "InhibitStatus_Reserved" 1 "InhibitStatus_Inhibited" 0 "InhibitStatus_NotInhibited" ;
VAL_ 824 StretchBrake_Stat_ISig_4 7 "StretchBrake_Stat_NotAvailable" 6 "StretchBrake_Stat_Error" 5 "StretchBrake_Stat_Spare_02" 4 "StretchBrake_Stat_Spare_01" 3 "StretchBrake_Stat_Spare" 2 "StretchBrake_Stat_Active" 1 "StretchBrake_Stat_Enabled" 0 "StretchBrake_Stat_Disabled" ;
VAL_ 824 Trailer1LiftAxle2Pos_ISig_4 3 "TrailerLiftAxlePos_NotAvailable" 2 "TrailerLiftAxlePos_Error" 1 "TrailerLiftAxlePos_AxleLifted" 0 "TrailerLiftAxlePos_AxleDown" ;
VAL_ 824 TrailerEBSAmberWarning_ISig_4 3 "OffOn_NotAvailable" 2 "OffOn_Error" 1 "OffOn_On" 0 "OffOn_Off" ;
VAL_ 516 EASPusherLiftAxleLoweringInhib 3 "InhibitStatus_NotAvailable" 2 "InhibitStatus_Reserved" 1 "InhibitStatus_Inhibited" 0 "InhibitStatus_NotInhibited" ;
VAL_ 1253 SensorCleaningFluidLevelStatus_I 7 "FluidLevel_NotAvailable" 6 "FluidLevel_Error" 5 "FluidLevel_Spare3" 4 "FluidLevel_Spare2" 3 "FluidLevel_Spare1" 2 "FluidLevel_CriticallyLow" 1 "FluidLevel_Low" 0 "FluidLevel_LevelOK" ;
VAL_ 1362 Cur_EnergySetting_ISig_4 7 "EnergySetting_NotAvailable" 6 "EnergySetting_Error" 5 "EnergySetting_Spare2" 4 "EnergySetting_Spare1" 3 "EnergySetting_Customise" 2 "EnergySetting_PresetLevel2_HighEnergySaving" 1 "EnergySetting_PresetLevel1_EnergySaving" 0 "EnergySetting_OFF" ;
VAL_ 1444 BatteryCapacityGrpAck_Pos3 3 "NokOk_NotAvailable" 2 "NokOk_Error" 1 "NokOk_OK" 0 "NokOk_NOK" ;
VAL_ 1444 BatteryCapacityGrpAck_Pos2 3 "NokOk_NotAvailable" 2 "NokOk_Error" 1 "NokOk_OK" 0 "NokOk_NOK" ;
VAL_ 1444 BatteryCapacityGrpAck_Pos1 3 "NokOk_NotAvailable" 2 "NokOk_Error" 1 "NokOk_OK" 0 "NokOk_NOK" ;
VAL_ 1471 BatterySOCTrustLevel_stat1_1 15 "BatteryTrustLevel_NotAvailable" 14 "BatteryTrustLevel_Error" 13 "BatteryTrustLevel_Spare9" 12 "BatteryTrustLevel_Spare8" 11 "BatteryTrustLevel_Spare7" 10 "BatteryTrustLevel_Spare6" 9 "BatteryTrustLevel_Spare5" 8 "BatteryTrustLevel_Spare4" 7 "BatteryTrustLevel_Spare3" 6 "BatteryTrustLevel_Spare2" 5 "BatteryTrustLevel_Spare1" 4 "BatteryTrustLevel_NominalPlus15PercentAndAbove" 3 "BatteryTrustLevel_NominalPlus10Percent" 2 "BatteryTrustLevel_NominalPlus5Percent" 1 "BatteryTrustLevel_NominalAccuracy" 0 "BatteryTrustLevel_NotInitialized" ;
VAL_ 1471 BatteryEndOfCharge_ISig_4 3 "FalseTrue_NotAvaiable" 2 "FalseTrue_Error" 1 "FalseTrue_True" 0 "FalseTrue_False" ;
VAL_ 1471 BatteryExchangeDetect_1 7 "BatteryExchangeDetectionStat_NotAvailable" 6 "BatteryExchangeDetectionStat_Error" 5 "BatteryExchangeDetectionStat_Spare2" 4 "BatteryExchangeDetectionStat_Spare1" 3 "BatteryExchangeDetectionStat_ExchangeNotDetected" 2 "BatteryExchangeDetectionStat_ExchangeDetected" 1 "BatteryExchangeDetectionStat_AlgorithmRunning" 0 "BatteryExchangeDetectionStat_AlgorithmNotRunning" ;
VAL_ 1471 BatterySOHTrustLevel_stat1_1 15 "BatteryTrustLevel_NotAvailable" 14 "BatteryTrustLevel_Error" 13 "BatteryTrustLevel_Spare9" 12 "BatteryTrustLevel_Spare8" 11 "BatteryTrustLevel_Spare7" 10 "BatteryTrustLevel_Spare6" 9 "BatteryTrustLevel_Spare5" 8 "BatteryTrustLevel_Spare4" 7 "BatteryTrustLevel_Spare3" 6 "BatteryTrustLevel_Spare2" 5 "BatteryTrustLevel_Spare1" 4 "BatteryTrustLevel_NominalPlus15PercentAndAbove" 3 "BatteryTrustLevel_NominalPlus10Percent" 2 "BatteryTrustLevel_NominalPlus5Percent" 1 "BatteryTrustLevel_NominalAccuracy" 0 "BatteryTrustLevel_NotInitialized" ;
VAL_ 1471 BatterySOHPowerTrustLevel1_1 15 "BatteryTrustLevel_NotAvailable" 14 "BatteryTrustLevel_Error" 13 "BatteryTrustLevel_Spare9" 12 "BatteryTrustLevel_Spare8" 11 "BatteryTrustLevel_Spare7" 10 "BatteryTrustLevel_Spare6" 9 "BatteryTrustLevel_Spare5" 8 "BatteryTrustLevel_Spare4" 7 "BatteryTrustLevel_Spare3" 6 "BatteryTrustLevel_Spare2" 5 "BatteryTrustLevel_Spare1" 4 "BatteryTrustLevel_NominalPlus15PercentAndAbove" 3 "BatteryTrustLevel_NominalPlus10Percent" 2 "BatteryTrustLevel_NominalPlus5Percent" 1 "BatteryTrustLevel_NominalAccuracy" 0 "BatteryTrustLevel_NotInitialized" ;
SIG_GROUP_ 1339 FrontConspicLamp_stat_sg_ISig_4 1 : FrontConspicLamp_stat_HiRight_IS FrontConspicLamp_stat_LoRight_IS FrontConspicLamp_stat_HiLeft_ISi FrontConspicLamp_stat_LoLeft_ISi;
SIG_GROUP_ 1511 Trailer5TireInfoISO_sg_ISig_4 1 : Trailer5TireInfoISO_Temperature_ Trailer5TireInfoISO_Pressure_ISi Trailer5TireInfoISO_Leakage_ISig Trailer5TireInfoISO_PresSuff_ISi Trailer5TireInfoISO_PowerSupply_ Trailer5TireInfoISO_Warning_ISig Trailer5TireInfoISO_TireId_ISig_ Trailer5TireInfoISO_Active_ISig_;
SIG_GROUP_ 1509 Trailer4TireInfoISO_sg_ISig_4 1 : Trailer4TireInfoISO_Temperature_ Trailer4TireInfoISO_PresSuff_ISi Trailer4TireInfoISO_Leakage_ISig Trailer4TireInfoISO_PowerSupply_ Trailer4TireInfoISO_Warning_ISig Trailer4TireInfoISO_TireId_ISig_ Trailer4TireInfoISO_Pressure_ISi Trailer4TireInfoISO_Active_ISig_;
SIG_GROUP_ 1508 Trailer3TireInfoISO_sg_ISig_4 1 : Trailer3TireInfoISO_Active_ISig_ Trailer3TireInfoISO_Warning_ISig Trailer3TireInfoISO_TireId_ISig_ Trailer3TireInfoISO_Pressure_ISi Trailer3TireInfoISO_Temperature_ Trailer3TireInfoISO_Leakage_ISig Trailer3TireInfoISO_PowerSupply_ Trailer3TireInfoISO_PresSuff_ISi;
SIG_GROUP_ 41 PLCMsgStat_sg_ISig_4 1 : PLCMsgStat_MsgErrCode_ISig_4 PLCMsgStat_TxRetryCnt_ISig_4 PLCMsgStat_MsgStatus_ISig_4 PLCMsgStat_TxArbtrnFailCnt_ISig_;
SIG_GROUP_ 959 WhlSpdSenTothCnt456_sg_ISig_4 1 : WhlSpdSenTothCnt456_Axle6Left_IS WhlSpdSenTothCnt456_Axle5Right_I WhlSpdSenTothCnt456_Axle5Left_IS WhlSpdSenTothCnt456_Axle4Right_I WhlSpdSenTothCnt456_TimeStamp_IS WhlSpdSenTothCnt456_Axle6Right_I WhlSpdSenTothCnt456_Axle4Left_IS;
SIG_GROUP_ 832 WhlSpdSenTothCnt123_sg_ISig_4 1 : WhlSpdSenTothCnt123_TimeStamp_IS WhlSpdSenTothCnt123_Axle2Right_I WhlSpdSenTothCnt123_Axle3Right_I WhlSpdSenTothCnt123_Axle1Right_I WhlSpdSenTothCnt123_Axle1Left_IS WhlSpdSenTothCnt123_Axle2Left_IS WhlSpdSenTothCnt123_Axle3Left_IS;
SIG_GROUP_ 1501 Trailer2TireInfoISO_sg_ISig_4 1 : Trailer2TireInfoISO_PowerSupply_ Trailer2TireInfoISO_Temperature_ Trailer2TireInfoISO_PresSuff_ISi Trailer2TireInfoISO_Pressure_ISi Trailer2TireInfoISO_Warning_ISig Trailer2TireInfoISO_TireId_ISig_ Trailer2TireInfoISO_Leakage_ISig Trailer2TireInfoISO_Active_ISig_;
SIG_GROUP_ 1498 Trailer1TireInfoISO_sg_ISig_4 1 : Trailer1TireInfoISO_Leakage_ISig Trailer1TireInfoISO_Active_ISig_ Trailer1TireInfoISO_Warning_ISig Trailer1TireInfoISO_PowerSupply_ Trailer1TireInfoISO_PresSuff_ISi Trailer1TireInfoISO_Temperature_ Trailer1TireInfoISO_TireId_ISig_ Trailer1TireInfoISO_Pressure_ISi;
SIG_GROUP_ 1503 DiagFaultStat_WSGW_sg 1 : DiagFaultStat_WSGW_EcuAdr DiagFaultStat_WSGW_FailTB DiagFaultStat_WSGW_DtcIdA DiagFaultStat_WSGW_DtcIdB DiagFaultStat_WSGW_FailTA;
SIG_GROUP_ 1500 DiagFaultStat_RCIOM_sg 1 : DiagFaultStat_RCIOM_DtcIdB DiagFaultStat_RCIOM_FailTA DiagFaultStat_RCIOM_FailTB DiagFaultStat_RCIOM_DtcIdA DiagFaultStat_RCIOM_EcuAdr;
SIG_GROUP_ 1497 DiagFaultStat_GFHCM2_sg 1 : DiagFaultStat_GFHCM2_DtcIdA DiagFaultStat_GFHCM2_FailTB DiagFaultStat_GFHCM2_DtcIdB DiagFaultStat_GFHCM2_EcuAdr DiagFaultStat_GFHCM2_FailTA;
SIG_GROUP_ 1496 DiagFaultStat_GFHCM1_sg 1 : DiagFaultStat_GFHCM1_EcuAdr DiagFaultStat_GFHCM1_DtcIdB DiagFaultStat_GFHCM1_FailTB DiagFaultStat_GFHCM1_FailTA DiagFaultStat_GFHCM1_DtcIdA;
SIG_GROUP_ 1499 DiagFaultStat_FCIOM_sg 1 : DiagFaultStat_FCIOM_DtcIdA DiagFaultStat_FCIOM_FailTA DiagFaultStat_FCIOM_FailTB DiagFaultStat_FCIOM_DtcIdB DiagFaultStat_FCIOM_EcuAdr;
SIG_GROUP_ 1490 DiagFaultStat_CCIOM_sg 1 : DiagFaultStat_CCIOM_EcuAdr DiagFaultStat_CCIOM_FailTA DiagFaultStat_CCIOM_DtcIdB DiagFaultStat_CCIOM_FailTB DiagFaultStat_CCIOM_DtcIdA;
SIG_GROUP_ 1444 BatteryCapacityGrpAck_sg 1 : BatteryCapacityGrpAck_Pos3 BatteryCapacityGrpAck_Pos2 BatteryCapacityGrpAck_Pos1;
